VERSION ""

NS_ :

BS_:

BU_: SCCM RF_HUB PTS ORC OCM IC HCP HALF ETM ESM ESC EPS ECM EBCM DIAGNOST DASM CBC AirSusp TCM DTCM ELSDM

BO_ 3221225472 VECTOR__INDEPENDENT_SIG_MSG: 0 Vector__XXX
 SG_ CRC_10Eh : 56|8@1+ (1,0) [0|255] ""  DASM,ECM
 SG_ MC_10Eh : 52|4@1+ (1,0) [0|15] ""  DASM,ECM
 SG_ WhlTrq_Rq_As : 22|15@0+ (1,-7767) [-7767|24999] "Nm"  ORC,ECM
 SG_ WhlTrq_Rq_ESC : 6|15@0+ (1,-7767) [-7767|24999] "Nm"  ECM,DASM
 SG_ WhlTrqAct_Rq_AS : 23|1@1+ (1,0) [0|0] ""  ECM
 SG_ WhlTrqMax_Rq_ESC : 7|1@1+ (1,0) [0|0] ""  ECM,DASM
 SG_ WhlTrqMin_Rq_ESC : 51|1@1+ (1,0) [0|0] ""  ECM
 SG_ CRC_123h : 56|8@1+ (1,0) [0|255] ""  ESC,DASM
 SG_ M_MAX_AXLE : 4|13@0+ (4,-7767) [-7767|24993] ""  ESC,DASM
 SG_ M_MIN_AXLE : 36|13@0+ (4,-7767) [-7767|24993] ""  ESC,DASM
 SG_ M_STA_AXLE : 20|13@0+ (4,-7767) [-7767|24993] ""  ORC,ESC,DASM
 SG_ MC_123h : 52|4@1+ (1,0) [0|15] ""  ESC,DASM
 SG_ AXSStat : 4|2@1+ (1,0) [0|0] ""  HCP,ESC
 SG_ AYSStat : 6|2@1+ (1,0) [0|0] ""  ESC
 SG_ CRC_ORC_YRS_DATA : 56|8@1+ (1,0) [0|0] ""  ESC
 SG_ InternalError : 22|1@1+ (1,0) [0|0] ""  ESC
 SG_ LatAcceleration : 3|12@0+ (0.02,-40.96) [-40.96|40.92] "m/s²"  ESC
 SG_ LongAcceleration : 19|12@0+ (0.02,-40.96) [-40.96|40.92] "m/s²"  HCP,ESC
 SG_ MC_ORC_YRS_DATA : 52|4@1+ (1,0) [0|15] ""  ESC
 SG_ VoltageError : 23|1@1+ (1,0) [0|0] ""  ESC
 SG_ YawRate : 35|12@0+ (0.08,-163.84) [-163.84|163.68] "°/s"  ESC
 SG_ YRSStat : 20|2@1+ (1,0) [0|0] ""  ESC
 SG_ IMPACT_B : 1|1@1+ (1,0) [0|0] ""  ETM
 SG_ IMPACT_C : 2|1@1+ (1,0) [0|0] ""  ETM
 SG_ Impact_F : 5|1@1+ (1,0) [0|0] ""  ETM
 SG_ IMPACT_I : 9|1@1+ (1,0) [0|0] ""  ETM
 SG_ IMPACT_L : 11|1@1+ (1,0) [0|0] ""  ETM
 SG_ Impact_Tgl : 7|1@1+ (1,0) [0|0] ""  HCP,ETM,OCM,ECM,CBC
 SG_ IMPACT_X : 15|1@1+ (1,0) [0|0] ""  OCM,HCP,ETM,ECM,CBC
 SG_ ORC_Health : 23|1@1+ (1,0) [0|0] ""  HCP
 SG_ AirTemp_Outsd : 0|8@1+ (0.5,-40) [-40|85] "°C"  RF_HUB,EPS,ECM,DASM
 SG_ AMB_TEMP_AVG : 15|16@0+ (0.01,-40) [-40|85] "°C"  RF_HUB,PTS,OCM,ESC,EPS,ECM,DASM
 SG_ AMB_TEMP_VOLT : 24|8@1+ (0.019607843,0) [0|4.98] "Volts"  HCP,ECM
 SG_ BATT_VOLT : 48|8@1+ (0.1,0) [5|18] "Volts"  SCCM,RF_HUB,PTS,ORC,OCM,IC,HCP,HALF,ESM,ESC,EPS,ECM,EBCM,DASM
 SG_ FUEL_VOLT : 32|8@1+ (0.019607843,0) [0|4.98] "Volts"  IC,ECM
 SG_ FUEL_VOLT2 : 40|8@1+ (0.019607843,0) [0|4.98] "Volts"  IC
 SG_ rnd_04 : 32|8@1+ (1,0) [0|255] ""  CBC
 SG_ rnd_03 : 24|8@1+ (1,0) [0|255] ""  CBC
 SG_ rnd_02 : 16|8@1+ (1,0) [0|255] ""  CBC
 SG_ rnd_01 : 8|8@1+ (1,0) [0|255] ""  CBC
 SG_ f1_02 : 48|8@1+ (1,0) [0|255] ""  CBC
 SG_ f1_01 : 40|8@1+ (1,0) [0|255] ""  CBC
 SG_ ControlEncodingRq_HCP : 0|8@1+ (1,0) [0|0] ""  CBC
 SG_ MKKey2org22 : 16|8@1+ (1,0) [0|255] ""  ECM
 SG_ MKKey1org21 : 8|8@1+ (1,0) [0|255] ""  ECM
 SG_ MKKey_6 : 48|8@1+ (1,0) [0|255] ""  ECM
 SG_ MKKey_5 : 40|8@1+ (1,0) [0|255] ""  ECM
 SG_ MKKey_4 : 32|8@1+ (1,0) [0|255] ""  ECM
 SG_ MKKey_3 : 24|8@1+ (1,0) [0|255] ""  ECM
 SG_ ControlEncodingRsp : 0|8@1+ (1,0) [0|0] ""  ECM
 SG_ rnd_4 : 32|8@1+ (1,0) [0|255] ""  CBC
 SG_ rnd_3 : 24|8@1+ (1,0) [0|255] ""  CBC
 SG_ rnd_2 : 16|8@1+ (1,0) [0|255] ""  CBC
 SG_ rnd_1 : 8|8@1+ (1,0) [0|255] ""  CBC
 SG_ f1_2 : 48|8@1+ (1,0) [0|255] ""  CBC
 SG_ f1_1 : 40|8@1+ (1,0) [0|255] ""  CBC
 SG_ ControlEncodingRq : 0|8@1+ (1,0) [0|0] ""  CBC
 SG_ MKKey02org22 : 16|8@1+ (1,0) [0|255] ""  HCP
 SG_ MKKey01org21 : 8|8@1+ (1,0) [0|255] ""  HCP
 SG_ MKKey_06 : 48|8@1+ (1,0) [0|255] ""  HCP
 SG_ MKKey_05 : 40|8@1+ (1,0) [0|255] ""  HCP
 SG_ MKKey_04 : 32|8@1+ (1,0) [0|255] ""  HCP
 SG_ MKKey_03 : 24|8@1+ (1,0) [0|255] ""  HCP
 SG_ ControlEncoding_Rsp_HCP : 0|8@1+ (1,0) [0|0] ""  HCP
 SG_ ControlEncodingBCM : 0|8@1+ (1,0) [0|0] ""  RF_HUB
 SG_ MiniCrypt_Rnd : 31|32@0+ (1,0) [0|0] ""  RF_HUB
 SG_ MiniCryptFCode : 15|16@0+ (1,0) [0|0] ""  RF_HUB
 SG_ TxpAuthRequest : 63|1@1+ (1,0) [0|0] ""  RF_HUB
 SG_ TxpReadRequest : 62|1@1+ (1,0) [0|0] ""  RF_HUB
 SG_ MinicryptReceptionSts : 7|1@1+ (1,0) [0|0] ""  RF_HUB
 SG_ CodeCheckSts : 24|2@1+ (1,0) [0|0] ""  CBC
 SG_ ControlEncoding : 0|8@1+ (1,0) [0|0] ""  CBC
 SG_ MiniCryptGCode : 15|16@0+ (1,0) [0|0] ""  CBC
 SG_ ProgrammedSts : 26|1@1+ (1,0) [0|0] ""  CBC
 SG_ TxpFound : 31|1@1+ (1,0) [0|0] ""  CBC
 SG_ TxpID : 27|4@1+ (1,0) [0|0] ""  CBC
 SG_ DATA1 : 8|8@1+ (1,0) [0|0] ""  CBC
 SG_ DATA2 : 16|8@1+ (1,0) [0|0] ""  CBC
 SG_ DATA3 : 24|8@1+ (1,0) [0|0] ""  CBC
 SG_ DATA4 : 32|8@1+ (1,0) [0|0] ""  CBC
 SG_ DATA5 : 40|8@1+ (1,0) [0|0] ""  CBC
 SG_ DATA6 : 48|8@1+ (1,0) [0|0] ""  CBC
 SG_ DATA7 : 56|8@1+ (1,0) [0|0] ""  CBC
 SG_ FrameNumber : 0|4@1+ (1,0) [0|0] ""  CBC
 SG_ TotalFrameNumber : 4|4@1+ (1,0) [0|0] ""  CBC
 SG_ CRC_OCM_A1 : 56|8@1+ (1,0) [0|0] ""  ORC
 SG_ MC_OCM_A1 : 52|4@1+ (1,0) [0|15] ""  ORC
 SG_ PsgSeatOCFaultSts : 4|1@1+ (1,0) [0|0] ""  ORC
 SG_ PsgSeatOCSts : 0|4@1+ (1,0) [0|0] ""  ORC
 SG_ PsgSeatSBRSts : 8|4@1+ (1,0) [0|0] ""  ORC
 SG_ CRC_PRESF_CTRL_ESP : 56|8@1+ (1,0) [0|0] "" Vector__XXX
 SG_ MC_PRESF_CTRL_ESP : 52|4@1+ (1,0) [0|15] "" Vector__XXX
 SG_ BlockOffset : 0|8@1+ (1,0) [0|0] ""  ESC
 SG_ Character0 : 56|8@1+ (1,0) [0|0] ""  ESC
 SG_ Character1 : 48|8@1+ (1,0) [0|0] ""  ESC
 SG_ Character2 : 40|8@1+ (1,0) [0|0] ""  ESC
 SG_ Character3 : 32|8@1+ (1,0) [0|0] ""  ESC
 SG_ Character4 : 24|8@1+ (1,0) [0|0] ""  ESC
 SG_ Character5 : 16|8@1+ (1,0) [0|0] ""  ESC
 SG_ CLUType : 12|4@1+ (1,0) [0|0] ""  ESC
 SG_ PTRInfo : 8|4@1+ (1,0) [0|0] ""  ESC
 SG_ HCPCoachDisp : 40|8@1+ (1,-100) [-100|100] "%"  IC
 SG_ HCPCoachDispV : 30|1@1+ (1,0) [0|0] ""  IC
 SG_ HCPOutputPwr : 32|8@1+ (1,-100) [-100|100] "%"  IC
 SG_ HCPOutputPwrV : 29|1@1+ (1,0) [0|0] ""  IC
 SG_ HCPPopUpMessage1 : 8|1@1+ (1,0) [0|0] ""  IC
 SG_ HCPPopUpMessage2 : 9|1@1+ (1,0) [0|0] ""  IC
 SG_ HCPPopUpMessage3 : 10|1@1+ (1,0) [0|0] ""  IC
 SG_ HCPPopUpMessage4 : 11|1@1+ (1,0) [0|0] ""  IC
 SG_ HCPPopUpMessage5 : 12|1@1+ (1,0) [0|0] ""  IC
 SG_ HCPPopUpMessage6 : 13|1@1+ (1,0) [0|0] ""  IC
 SG_ HCPPopUpMessage7 : 14|1@1+ (1,0) [0|0] ""  IC
 SG_ HybSysEmsMlfAtv : 7|1@1+ (1,0) [0|0] "" Vector__XXX
 SG_ MIL_OnRq_HCP : 6|1@1+ (1,0) [0|0] ""  ECM
 SG_ CabinPreCondReqStat : 52|4@1+ (1,0) [0|0] ""  ETM
 SG_ ChargingLevel : 4|4@1+ (1,0) [0|0] ""  IC,ETM
 SG_ ChargingSysSts : 45|3@1+ (1,0) [0|0] ""  IC,ETM
 SG_ ChrgSysFault : 3|1@1+ (1,0) [0|0] ""  IC,ETM
 SG_ CompStat : 48|4@1+ (1,0) [0|0] ""  CBC
 SG_ DriveReady : 22|1@1+ (1,0) [0|0] ""  IC,DASM,CBC
 SG_ EstTimeofChrg_Lv1 : 20|13@0+ (1,0) [0|8190] "min"  IC,ETM
 SG_ EstTimeofChrg_Lv2 : 2|11@0+ (1,0) [0|2046] "min"  IC,ETM
 SG_ HtrCoreInletTemp : 32|8@1+ (1,-40) [-40|214] "°C"  ECM,CBC
 SG_ PrplsnSysAtv : 23|1@1+ (1,0) [0|0] ""  RF_HUB,PTS,IC,ETM,ESC,EPS,ECM,CBC
 SG_ CRC_EPB_A1 : 16|8@1+ (1,0) [0|0] ""  PTS,HCP,EPS,ECM,DASM
 SG_ EPBHoldSts : 9|3@1+ (1,0) [0|0] ""  PTS,ORC,HCP,ECM,DASM,CBC
 SG_ MC_EPB_A1 : 12|4@1+ (1,0) [0|15] ""  PTS,HCP,EPS,ECM,DASM
 SG_ UConnReq : 0|5@1+ (1,0) [0|0] ""  RF_HUB
 SG_ UConnReqAuthCode : 15|16@0+ (1,0) [0|0] ""  RF_HUB
 SG_ UConnReqFOBNum : 24|4@1+ (1,0) [0|0] ""  RF_HUB
 SG_ BatPwrUsage : 32|8@1+ (1,-125) [-125|130] "kW"  IC
 SG_ BatPwrUsage_V : 23|1@1+ (1,0) [0|0] ""  IC
 SG_ Est_Range : 40|8@1+ (1,0) [0|254] "km"  IC,ETM
 SG_ HEV_EVT_MD : 19|1@1+ (1,0) [0|0] ""  IC,ETM,CBC
 SG_ HEV_LMP_RQ : 0|2@1+ (1,0) [0|0] ""  ORC,IC,ETM
 SG_ R134a_PressSts : 48|9@0+ (0.1,0) [0|40] "bar"  CBC
 SG_ ElecClntHtrInletTemp : 32|8@1+ (1,-40) [-40|214] "°C"  ECM
 SG_ ElecCoolantHtrPwr : 24|8@1+ (0.04,0) [0|10.16] "kW"  ECM,CBC
 SG_ FRfShVlvSts : 23|1@1+ (1,0) [0|0] ""  CBC
 SG_ HTAuxPmpMontrngRPM : 19|2@1+ (1,0) [0|0] ""  ECM
 SG_ HTAuxPmpRPMAct : 0|8@1+ (24,0) [0|6096] "rpm"  ECM,CBC
 SG_ HTCabVlvPosn : 8|7@1+ (1,0) [0|100] "%"  ECM,CBC
 SG_ HTShtOffVlvReq : 22|1@1+ (1,0) [0|0] ""  ECM,CBC
 SG_ HVBatCritCondT : 21|1@1+ (1,0) [0|0] ""  CBC
 SG_ EC_BU_CBC15A : 2|6@1+ (1,0) [0|0] ""  CBC
 SG_ EC_BU_CBC15B : 15|40@0+ (1,0) [0|0] ""  CBC
 SG_ EC_BU_ECUCfg15_Stat : 0|2@1+ (1,0) [0|0] ""  CBC
 SG_ EC_BU_Suspension : 55|16@0+ (1,0) [0|0] ""  CBC
 SG_ EC_BU_AudTel3A : 2|6@1+ (1,0) [0|0] ""  CBC
 SG_ EC_BU_AudTel3B : 15|56@0+ (1,0) [0|0] ""  CBC
 SG_ EC_BU_ECUCfg16_Stat : 0|2@1+ (1,0) [0|0] ""  CBC
 SG_ EC_BU_ECUCfg17_Stat : 0|2@1+ (1,0) [0|0] ""  CBC
 SG_ EC_BU_PTS : 56|8@1+ (1,0) [0|0] ""  CBC
 SG_ AutoParkSts : 25|2@1+ (1,0) [0|0] ""  CBC
 SG_ ClampForce : 7|16@0+ (1,0) [0|65535] "N"  ORC
 SG_ CRC_EPB_1 : 56|8@1+ (1,0) [0|0] ""  IC,EPS,DASM
 SG_ EPBSts : 24|1@1+ (1,0) [0|0] ""  DASM
 SG_ EPBWarningLampReq : 46|2@1+ (1,0) [0|0] ""  ORC,IC
 SG_ FunctionLamp : 44|2@1+ (1,0) [0|0] ""  IC
 SG_ MC_EPB_1 : 52|4@1+ (1,0) [0|15] ""  IC,EPS,DASM
 SG_ ServiceModeSts : 30|1@1+ (1,0) [0|0] ""  CBC
 SG_ TextDisplay : 32|5@1+ (1,0) [0|0] ""  IC,CBC
 SG_ CFG_FEATURE : 0|8@1+ (1,0) [0|0] ""  RF_HUB,PTS,IC,HALF,ESC,ECM,DASM
 SG_ CFG_SET : 16|8@1+ (1,0) [0|255] ""  RF_HUB,PTS,IC,HALF,ESC,ECM,DASM
 SG_ CFG_STAT_RQ : 8|2@1+ (1,0) [0|0] ""  RF_HUB,PTS,IC,HALF,ESC,ECM,DASM
 SG_ AHB_ENBL : 36|1@1+ (1,0) [0|0] "" Vector__XXX
 SG_ ChargeReq : 55|1@1+ (1,0) [0|0] ""  IC,HCP
 SG_ HVAC_CLNT_FLW_MIN : 40|8@1+ (0.521555,0) [0.521555|131.953415] "LpM" Vector__XXX
 SG_ ICS_btn_16 : 51|1@1+ (1,0) [0|0] ""  PTS
 SG_ ICS_btn_17 : 52|1@1+ (1,0) [0|0] ""  PTS
 SG_ ICS_btn_18 : 53|1@1+ (1,0) [0|0] ""  HALF
 SG_ phone_pop_up_active : 30|1@1+ (1,0) [0|0] ""  IC
 SG_ PLG_Stat : 0|4@1+ (1,0) [0|0] ""  IC
 SG_ TRAC_PSD : 19|1@1+ (1,0) [0|0] ""  IC,ESC
 SG_ ECM_APPL2 : 7|64@0+ (1,0) [0|0] ""  ECM
 SG_ ECM_APPL1 : 7|64@0+ (1,0) [0|0] ""  DIAGNOST
 SG_ BatPwrUsageDisp : 8|8@1+ (1,-125) [-125|130] "kW"  ETM
 SG_ BatPwrUsageDisp_V : 44|1@1+ (1,0) [0|0] ""  ETM
 SG_ EngPwrUsageDisp : 49|10@0+ (1,0) [0|1023] "kW"  IC,ETM
 SG_ EngPwrUsageDisp_V : 45|1@1+ (1,0) [0|0] ""  IC,ETM
 SG_ HVACPwrUsageDisp : 24|7@1+ (1,0) [0|127] "kW"  ETM
 SG_ HVACPwrUsageDisp_V : 46|1@1+ (1,0) [0|0] ""  ETM
 SG_ HVBatSOC_HCP : 32|8@1+ (0.3922,0) [0|100] "%"  IC,ETM
 SG_ HVBatSOCV_HCP : 47|1@1+ (1,0) [0|0] ""  IC,ETM
 SG_ MtrPwrUsageDisp : 0|8@1+ (1,-125) [-125|130] "kW"  IC
 SG_ MtrPwrUsageDisp_V : 43|1@1+ (1,0) [0|0] ""  IC
 SG_ ECM_APPL3 : 7|64@0+ (1,0) [0|0] ""  DIAGNOST
 SG_ ECM_APPL4 : 7|64@0+ (1,0) [0|0] ""  DIAGNOST
 SG_ VC_BU_ABSM : 25|1@1+ (1,0) [0|0] ""  CBC
 SG_ VC_BU_ACC_Type : 19|2@1+ (1,0) [0|0] ""  CBC
 SG_ VC_BU_AS_ERS : 14|2@1+ (1,0) [0|0] ""  CBC
 SG_ VC_BU_AxleLockerPrsnt : 26|2@1+ (1,0) [0|0] ""  CBC
 SG_ VC_BU_DampingPrsnt : 22|1@1+ (1,0) [0|0] ""  CBC
 SG_ VC_BU_DST_Present : 5|1@1+ (1,0) [0|0] ""  CBC
 SG_ VC_BU_eShifter_Prsnt : 7|1@1+ (1,0) [0|0] ""  CBC
 SG_ VC_BU_FullSpeedRange_FCW : 18|1@1+ (1,0) [0|0] ""  CBC
 SG_ VC_BU_HybridType : 36|3@1+ (1,0) [0|0] ""  CBC
 SG_ VC_BU_LDW : 2|1@1+ (1,0) [0|0] ""  CBC
 SG_ VC_BU_PBTyp : 29|3@1+ (1,0) [0|0] ""  CBC
 SG_ VC_BU_PdlsMdPrsnt : 4|1@1+ (1,0) [0|0] ""  CBC
 SG_ VC_BU_RedKey : 24|1@1+ (1,0) [0|0] ""  CBC
 SG_ VC_BU_STP_PRSNT : 6|1@1+ (1,0) [0|0] ""  CBC
 SG_ VC_BU_SUNR_Prsnt : 47|1@1+ (1,0) [0|0] ""  CBC
 SG_ VC_BU_SuspPrsnt : 21|1@1+ (1,0) [0|0] ""  CBC
 SG_ VC_BU_SVC_Prsnt : 17|1@1+ (1,0) [0|0] ""  CBC
 SG_ VC_BU_TeenKey : 16|1@1+ (1,0) [0|0] ""  CBC
 SG_ VC_BU_TPMS_Configuration : 32|3@1+ (1,0) [0|0] ""  CBC
 SG_ VC_BU_Trans_Equipped : 28|1@1+ (1,0) [0|0] ""  CBC
 SG_ VC_BU_Trans_N_Hold_Prsnt : 23|1@1+ (1,0) [0|0] ""  CBC
 SG_ VC_BU_TransType : 8|6@1+ (1,0) [0|0] ""  CBC
 SG_ VC_BU_TrnsDrvMdPrsnt : 3|1@1+ (1,0) [0|0] ""  CBC
 SG_ VC_BU_TSBM_Prsnt : 39|1@1+ (1,0) [0|0] ""  CBC
 SG_ VC_BU_VehCfg7_Stat : 0|2@1+ (1,0) [0|0] ""  CBC
 SG_ GPS_Date_Day : 24|8@1+ (1,0) [1|31] "Days"  ECM
 SG_ GPS_Date_Month : 16|8@1+ (1,0) [1|12] "Months"  ECM
 SG_ GPS_Date_Year : 7|16@0+ (1,0) [0|65534] "Years"  ECM
 SG_ GPS_UTC_Hour : 32|8@1+ (1,0) [0|23] "h" Vector__XXX
 SG_ GPS_UTC_Minute : 40|8@1+ (1,0) [0|59] "min" Vector__XXX
 SG_ GPS_UTC_Second : 55|16@0+ (0.01,0) [0|59.99] "s" Vector__XXX
 SG_ ECM_APPL5 : 7|64@0+ (1,0) [0|0] ""  DIAGNOST
 SG_ NET_CFG_STAT_ePT : 0|2@1+ (1,0) [0|0] ""  RF_HUB,ORC,HCP,ESC,EBCM
 SG_ NetCfg_AHCP_ePT : 9|1@1+ (1,0) [0|0] ""  RF_HUB
 SG_ NetCfg_APM_ePT : 13|1@1+ (1,0) [0|0] ""  RF_HUB
 SG_ NetCfg_BPCM_ePT : 12|1@1+ (1,0) [0|0] ""  RF_HUB
 SG_ NetCfg_BSMO_ePT : 14|1@1+ (1,0) [0|0] ""  RF_HUB
 SG_ NetCfg_EAC_ePT : 11|1@1+ (1,0) [0|0] ""  RF_HUB
 SG_ NetCfg_EBCM_ePT : 2|1@1+ (1,0) [0|0] ""  RF_HUB
 SG_ NetCfg_ECM_ePT : 6|1@1+ (1,0) [0|0] ""  RF_HUB
 SG_ NetCfg_ESC_ePT : 5|1@1+ (1,0) [0|0] ""  RF_HUB
 SG_ NetCfg_ESM_ePT : 4|1@1+ (1,0) [0|0] ""  RF_HUB
 SG_ NetCfg_HCP_ePT : 7|1@1+ (1,0) [0|0] ""  RF_HUB
 SG_ NetCfg_OBCM_ePT : 8|1@1+ (1,0) [0|0] ""  RF_HUB
 SG_ NetCfg_ORC_ePT : 3|1@1+ (1,0) [0|0] ""  RF_HUB
 SG_ NetCfg_SCA_ePT : 10|1@1+ (1,0) [0|0] ""  RF_HUB
 SG_ BU_NetCfg_SCA_ePT : 10|1@1+ (1,0) [0|0] ""  CBC
 SG_ BU_NetCfg_ORC_ePT : 3|1@1+ (1,0) [0|0] ""  CBC
 SG_ BU_NetCfg_OBCM_ePT : 8|1@1+ (1,0) [0|0] ""  CBC
 SG_ BU_NetCfg_HCP_ePT : 7|1@1+ (1,0) [0|0] ""  CBC
 SG_ BU_NetCfg_ESM_ePT : 4|1@1+ (1,0) [0|0] ""  CBC
 SG_ BU_NetCfg_ESC_ePT : 5|1@1+ (1,0) [0|0] ""  CBC
 SG_ BU_NetCfg_ECM_ePT : 6|1@1+ (1,0) [0|0] ""  CBC
 SG_ BU_NetCfg_EBCM_ePT : 2|1@1+ (1,0) [0|0] ""  CBC
 SG_ BU_NetCfg_EAC_ePT : 11|1@1+ (1,0) [0|0] ""  CBC
 SG_ BU_NetCfg_BSMO_ePT : 14|1@1+ (1,0) [0|0] ""  CBC
 SG_ BU_NetCfg_BPCM_ePT : 12|1@1+ (1,0) [0|0] ""  CBC
 SG_ BU_NetCfg_APM_ePT : 13|1@1+ (1,0) [0|0] ""  CBC
 SG_ BU_NetCfg_AHCP_ePT : 9|1@1+ (1,0) [0|0] ""  CBC
 SG_ BU_NET_CFG_STAT_ePT : 0|2@1+ (1,0) [0|0] ""  CBC
 SG_ ECM_APPL6 : 7|64@0+ (1,0) [0|0] ""  DIAGNOST
 SG_ DateTmFormat2 : 0|3@1+ (1,0) [0|0] ""  IC
 SG_ WeekdayTmHour_End : 16|5@1+ (1,0) [0|24] "Hours"  IC
 SG_ WeekdayTmHour_Start : 8|5@1+ (1,0) [0|24] "Hours"  IC
 SG_ WeekdayTmMinute_End : 21|3@1+ (1,0) [0|0] "min"  IC
 SG_ WeekdayTmMinute_Start : 13|3@1+ (1,0) [0|0] "min"  IC
 SG_ WeekendTmHour_End : 32|5@1+ (1,0) [0|24] "Hours"  IC
 SG_ WeekendTmHour_Start : 24|5@1+ (1,0) [0|24] "Hours"  IC
 SG_ WeekendTmMinute_End : 37|3@1+ (1,0) [0|0] "min"  IC
 SG_ WeekendTmMinute_Start : 29|3@1+ (1,0) [0|0] "min"  IC
 SG_ ECM_APPL7 : 7|64@0+ (1,0) [0|0] ""  DIAGNOST
 SG_ VC_BU_ACC_DLY_CSO : 24|1@1+ (1,0) [0|0] ""  CBC
 SG_ VC_BU_AFLS_CSO : 25|1@1+ (1,0) [0|0] ""  CBC
 SG_ VC_BU_AMB_DMR_CSO : 26|1@1+ (1,0) [0|0] ""  CBC
 SG_ VC_BU_ASCM_TJ_CSO : 27|1@1+ (1,0) [0|0] ""  CBC
 SG_ VC_BU_ASCM_WRN_CSO : 28|1@1+ (1,0) [0|0] ""  CBC
 SG_ VC_BU_AUTO_AERO_CSO : 29|1@1+ (1,0) [0|0] ""  CBC
 SG_ VC_BU_AUTO_HB_CSO : 30|1@1+ (1,0) [0|0] ""  CBC
 SG_ VC_BU_AUTO_PRK_CSO : 31|1@1+ (1,0) [0|0] ""  CBC
 SG_ VC_BU_AUX_SWS_CSO : 18|2@1+ (1,0) [0|0] ""  CBC
 SG_ VC_BU_BLIND_SPOT_CSO : 32|1@1+ (1,0) [0|0] ""  CBC
 SG_ VC_BU_CAPACITY_CSO : 33|1@1+ (1,0) [0|0] ""  CBC
 SG_ VC_BU_CHMSL_LINE_CSO : 15|1@1+ (1,0) [0|0] ""  CBC
 SG_ VC_BU_CLK_DSP_CSO : 34|1@1+ (1,0) [0|0] ""  CBC
 SG_ VC_BU_CMP_CAL_CSO : 35|1@1+ (1,0) [0|0] ""  CBC
 SG_ VC_BU_CMP_VAR_CSO : 36|1@1+ (1,0) [0|0] ""  CBC
 SG_ VC_BU_CMRA_GRDLNS_CSO : 20|2@1+ (1,0) [0|0] ""  CBC
 SG_ VC_BU_CONS_CSO : 37|1@1+ (1,0) [0|0] ""  CBC
 SG_ VC_BU_DCS_CSO : 16|2@1+ (1,0) [0|0] ""  CBC
 SG_ VC_BU_DISTANCE_CSO : 38|1@1+ (1,0) [0|0] ""  CBC
 SG_ VC_BU_DR_LK_CSO : 39|1@1+ (1,0) [0|0] ""  CBC
 SG_ VC_BU_DR_UNLK_CSO : 40|1@1+ (1,0) [0|0] ""  CBC
 SG_ VC_BU_DRL_CSO : 41|1@1+ (1,0) [0|0] ""  CBC
 SG_ VC_BU_EASY_EXIT_CSO : 42|1@1+ (1,0) [0|0] ""  CBC
 SG_ VC_BU_ENTRY_EXIT_CSO : 43|1@1+ (1,0) [0|0] ""  CBC
 SG_ VC_BU_EPB_SERV_CSO : 44|1@1+ (1,0) [0|0] ""  CBC
 SG_ VC_BU_EPS_CSO : 7|1@1+ (1,0) [0|0] ""  CBC
 SG_ VC_BU_FCW_BRK_CSO : 10|1@1+ (1,0) [0|0] ""  CBC
 SG_ VC_BU_FCW_CSO : 8|2@1+ (1,0) [0|0] ""  CBC
 SG_ VC_BU_FLSH_LMP_LK_CSO : 45|1@1+ (1,0) [0|0] ""  CBC
 SG_ VC_BU_HL_DRP_CSO : 46|1@1+ (1,0) [0|0] ""  CBC
 SG_ VC_BU_HL_OFF_DLY_CSO : 47|1@1+ (1,0) [0|0] ""  CBC
 SG_ VC_BU_HL_WPR_CSO : 48|1@1+ (1,0) [0|0] ""  CBC
 SG_ VC_BU_HRN_RMT_LK_CSO : 11|2@1+ (1,0) [0|0] ""  CBC
 SG_ VC_BU_HRN_RMT_LWR_CSO : 14|1@1+ (1,0) [0|0] ""  CBC
 SG_ VC_BU_HRN_RMT_ST_CSO : 13|1@1+ (1,0) [0|0] ""  CBC
 SG_ VC_BU_HSA_CSO : 49|1@1+ (1,0) [0|0] ""  CBC
 SG_ VC_BU_ILL_APPRCH_CSO : 50|1@1+ (1,0) [0|0] ""  CBC
 SG_ VC_BU_LDW_TRQ_CSO : 51|1@1+ (1,0) [0|0] ""  CBC
 SG_ VC_BU_LDW_WRN_CSO : 52|1@1+ (1,0) [0|0] ""  CBC
 SG_ VC_BU_LGHT_RMT_LWR_CSO : 53|1@1+ (1,0) [0|0] ""  CBC
 SG_ VC_BU_NAV_TRN_CSO : 54|1@1+ (1,0) [0|0] ""  CBC
 SG_ VC_BU_PE_CSO : 55|1@1+ (1,0) [0|0] ""  CBC
 SG_ VC_BU_PER_SHFT_ENBL_CSO : 56|1@1+ (1,0) [0|0] ""  CBC
 SG_ VC_BU_PER_SHFT_RPM_CSO : 57|1@1+ (1,0) [0|0] ""  CBC
 SG_ VC_BU_PLG_CHM_CSO : 58|1@1+ (1,0) [0|0] ""  CBC
 SG_ VC_BU_POLICE_PE_CSO : 23|1@1+ (1,0) [0|0] ""  CBC
 SG_ VC_BU_POWER_CSO : 59|1@1+ (1,0) [0|0] ""  CBC
 SG_ VC_BU_PRESSURE_CSO : 60|1@1+ (1,0) [0|0] ""  CBC
 SG_ VC_BU_PRK_AST_BRK_CSO : 4|1@1+ (1,0) [0|0] ""  CBC
 SG_ VC_BU_PRK_AST_CSO : 2|2@1+ (1,0) [0|0] ""  CBC
 SG_ VC_BU_PRK_FT_VOL_CSO : 5|1@1+ (1,0) [0|0] ""  CBC
 SG_ VC_BU_PRK_RR_VOL_CSO : 6|1@1+ (1,0) [0|0] ""  CBC
 SG_ VC_BU_PTO_CSO : 61|1@1+ (1,0) [0|0] ""  CBC
 SG_ VC_BU_RAIN_WPR_CSO : 62|1@1+ (1,0) [0|0] ""  CBC
 SG_ VC_BU_REAR_CMRA_CSO : 63|1@1+ (1,0) [0|0] ""  CBC
 SG_ VC_BU_VehCfgCSO1_Stat : 0|2@1+ (1,0) [0|0] ""  CBC
 SG_ VC_BU_AIRBAG_ON_CSO : 46|1@1+ (1,0) [0|0] ""  CBC
 SG_ VC_BU_EPB_ON_CSO : 45|1@1+ (1,0) [0|0] ""  CBC
 SG_ VC_BU_FCW_SW_CSO : 47|1@1+ (1,0) [0|0] ""  CBC
 SG_ VC_BU_FLSH_LMP_SLDR_CSO : 40|1@1+ (1,0) [0|0] ""  CBC
 SG_ VC_BU_FUEL_SAV_CSO : 14|1@1+ (1,0) [0|0] ""  CBC
 SG_ VC_BU_HANDS_FREE_LFT_CSO : 18|1@1+ (1,0) [0|0] ""  CBC
 SG_ VC_BU_HANDS_FREE_SLDR_CSO : 19|1@1+ (1,0) [0|0] ""  CBC
 SG_ VC_BU_HOLD_N_GO_CSO : 16|1@1+ (1,0) [0|0] ""  CBC
 SG_ VC_BU_LDW_ON_CSO : 43|1@1+ (1,0) [0|0] ""  CBC
 SG_ VC_BU_PADDLE_SHIFT_CSO : 39|1@1+ (1,0) [0|0] ""  CBC
 SG_ VC_BU_PRK_ASST_TYPE_CSO : 44|1@1+ (1,0) [0|0] ""  CBC
 SG_ VC_BU_PWR_FLD_MRR_CSO : 17|1@1+ (1,0) [0|0] ""  CBC
 SG_ VC_BU_RDY_DRV_CSO : 55|1@1+ (1,0) [0|0] ""  CBC
 SG_ VC_BU_REAR_CMRA_DLY_CSO : 2|1@1+ (1,0) [0|0] ""  CBC
 SG_ VC_BU_RKE_MEM_CSO : 3|1@1+ (1,0) [0|0] ""  CBC
 SG_ VC_BU_RKE_UNLK_CSO : 4|1@1+ (1,0) [0|0] ""  CBC
 SG_ VC_BU_SLD_DR_ALRT_CSO : 22|1@1+ (1,0) [0|0] ""  CBC
 SG_ VC_BU_SLD_DR_CHM_CSO : 37|1@1+ (1,0) [0|0] ""  CBC
 SG_ VC_BU_SPEED_CSO : 5|1@1+ (1,0) [0|0] ""  CBC
 SG_ VC_BU_SPEED_WARNING_CSO : 41|2@1+ (1,0) [0|0] ""  CBC
 SG_ VC_BU_SVC_DELAY_CSO : 21|1@1+ (1,0) [0|0] ""  CBC
 SG_ VC_BU_SVC_GRIDLINES_CSO : 20|1@1+ (1,0) [0|0] ""  CBC
 SG_ VC_BU_TEEN_AUTO_HB_CSO : 33|1@1+ (1,0) [0|0] ""  CBC
 SG_ VC_BU_TEEN_BLIND_SPOT_CSO : 31|1@1+ (1,0) [0|0] ""  CBC
 SG_ VC_BU_TEEN_FCW_BRK_CSO : 24|1@1+ (1,0) [0|0] ""  CBC
 SG_ VC_BU_TEEN_FCW_SENS_CSO : 23|1@1+ (1,0) [0|0] ""  CBC
 SG_ VC_BU_TEEN_FT_PRK_VOL_CSO : 26|1@1+ (1,0) [0|0] ""  CBC
 SG_ VC_BU_TEEN_FUEL_POPUP_CSO : 30|1@1+ (1,0) [0|0] ""  CBC
 SG_ VC_BU_TEEN_FUEL_WRN_CSO : 29|1@1+ (1,0) [0|0] ""  CBC
 SG_ VC_BU_TEEN_LGHT_WPR_CSO : 34|1@1+ (1,0) [0|0] ""  CBC
 SG_ VC_BU_TEEN_MAX_SPEED_CSO : 28|1@1+ (1,0) [0|0] ""  CBC
 SG_ VC_BU_TEEN_PLG_CHIME_CSO : 36|1@1+ (1,0) [0|0] ""  CBC
 SG_ VC_BU_TEEN_PRK_ASST_CSO : 25|1@1+ (1,0) [0|0] ""  CBC
 SG_ VC_BU_TEEN_RAIN_WPR_CSO : 32|1@1+ (1,0) [0|0] ""  CBC
 SG_ VC_BU_TEEN_RR_PRK_VOL_CSO : 27|1@1+ (1,0) [0|0] ""  CBC
 SG_ VC_BU_TEEN_SLD_DR_ALRT_CSO : 35|1@1+ (1,0) [0|0] ""  CBC
 SG_ VC_BU_TEEN_SLD_DR_CHM_CSO : 38|1@1+ (1,0) [0|0] ""  CBC
 SG_ VC_BU_TEMP_CSO : 15|1@1+ (1,0) [0|0] ""  CBC
 SG_ VC_BU_TLT_MRR_CSO : 6|1@1+ (1,0) [0|0] ""  CBC
 SG_ VC_BU_TORQUE_CSO : 7|1@1+ (1,0) [0|0] ""  CBC
 SG_ VC_BU_TRLR_CSO : 8|1@1+ (1,0) [0|0] ""  CBC
 SG_ VC_BU_TRLR_NAME_CSO : 9|1@1+ (1,0) [0|0] ""  CBC
 SG_ VC_BU_TRLR_TYPE_CSO : 10|1@1+ (1,0) [0|0] ""  CBC
 SG_ VC_BU_TRNS_MD_CSO : 11|1@1+ (1,0) [0|0] ""  CBC
 SG_ VC_BU_US_METRIC_CSO : 12|1@1+ (1,0) [0|0] ""  CBC
 SG_ VC_BU_VehCfgCSO2_Stat : 0|2@1+ (1,0) [0|0] ""  CBC
 SG_ VC_BU_WHL_ALGN_CSO : 13|1@1+ (1,0) [0|0] ""  CBC
 SG_ NAV_GrpNum : 4|4@1+ (1,1) [1|16] "Group"  IC
 SG_ NAV_GrpTyp : 8|6@1+ (1,0) [1|40] "Text"  IC
 SG_ NAV_HiGrpMark : 14|1@1+ (1,0) [0|0] ""  IC
 SG_ NAV_TEXT : 23|48@0+ (1,0) [0|0] ""  IC
 SG_ Electric_Dist_Miles : 1|10@0+ (1,0) [0|999] "Mile"  ETM
 SG_ Hybrid_Dist_Miles : 17|10@0+ (1,0) [0|999] "Mile"  ETM
 SG_ Electric_Dist_Kilometers : 1|10@0+ (1,0) [0|999] "km"  ETM
 SG_ Hybrid_Dist_Kilometers : 17|10@0+ (1,0) [0|999] "km"  ETM
 SG_ EC_BU_ECUCfg14_Stat : 0|2@1+ (1,0) [0|0] ""  CBC
 SG_ EC_BU_CBC14B : 15|56@0+ (1,0) [0|0] ""  CBC
 SG_ EC_BU_CBC14A : 2|6@1+ (1,0) [0|0] ""  CBC
 SG_ EC_BU_ECUCfg13_Stat : 0|2@1+ (1,0) [0|0] ""  CBC
 SG_ EC_BU_CBC13B : 15|56@0+ (1,0) [0|0] ""  CBC
 SG_ EC_BU_CBC13A : 2|6@1+ (1,0) [0|0] ""  CBC
 SG_ EC_BU_ECUCfg12_Stat : 0|2@1+ (1,0) [0|0] ""  CBC
 SG_ EC_BU_Cluster5C : 39|32@0+ (1,0) [0|0] ""  CBC
 SG_ EC_BU_Cluster5B : 15|24@0+ (1,0) [0|0] ""  CBC
 SG_ EC_BU_Cluster5A : 2|6@1+ (1,0) [0|0] ""  CBC
 SG_ EC_BU_ECUCfg11_Stat : 0|2@1+ (1,0) [0|0] ""  CBC
 SG_ EC_BU_CBC11 : 39|32@0+ (1,0) [0|0] ""  CBC
 SG_ EC_BU_CBC10B : 15|24@0+ (1,0) [0|0] ""  CBC
 SG_ EC_BU_CBC10A : 2|6@1+ (1,0) [0|0] ""  CBC
 SG_ EC_BU_ECUCfg10_Stat : 0|2@1+ (1,0) [0|0] ""  CBC
 SG_ EC_BU_Cluster4 : 39|32@0+ (1,0) [0|0] ""  CBC
 SG_ EC_BU_Cluster3B : 15|24@0+ (1,0) [0|0] ""  CBC
 SG_ EC_BU_Cluster3A : 2|6@1+ (1,0) [0|0] ""  CBC
 SG_ EC_BU_ITM : 55|16@0+ (1,0) [0|0] ""  CBC
 SG_ EC_BU_ECUCfg9_Stat : 0|2@1+ (1,0) [0|0] ""  CBC
 SG_ EC_BU_CBC9B : 39|16@0+ (1,0) [0|0] ""  CBC
 SG_ EC_BU_CBC9A2 : 15|24@0+ (1,0) [0|0] ""  CBC
 SG_ EC_BU_CBC9A1 : 2|6@1+ (1,0) [0|0] ""  CBC
 SG_ BU_NetCfg_VTM : 13|1@1+ (1,0) [0|0] ""  CBC
 SG_ BU_NetCfg_VSIM : 22|1@1+ (1,0) [0|0] ""  CBC
 SG_ BU_NetCfg_VRM : 36|1@1+ (1,0) [0|0] ""  CBC
 SG_ BU_NetCfg_VES3_I : 29|1@1+ (1,0) [0|0] ""  CBC
 SG_ BU_NetCfg_VES2_I : 28|1@1+ (1,0) [0|0] ""  CBC
 SG_ BU_NetCfg_TMM : 33|1@1+ (1,0) [0|0] ""  CBC
 SG_ BU_NetCfg_TGW : 20|1@1+ (1,0) [0|0] ""  CBC
 SG_ BU_NetCfg_TBM : 38|1@1+ (1,0) [0|0] ""  CBC
 SG_ BU_NetCfg_RBSS : 2|1@1+ (1,0) [0|0] ""  CBC
 SG_ BU_NetCfg_RBC : 18|1@1+ (1,0) [0|0] ""  CBC
 SG_ BU_NetCfg_PTCM : 17|1@1+ (1,0) [0|0] ""  CBC
 SG_ BU_NetCfg_PSD_RT : 15|1@1+ (1,0) [0|0] ""  CBC
 SG_ BU_NetCfg_PSD_LT : 14|1@1+ (1,0) [0|0] ""  CBC
 SG_ BU_NetCfg_PLG : 12|1@1+ (1,0) [0|0] ""  CBC
 SG_ BU_NetCfg_MSM_PASS : 35|1@1+ (1,0) [0|0] ""  CBC
 SG_ BU_NetCfg_MSM : 11|1@1+ (1,0) [0|0] ""  CBC
 SG_ BU_NetCfg_ITM : 23|1@1+ (1,0) [0|0] ""  CBC
 SG_ BU_NetCfg_ICS_R : 34|1@1+ (1,0) [0|0] ""  CBC
 SG_ BU_NetCfg_ICS_I : 27|1@1+ (1,0) [0|0] ""  CBC
 SG_ BU_NetCfg_HVAC_R : 31|1@1+ (1,0) [0|0] ""  CBC
 SG_ BU_NetCfg_HVAC : 10|1@1+ (1,0) [0|0] ""  CBC
 SG_ BU_NetCfg_HFM_CTM : 26|1@1+ (1,0) [0|0] ""  CBC
 SG_ BU_NetCfg_FSM : 16|1@1+ (1,0) [0|0] ""  CBC
 SG_ BU_NetCfg_DVD_CDM : 25|1@1+ (1,0) [0|0] ""  CBC
 SG_ BU_NetCfg_DTV : 19|1@1+ (1,0) [0|0] ""  CBC
 SG_ BU_NetCfg_DCSD : 37|1@1+ (1,0) [0|0] ""  CBC
 SG_ BU_NetCfg_DCM_RR : 9|1@1+ (1,0) [0|0] ""  CBC
 SG_ BU_NetCfg_DCM_RL : 8|1@1+ (1,0) [0|0] ""  CBC
 SG_ BU_NetCfg_DCM_PASS : 7|1@1+ (1,0) [0|0] ""  CBC
 SG_ BU_NetCfg_DCM_DR : 6|1@1+ (1,0) [0|0] ""  CBC
 SG_ BU_NetCfg_CVPM : 32|1@1+ (1,0) [0|0] ""  CBC
 SG_ BU_NetCfg_CSWM : 5|1@1+ (1,0) [0|0] ""  CBC
 SG_ BU_NetCfg_CRSM : 30|1@1+ (1,0) [0|0] ""  CBC
 SG_ BU_NetCfg_CLOCK : 21|1@1+ (1,0) [0|0] ""  CBC
 SG_ BU_NetCfg_CBC_IN : 4|1@1+ (1,0) [0|0] ""  CBC
 SG_ BU_NetCfg_BSM : 3|1@1+ (1,0) [0|0] ""  CBC
 SG_ BU_NetCfg_ANC_I : 39|1@1+ (1,0) [0|0] ""  CBC
 SG_ BU_NetCfg_AMP_I : 24|1@1+ (1,0) [0|0] ""  CBC
 SG_ BU_NET_CFG_STAT_INT : 0|2@1+ (1,0) [0|0] ""  CBC
 SG_ BU_NetCfg_VSIM_C : 5|1@1+ (1,0) [0|0] ""  CBC
 SG_ BU_NetCfg_TPM : 26|1@1+ (1,0) [0|0] ""  CBC
 SG_ BU_NetCfg_TCM : 25|1@1+ (1,0) [0|0] ""  CBC
 SG_ BU_NetCfg_SCCM : 23|1@1+ (1,0) [0|0] ""  CBC
 SG_ BU_NetCfg_RF_HUB : 14|1@1+ (1,0) [0|0] ""  CBC
 SG_ BU_NetCfg_PTS : 20|1@1+ (1,0) [0|0] ""  CBC
 SG_ BU_NetCfg_PASS_PT : 27|1@1+ (1,0) [0|0] ""  CBC
 SG_ BU_NetCfg_ORC : 19|1@1+ (1,0) [0|0] ""  CBC
 SG_ BU_NetCfg_OCM : 30|1@1+ (1,0) [0|0] ""  CBC
 SG_ BU_NetCfg_ITBM : 29|1@1+ (1,0) [0|0] ""  CBC
 SG_ BU_NetCfg_IC : 15|1@1+ (1,0) [0|0] ""  CBC
 SG_ BU_NetCfg_HCP : 38|1@1+ (1,0) [0|0] ""  CBC
 SG_ BU_NetCfg_HaLF : 31|1@1+ (1,0) [0|0] ""  CBC
 SG_ BU_NetCfg_FDCM : 17|1@1+ (1,0) [0|0] ""  CBC
 SG_ BU_NetCfg_ESM : 11|1@1+ (1,0) [0|0] ""  CBC
 SG_ BU_NetCfg_ESL : 37|1@1+ (1,0) [0|0] ""  CBC
 SG_ BU_NetCfg_ESC : 12|1@1+ (1,0) [0|0] ""  CBC
 SG_ BU_NetCfg_EPS : 10|1@1+ (1,0) [0|0] ""  CBC
 SG_ BU_NetCfg_EPPM : 18|1@1+ (1,0) [0|0] ""  CBC
 SG_ BU_NetCfg_EPB : 13|1@1+ (1,0) [0|0] ""  CBC
 SG_ BU_NetCfg_ELSD : 24|1@1+ (1,0) [0|0] ""  CBC
 SG_ BU_NetCfg_ECM : 9|1@1+ (1,0) [0|0] ""  CBC
 SG_ BU_NetCfg_DTCM : 8|1@1+ (1,0) [0|0] ""  CBC
 SG_ BU_NetCfg_DASM : 16|1@1+ (1,0) [0|0] ""  CBC
 SG_ BU_NetCfg_CBC_PT : 7|1@1+ (1,0) [0|0] ""  CBC
 SG_ BU_NetCfg_BSMO : 36|1@1+ (1,0) [0|0] ""  CBC
 SG_ BU_NetCfg_ASCM : 6|1@1+ (1,0) [0|0] ""  CBC
 SG_ BU_NetCfg_ANC : 39|1@1+ (1,0) [0|0] ""  CBC
 SG_ BU_NetCfg_AHLM : 4|1@1+ (1,0) [0|0] ""  CBC
 SG_ BU_NetCfg_AFLS : 28|1@1+ (1,0) [0|0] ""  CBC
 SG_ BU_NetCfg_ADCM : 3|1@1+ (1,0) [0|0] ""  CBC
 SG_ BU_NetCfg_ACC : 2|1@1+ (1,0) [0|0] ""  CBC
 SG_ BU_NET_CFG_STAT_PT : 0|2@1+ (1,0) [0|0] ""  CBC
 SG_ VC_BU_XWD : 24|2@1+ (1,0) [0|0] ""  CBC
 SG_ VC_BU_VehCfg1_Stat : 0|2@1+ (1,0) [0|0] ""  CBC
 SG_ VC_BU_VEH_LINE : 8|8@1+ (1,0) [0|0] ""  CBC
 SG_ VC_BU_SSC_Prsnt : 63|1@1+ (1,0) [0|0] ""  CBC
 SG_ VC_BU_SpecialPKG : 48|8@1+ (1,0) [1|254] ""  CBC
 SG_ VC_BU_ShftrTyp : 40|4@1+ (1,0) [0|0] ""  CBC
 SG_ VC_BU_SCR_Prsnt : 57|1@1+ (1,0) [0|0] ""  CBC
 SG_ VC_BU_RVCM_Prsnt : 60|1@1+ (1,0) [0|0] ""  CBC
 SG_ VC_BU_RemStPrsnt : 23|1@1+ (1,0) [0|0] ""  CBC
 SG_ VC_BU_PTS_DispTyp : 44|3@1+ (1,0) [0|0] ""  CBC
 SG_ VC_BU_PTS_Config : 58|2@1+ (1,0) [0|0] ""  CBC
 SG_ VC_BU_PP_Prsnt : 47|1@1+ (1,0) [0|0] ""  CBC
 SG_ VC_BU_MODEL_YEAR : 2|6@1+ (1,2000) [2000|2062] "model-year"  CBC
 SG_ VC_BU_MAX_VEH_SPD : 32|8@1+ (2,0) [0|506] "kph"  CBC
 SG_ VC_BU_LHD_RHD : 21|2@1+ (1,0) [0|0] ""  CBC
 SG_ VC_BU_HdRstPrsnt : 56|1@1+ (1,0) [0|0] ""  CBC
 SG_ VC_BU_HDC_Prsnt : 62|1@1+ (1,0) [0|0] ""  CBC
 SG_ VC_BU_EmodePrsnt : 26|1@1+ (1,0) [0|0] ""  CBC
 SG_ VC_BU_COUNTRY : 16|5@1+ (1,0) [0|0] ""  CBC
 SG_ VC_BU_CHMCM_Prsnt : 61|1@1+ (1,0) [0|0] ""  CBC
 SG_ VC_BU_BODY_STYLE : 28|4@1+ (1,0) [0|0] ""  CBC
 SG_ VC_BU_AUTO_HB : 27|1@1+ (1,0) [0|0] ""  CBC
 SG_ VC_BU_VehCfg2_Stat : 0|2@1+ (1,0) [0|0] ""  CBC
 SG_ VC_BU_ThatchamPrsnt : 4|1@1+ (1,0) [0|0] ""  CBC
 SG_ VC_BU_SpecialPKG_IC : 16|8@1+ (1,0) [0|0] ""  CBC
 SG_ VC_BU_SKIM_PRSNT : 10|1@1+ (1,0) [0|0] ""  CBC
 SG_ VC_BU_ShftInd_Prsnt : 30|2@1+ (1,0) [0|0] ""  CBC
 SG_ VC_BU_SecPrkPrsnt : 29|1@1+ (1,0) [0|0] ""  CBC
 SG_ VC_BU_RunFlatTirePrsnt : 5|1@1+ (1,0) [0|0] ""  CBC
 SG_ VC_BU_RainSnsPrsnt : 9|1@1+ (1,0) [0|0] ""  CBC
 SG_ VC_BU_PwrIvtrTyp : 2|2@1+ (1,0) [0|0] ""  CBC
 SG_ VC_BU_PADS_Prsnt : 8|1@1+ (1,0) [0|0] ""  CBC
 SG_ VC_BU_OffRoad : 15|1@1+ (1,0) [0|0] ""  CBC
 SG_ VC_BU_MemoryDRVMD_Prsnt : 26|1@1+ (1,0) [0|0] ""  CBC
 SG_ VC_BU_MaxLdPressRrTr : 32|8@1+ (1,0) [0|126] "psi"  CBC
 SG_ VC_BU_MaxLdPressFtTr : 40|8@1+ (1,0) [0|126] "psi"  CBC
 SG_ VC_BU_MaseratiMd : 6|2@1+ (1,0) [0|0] ""  CBC
 SG_ VC_BU_LgtLdPressRrTr : 48|8@1+ (1,0) [0|126] "psi"  CBC
 SG_ VC_BU_LgtLdPressFtTr : 56|8@1+ (1,0) [0|126] "psi"  CBC
 SG_ VC_BU_FULL_SPARE : 14|1@1+ (1,0) [0|0] ""  CBC
 SG_ VC_BU_FG_PRSNT : 13|1@1+ (1,0) [0|0] ""  CBC
 SG_ VC_BU_ESCDrvMd_Prsnt : 27|1@1+ (1,0) [0|0] ""  CBC
 SG_ VC_BU_EngPowerDrvMd_Prsnt : 28|1@1+ (1,0) [0|0] ""  CBC
 SG_ VC_BU_ECO_Indicator : 24|1@1+ (1,0) [0|0] ""  CBC
 SG_ VC_BU_DRVMD_Prsnt : 25|1@1+ (1,0) [0|0] ""  CBC
 SG_ VC_BU_CRUISE_PRSNT : 12|1@1+ (1,0) [0|0] ""  CBC
 SG_ VC_BU_AC_Prsnt : 11|1@1+ (1,0) [0|0] ""  CBC
 SG_ VC_BU_WIN_EXPR_FEAT : 24|2@1+ (1,0) [0|0] ""  CBC
 SG_ VC_BU_WHL_BASE : 12|2@1+ (1,0) [0|0] ""  CBC
 SG_ VC_BU_VehCfg3_Stat : 0|2@1+ (1,0) [0|0] ""  CBC
 SG_ VC_BU_VEH_BRAND : 44|4@1+ (1,0) [0|0] ""  CBC
 SG_ VC_BU_TEMP_DISP : 39|1@1+ (1,0) [0|0] ""  CBC
 SG_ VC_BU_TcaseTyp : 8|4@1+ (1,0) [0|0] ""  CBC
 SG_ VC_BU_SunShade_Present : 7|1@1+ (1,0) [0|0] ""  CBC
 SG_ VC_BU_SRT_PRSNT : 30|1@1+ (1,0) [0|0] ""  CBC
 SG_ VC_BU_SPORT_PRSNT : 60|1@1+ (1,0) [0|0] ""  CBC
 SG_ VC_BU_SecLkPrsnt : 52|1@1+ (1,0) [0|0] ""  CBC
 SG_ VC_BU_RKE_PRSNT : 6|1@1+ (1,0) [0|0] ""  CBC
 SG_ VC_BU_PWR_RT_SLDR : 4|1@1+ (1,0) [0|0] ""  CBC
 SG_ VC_BU_PWR_LT_SLDR : 5|1@1+ (1,0) [0|0] ""  CBC
 SG_ VC_BU_PWR_LFT_GT : 3|1@1+ (1,0) [0|0] ""  CBC
 SG_ VC_BU_Prem_TPM : 58|1@1+ (1,0) [0|0] ""  CBC
 SG_ VC_BU_POLICE : 2|1@1+ (1,0) [0|0] ""  CBC
 SG_ VC_BU_PE_Prsnt : 62|1@1+ (1,0) [0|0] ""  CBC
 SG_ VC_BU_PDDL_PRSNT : 59|1@1+ (1,0) [0|0] ""  CBC
 SG_ VC_BU_Liftgate_Trunk : 53|2@1+ (1,0) [0|0] ""  CBC
 SG_ VC_BU_KG_Prsnt : 63|1@1+ (1,0) [0|0] ""  CBC
 SG_ VC_BU_IntEC_MIRR : 49|1@1+ (1,0) [0|0] ""  CBC
 SG_ VC_BU_HVAC_Config : 40|4@1+ (1,0) [0|0] ""  CBC
 SG_ VC_BU_HID_HL : 51|1@1+ (1,0) [0|0] ""  CBC
 SG_ VC_BU_FUEL_CAP : 16|8@1+ (1,36) [36|290] "liters"  CBC
 SG_ VC_BU_FOBIKsafeENBL : 14|1@1+ (1,0) [0|0] ""  CBC
 SG_ VC_BU_FCW : 56|1@1+ (1,0) [0|0] ""  CBC
 SG_ VC_BU_ESCL_Prsnt : 50|1@1+ (1,0) [0|0] ""  CBC
 SG_ VC_BU_ELV_PRSNT : 15|1@1+ (1,0) [0|0] ""  CBC
 SG_ VC_BU_DualFuelSens : 29|1@1+ (1,0) [0|0] ""  CBC
 SG_ VC_BU_DSBL_CLK_DISP : 31|1@1+ (1,0) [0|0] ""  CBC
 SG_ VC_BU_DrAlrPrsnt : 28|1@1+ (1,0) [0|0] ""  CBC
 SG_ VC_BU_CMS : 55|1@1+ (1,0) [0|0] ""  CBC
 SG_ VC_BU_CMP_DISP : 48|1@1+ (1,0) [0|0] ""  CBC
 SG_ VC_BU_ChassisType : 32|7@1+ (1,0) [0|126] ""  CBC
 SG_ VC_BU_Base_TPM : 57|1@1+ (1,0) [0|0] ""  CBC
 SG_ VC_BU_AutoParkPrsnt : 61|1@1+ (1,0) [0|0] ""  CBC
 SG_ VC_BU_AUTO_HL : 27|1@1+ (1,0) [0|0] ""  CBC
 SG_ VC_BU_ADJ_PDL_PRSNT : 26|1@1+ (1,0) [0|0] ""  CBC
 SG_ VC_BU_VehCfg4_Stat : 6|2@1+ (1,0) [0|0] ""  CBC
 SG_ VC_BU_TIRE_CIRCUMF : 55|16@0+ (1,0) [0|65534] "mm"  CBC
 SG_ VC_BU_TCASE_LO_RATIO : 39|16@0+ (0.001,0) [0|65.534] ""  CBC
 SG_ VC_BU_TCASE_HI_RATIO : 5|14@0+ (0.001,0) [0|16.382] ""  CBC
 SG_ VC_BU_AXLE_RATIO : 23|16@0+ (0.001,0) [0|65.534] ""  CBC
 SG_ EC_BU_ECUCfg1_Stat : 0|2@1+ (1,0) [0|0] ""  CBC
 SG_ EC_BU_CBC2 : 39|32@0+ (1,0) [0|0] ""  CBC
 SG_ EC_BU_CBC1B : 15|24@0+ (1,0) [0|0] ""  CBC
 SG_ EC_BU_CBC1A : 2|6@1+ (1,0) [0|0] ""  CBC
 SG_ EC_BU_ECUCfg2_Stat : 0|2@1+ (1,0) [0|0] ""  CBC
 SG_ EC_BU_CBC4 : 39|32@0+ (1,0) [0|0] ""  CBC
 SG_ EC_BU_CBC3B : 15|24@0+ (1,0) [0|0] ""  CBC
 SG_ EC_BU_CBC3A : 2|6@1+ (1,0) [0|0] ""  CBC
 SG_ EC_BU_ECUCfg3_Stat : 0|2@1+ (1,0) [0|0] ""  CBC
 SG_ EC_BU_AudTel2 : 39|32@0+ (1,0) [0|0] ""  CBC
 SG_ EC_BU_AudTel1B : 15|24@0+ (1,0) [0|0] ""  CBC
 SG_ EC_BU_AudTel1A : 2|6@1+ (1,0) [0|0] ""  CBC
 SG_ EC_BU_ECUCfg4_Stat : 0|2@1+ (1,0) [0|0] ""  CBC
 SG_ EC_BU_Cluster2 : 39|32@0+ (1,0) [0|0] ""  CBC
 SG_ EC_BU_Cluster1B : 15|24@0+ (1,0) [0|0] ""  CBC
 SG_ EC_BU_Cluster1A : 2|6@1+ (1,0) [0|0] ""  CBC
 SG_ EC_BU_WirelessB : 15|16@0+ (1,0) [0|0] ""  CBC
 SG_ EC_BU_WirelessA : 2|6@1+ (1,0) [0|0] ""  CBC
 SG_ EC_BU_Memory : 55|16@0+ (1,0) [0|0] ""  CBC
 SG_ EC_BU_ECUCfg5_Stat : 0|2@1+ (1,0) [0|0] ""  CBC
 SG_ EC_BU_Doors : 31|24@0+ (1,0) [0|0] ""  CBC
 SG_ EC_BU_Steering : 23|16@0+ (1,0) [0|0] ""  CBC
 SG_ EC_BU_Safety : 55|16@0+ (1,0) [0|0] ""  CBC
 SG_ EC_BU_Powertrain : 39|16@0+ (1,0) [0|0] ""  CBC
 SG_ EC_BU_ECUCfg6_Stat : 0|2@1+ (1,0) [0|0] ""  CBC
 SG_ EC_BU_BrakesB : 8|8@1+ (1,0) [0|0] ""  CBC
 SG_ EC_BU_BrakesA : 2|6@1+ (1,0) [0|0] ""  CBC
 SG_ EC_BU_ECUCfg7_Stat : 0|2@1+ (1,0) [0|0] ""  CBC
 SG_ EC_BU_CBC6 : 39|32@0+ (1,0) [0|0] ""  CBC
 SG_ EC_BU_CBC5B : 15|24@0+ (1,0) [0|0] ""  CBC
 SG_ EC_BU_CBC5A : 2|6@1+ (1,0) [0|0] ""  CBC
 SG_ EC_BU_ECUCfg8_Stat : 0|2@1+ (1,0) [0|0] ""  CBC
 SG_ EC_BU_CBC8 : 39|32@0+ (1,0) [0|0] ""  CBC
 SG_ EC_BU_CBC7B : 15|24@0+ (1,0) [0|0] ""  CBC
 SG_ EC_BU_CBC7A : 2|6@1+ (1,0) [0|0] ""  CBC
 SG_ WakeupRsn_HCP m2 : 32|8@1+ (1,0) [0|0] ""  EBCM,HCP,ESM,ESC,SCCM,EPS,IC,CBC,RF_HUB
 SG_ WakeupCnt_HCP m2 : 40|8@1+ (1,0) [0|254] ""  EBCM,HCP,ESM,ESC,SCCM,EPS,IC,CBC,RF_HUB
 SG_ Nw_Id_HCP : 56|8@1+ (1,0) [0|0] ""  EBCM,HCP,ESM,ESC,SCCM,EPS,IC,CBC,RF_HUB
 SG_ NM_Ud_Srv_HCP M : 24|8@1+ (1,0) [0|0] ""  EBCM,HCP,ESM,ESC,SCCM,EPS,IC,CBC,RF_HUB
 SG_ NM_Ud_Launch_HCP : 16|6@1+ (1,0) [0|0] ""  EBCM,HCP,ESM,ESC,SCCM,EPS,IC,CBC,RF_HUB
 SG_ NM_Successor_HCP : 8|8@1+ (1,0) [0|63] ""  EBCM,HCP,ESM,ESC,SCCM,EPS,IC,CBC,RF_HUB
 SG_ NM_Sleep_Ind_HCP : 23|1@1+ (1,0) [0|0] ""  EBCM,HCP,ESM,ESC,SCCM,EPS,IC,CBC,RF_HUB
 SG_ NM_Sleep_Ack_HCP : 22|1@1+ (1,0) [0|0] ""  EBCM,HCP,ESM,ESC,SCCM,EPS,IC,CBC,RF_HUB
 SG_ NM_Mode_HCP : 0|8@1+ (1,0) [0|0] ""  EBCM,HCP,ESM,ESC,SCCM,EPS,IC,CBC,RF_HUB
 SG_ Awake_NwSt_HCP m15 : 32|1@1+ (1,0) [0|0] ""  EBCM,HCP,ESM,ESC,SCCM,EPS,IC,CBC,RF_HUB
 SG_ Awake_Diag_Actv_HCP m15 : 33|1@1+ (1,0) [0|0] ""  EBCM,HCP,ESM,ESC,SCCM,EPS,IC,CBC,RF_HUB
 SG_ DG_RQ_GLOBAL_UDS : 7|64@0+ (1,0) [0|0] ""  EBCM,HCP,ETM,HALF,OCM,ORC,ESM,ECM,DASM,ESC,SCCM,EPS,PTS,IC,CBC,RF_HUB
 SG_ VC_BU_VehCfg6_Stat : 0|2@1+ (1,0) [0|0] ""  CBC
 SG_ VC_BU_TireCircumfFT : 55|16@0+ (1,0) [0|65534] "mm"  CBC
 SG_ VC_BU_Strng_Rt_Mns5 : 40|8@1+ (0.1,0) [0|25.4] ""  CBC
 SG_ VC_BU_Strng_Rt_Mns4 : 32|8@1+ (0.1,0) [0|25.4] ""  CBC
 SG_ VC_BU_Strng_Rt_Mns3 : 24|8@1+ (0.1,0) [0|25.4] ""  CBC
 SG_ VC_BU_Strng_Rt_Mns2 : 16|8@1+ (0.1,0) [0|25.4] ""  CBC
 SG_ VC_BU_Strng_Rt_Mns1 : 8|8@1+ (0.1,0) [0|25.4] ""  CBC
 SG_ VC_BU_BrkTyp : 4|3@1+ (1,0) [0|0] ""  CBC
 SG_ VC_BU_AQS_Prsnt : 7|1@1+ (1,0) [0|0] ""  CBC
 SG_ VC_BU_AnlgDrSnsr : 2|2@1+ (1,0) [0|0] ""  CBC
 SG_ VC_BU_WTS_Prsnt : 5|1@1+ (1,0) [0|0] ""  CBC
 SG_ VC_BU_VehCfg5_Stat : 0|2@1+ (1,0) [0|0] ""  CBC
 SG_ VC_BU_Strng_Rt_pls5 : 48|8@1+ (0.1,0) [0|25.4] ""  CBC
 SG_ VC_BU_Strng_Rt_pls4 : 40|8@1+ (0.1,0) [0|25.4] ""  CBC
 SG_ VC_BU_Strng_Rt_pls3 : 32|8@1+ (0.1,0) [0|25.4] ""  CBC
 SG_ VC_BU_Strng_Rt_pls2 : 24|8@1+ (0.1,0) [0|25.4] ""  CBC
 SG_ VC_BU_Strng_Rt_pls1 : 16|8@1+ (0.1,0) [0|25.4] ""  CBC
 SG_ VC_BU_Strng_Rt_0 : 8|8@1+ (0.1,0) [0|25.4] ""  CBC
 SG_ VC_BU_SpdLmt_PRSNT : 57|1@1+ (1,0) [0|0] ""  CBC
 SG_ VC_BU_SBR_Prsnt : 58|1@1+ (1,0) [0|0] ""  CBC
 SG_ VC_BU_RR_DuallyPrsnt : 3|1@1+ (1,0) [0|0] ""  CBC
 SG_ VC_BU_RearDoorLocks2DCM : 56|1@1+ (1,0) [0|0] ""  CBC
 SG_ VC_BU_PPPA_Prsnt : 62|1@1+ (1,0) [0|0] ""  CBC
 SG_ VC_BU_ParkStopPrsnt : 63|1@1+ (1,0) [0|0] ""  CBC
 SG_ VC_BU_OffRoadPg : 60|1@1+ (1,0) [0|0] ""  CBC
 SG_ VC_BU_NonReg_TPIS : 4|1@1+ (1,0) [0|0] ""  CBC
 SG_ VC_BU_LUCI_PRSNT : 2|1@1+ (1,0) [0|0] ""  CBC
 SG_ VC_BU_ChildDisp_Prsnt : 59|1@1+ (1,0) [0|0] ""  CBC
 SG_ VC_BU_AmbTempLct : 6|2@1+ (1,0) [0|0] ""  CBC
 SG_ VC_BU_AmbLtgPrsnt : 61|1@1+ (1,0) [0|0] ""  CBC
 SG_ D_RS_RF_HUB : 7|64@0+ (1,0) [0|0] ""  DIAGNOST,ETM
 SG_ D_RS_IC : 7|64@0+ (1,0) [0|0] ""  DIAGNOST,ETM
 SG_ D_RS_ORC : 7|64@0+ (1,0) [0|0] ""  DIAGNOST,ETM
 SG_ D_RS_ESM : 7|64@0+ (1,0) [0|0] ""  DIAGNOST,ETM
 SG_ D_RS_DASM : 7|64@0+ (1,0) [0|0] ""  DIAGNOST,ETM
 SG_ D_RS_EPS : 7|64@0+ (1,0) [0|0] ""  DIAGNOST,ETM
 SG_ D_RS_OCM : 7|64@0+ (1,0) [0|0] ""  DIAGNOST,ETM
 SG_ D_RS_PTS : 7|64@0+ (1,0) [0|0] ""  DIAGNOST,ETM
 SG_ D_RS_SCCM : 7|64@0+ (1,0) [0|0] ""  DIAGNOST,ETM
 SG_ D_RS_HaLF : 7|64@0+ (1,0) [0|0] ""  DIAGNOST,ETM
 SG_ D_RS_APM : 7|64@0+ (1,0) [0|0] ""  ETM,DIAGNOST
 SG_ D_RS_EAC : 7|64@0+ (1,0) [0|0] ""  ETM,DIAGNOST
 SG_ D_RS_AHCP : 7|64@0+ (1,0) [0|0] ""  ETM,DIAGNOST
 SG_ D_RS_OBCM : 7|64@0+ (1,0) [0|0] ""  ETM,DIAGNOST
 SG_ D_RS_CBC : 7|64@0+ (1,0) [0|0] ""  DIAGNOST,ETM
 SG_ ECU_APPL_RF_HUB : 7|64@0+ (1,0) [0|0] ""  DIAGNOST
 SG_ ECU_APPL_CBC : 7|64@0+ (1,0) [0|0] ""  DIAGNOST
 SG_ ECU_APPL_IC : 7|64@0+ (1,0) [0|0] ""  DIAGNOST
 SG_ ECU_APPL_ORC : 7|64@0+ (1,0) [0|0] ""  DIAGNOST
 SG_ ECU_APPL_ESM : 7|64@0+ (1,0) [0|0] ""  DIAGNOST
 SG_ ECU_APPL_DASM : 7|64@0+ (1,0) [0|0] ""  DIAGNOST
 SG_ ECU_APPL_EPS : 7|64@0+ (1,0) [0|0] ""  DIAGNOST
 SG_ ECU_APPL_OCM : 7|64@0+ (1,0) [0|0] ""  DIAGNOST
 SG_ ECU_APPL_PTS : 7|64@0+ (1,0) [0|0] ""  DIAGNOST
 SG_ ECU_APPL_SCCM : 7|64@0+ (1,0) [0|0] ""  DIAGNOST
 SG_ ECU_APPL_HaLF : 7|64@0+ (1,0) [0|0] ""  DIAGNOST
 SG_ ECU_APPL_ECM : 7|64@0+ (1,0) [0|0] ""  DIAGNOST
 SG_ ECU_APPL_HCP : 7|64@0+ (1,0) [0|0] ""  DIAGNOST
 SG_ ECU_APPL_EBCM : 7|64@0+ (1,0) [0|0] ""  DIAGNOST
 SG_ ECU_APPL_BSMO : 7|64@0+ (1,0) [0|0] ""  DIAGNOST
 SG_ SD_RS_RF_HUB : 7|64@0+ (1,0) [0|0] ""  ETM
 SG_ SD_RS_CBC : 7|64@0+ (1,0) [0|0] ""  ETM
 SG_ SD_RS_IC : 7|64@0+ (1,0) [0|0] ""  ETM
 SG_ SD_RS_ORC : 7|64@0+ (1,0) [0|0] ""  ETM
 SG_ SD_RS_ESM : 7|64@0+ (1,0) [0|0] ""  ETM
 SG_ SD_RS_DASM : 7|64@0+ (1,0) [0|0] ""  ETM
 SG_ SD_RS_EPS : 7|64@0+ (1,0) [0|0] ""  ETM
 SG_ SD_RS_OCM : 7|64@0+ (1,0) [0|0] ""  ETM
 SG_ D_RQ_CBC : 7|64@0+ (1,0) [0|0] ""  CBC
 SG_ SD_RS_PTS : 7|64@0+ (1,0) [0|0] ""  ETM
 SG_ SD_RS_SCCM : 7|64@0+ (1,0) [0|0] ""  ETM
 SG_ SD_RS_HaLF : 7|64@0+ (1,0) [0|0] ""  ETM
 SG_ SD_RS_ECM : 7|64@0+ (1,0) [0|0] ""  ETM,DIAGNOST
 SG_ SD_RS_HCP : 7|64@0+ (1,0) [0|0] ""  ETM
 SG_ SD_RS_BSMO : 7|64@0+ (1,0) [0|0] ""  ETM
 SG_ APPL_ECU_RF_HUB : 7|64@0+ (1,0) [0|0] ""  RF_HUB
 SG_ APPL_ECU_CBC : 7|64@0+ (1,0) [0|0] ""  CBC
 SG_ APPL_ECU_IC : 7|64@0+ (1,0) [0|0] ""  IC
 SG_ APPL_ECU_ORC : 7|64@0+ (1,0) [0|0] ""  ORC
 SG_ APPL_ECU_ESM : 7|64@0+ (1,0) [0|0] ""  ESM
 SG_ APPL_ECU_DASM : 7|64@0+ (1,0) [0|0] ""  DASM
 SG_ APPL_ECU_EPS : 7|64@0+ (1,0) [0|0] ""  EPS
 SG_ APPL_ECU_OCM : 7|64@0+ (1,0) [0|0] ""  OCM
 SG_ APPL_ECU_PTS : 7|64@0+ (1,0) [0|0] ""  PTS
 SG_ APPL_ECU_SCCM : 7|64@0+ (1,0) [0|0] ""  SCCM
 SG_ APPL_ECU_HaLF : 7|64@0+ (1,0) [0|0] ""  HALF
 SG_ APPL_ECU_ECM : 7|64@0+ (1,0) [0|0] ""  ECM
 SG_ APPL_ECU_HCP : 7|64@0+ (1,0) [0|0] ""  HCP
 SG_ APPL_ECU_EBCM : 7|64@0+ (1,0) [0|0] ""  EBCM
 SG_ APPL_ECU_BSMO : 7|64@0+ (1,0) [0|0] ""  ESC
 SG_ D_RQ_RF_HUB : 7|64@0+ (1,0) [0|0] ""  RF_HUB
 SG_ D_RQ_IC : 7|64@0+ (1,0) [0|0] ""  IC
 SG_ D_RQ_ORC : 7|64@0+ (1,0) [0|0] ""  ORC
 SG_ D_RQ_ESM : 7|64@0+ (1,0) [0|0] ""  ESM
 SG_ D_RQ_DASM : 7|64@0+ (1,0) [0|0] ""  DASM
 SG_ D_RQ_EPS : 7|64@0+ (1,0) [0|0] ""  EPS
 SG_ D_RQ_OCM : 7|64@0+ (1,0) [0|0] ""  OCM
 SG_ D_RQ_PTS : 7|64@0+ (1,0) [0|0] ""  PTS
 SG_ D_RQ_SCCM : 7|64@0+ (1,0) [0|0] ""  SCCM
 SG_ D_RQ_HaLF : 7|64@0+ (1,0) [0|0] ""  HALF
 SG_ D_RQ_APM : 7|64@0+ (1,0) [0|0] ""  HCP
 SG_ D_RQ_EAC : 7|64@0+ (1,0) [0|0] ""  HCP
 SG_ D_RQ_AHCP : 7|64@0+ (1,0) [0|0] ""  HCP
 SG_ D_RQ_OBCM : 7|64@0+ (1,0) [0|0] ""  HCP
 SG_ DG_RQ_GLOBAL : 7|64@0+ (1,0) [0|0] ""  HCP,ETM,ESC,ECM,EBCM
 SG_ D_RQ_ECM : 7|64@0+ (1,0) [0|0] ""  ECM
 SG_ D_RQ_HCP : 7|64@0+ (1,0) [0|0] ""  HCP
 SG_ D_RQ_EBCM : 7|64@0+ (1,0) [0|0] ""  EBCM
 SG_ D_RQ_BSMO : 7|64@0+ (1,0) [0|0] ""  ESC
 SG_ D_RQ_BPCM : 7|64@0+ (1,0) [0|0] ""  HCP
 SG_ D_RS_ECM : 7|64@0+ (1,0) [0|0] ""  DIAGNOST,ETM
 SG_ D_RS_HCP : 7|64@0+ (1,0) [0|0] ""  ETM,DIAGNOST
 SG_ D_RS_BSMO : 7|64@0+ (1,0) [0|0] ""  ETM,DIAGNOST
 SG_ D_RS_BPCM : 7|64@0+ (1,0) [0|0] ""  ETM,DIAGNOST
 SG_ NewSignal_0029 : 0|8@1+ (1,0) [0|0] "" Vector__XXX
 SG_ NewSignal_0030 : 0|8@1+ (1,0) [0|0] "" Vector__XXX
 SG_ NewSignal_0002 : 32|8@1+ (1,0) [0|0] "" Vector__XXX
 SG_ NewSignal_0004 : 48|8@1+ (1,0) [0|0] "" Vector__XXX
 SG_ NewSignal_0003 : 40|8@1+ (1,0) [0|0] "" Vector__XXX
 SG_ NewSignal_0005 : 0|8@1+ (1,0) [0|0] "" Vector__XXX
 SG_ NewEagle_BrakPosnSnsrVlt : 0|12@1+ (0.001221001221,0) [0|5] "V" Vector__XXX
 SG_ NAV_TEXT : 23|48@0+ (1,0) [0|0] ""  IC

BO_ 2027 D_RS_EBCM: 8 EBCM
 SG_ D_RS_EBCM : 7|64@0+ (1,0) [0|0] ""  DIAGNOST

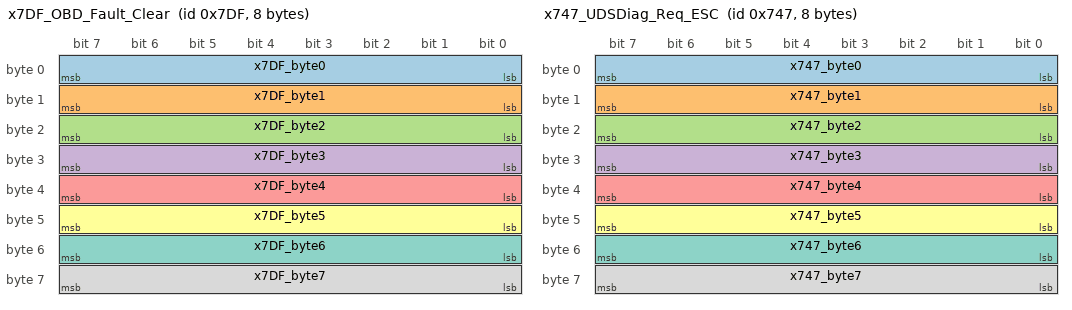
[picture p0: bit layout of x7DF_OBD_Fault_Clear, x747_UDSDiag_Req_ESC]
BO_ 2015 x7DF_OBD_Fault_Clear: 8 DIAGNOST
 SG_ x7DF_byte0 : 0|8@1+ (1,0) [0|255] "" Vector__XXX
 SG_ x7DF_byte1 : 8|8@1+ (1,0) [0|255] "" Vector__XXX
 SG_ x7DF_byte2 : 16|8@1+ (1,0) [0|255] "" Vector__XXX
 SG_ x7DF_byte3 : 24|8@1+ (1,0) [0|255] "" Vector__XXX
 SG_ x7DF_byte4 : 32|8@1+ (1,0) [0|255] "" Vector__XXX
 SG_ x7DF_byte5 : 40|8@1+ (1,0) [0|255] "" Vector__XXX
 SG_ x7DF_byte6 : 48|8@1+ (1,0) [0|255] "" Vector__XXX
 SG_ x7DF_byte7 : 56|8@1+ (1,0) [0|255] "" Vector__XXX

BO_ 1863 x747_UDSDiag_Req_ESC: 8 ETM
 SG_ x747_byte0 : 0|8@1+ (1,0) [0|255] "" Vector__XXX
 SG_ x747_byte1 : 8|8@1+ (1,0) [0|255] "" Vector__XXX
 SG_ x747_byte2 : 16|8@1+ (1,0) [0|255] "" Vector__XXX
 SG_ x747_byte3 : 24|8@1+ (1,0) [0|255] "" Vector__XXX
 SG_ x747_byte4 : 32|8@1+ (1,0) [0|255] "" Vector__XXX
 SG_ x747_byte5 : 40|8@1+ (1,0) [0|255] "" Vector__XXX
 SG_ x747_byte6 : 48|8@1+ (1,0) [0|255] "" Vector__XXX
 SG_ x747_byte7 : 56|8@1+ (1,0) [0|255] "" Vector__XXX

BO_ 1572 SD_RS_HaLF: 8 HALF
 SG_ SD_RS_HaLF : 7|64@0+ (1,0) [0|0] ""  ETM

BO_ 1570 SD_RS_PTS: 8 PTS
 SG_ SD_RS_PTS : 7|64@0+ (1,0) [0|0] ""  ETM

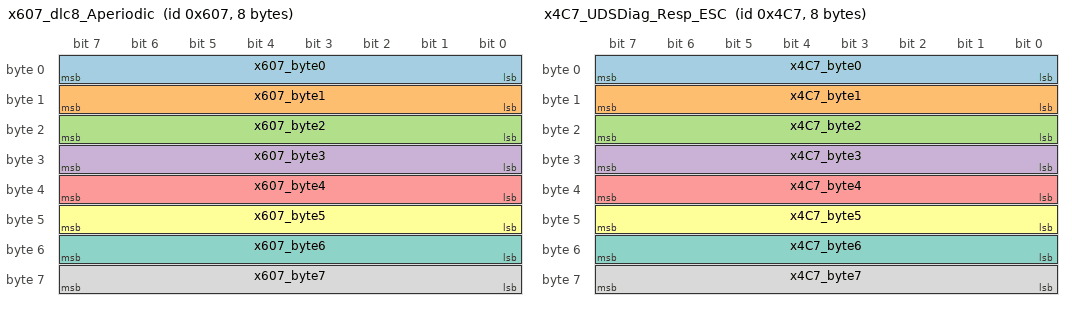
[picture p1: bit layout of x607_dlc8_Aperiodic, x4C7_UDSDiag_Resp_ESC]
BO_ 1543 x607_dlc8_Aperiodic: 8 Vector__XXX
 SG_ x607_byte0 : 0|8@1+ (1,0) [0|255] "" Vector__XXX
 SG_ x607_byte1 : 8|8@1+ (1,0) [0|255] "" Vector__XXX
 SG_ x607_byte2 : 16|8@1+ (1,0) [0|255] "" Vector__XXX
 SG_ x607_byte3 : 24|8@1+ (1,0) [0|255] "" Vector__XXX
 SG_ x607_byte4 : 32|8@1+ (1,0) [0|255] "" Vector__XXX
 SG_ x607_byte5 : 40|8@1+ (1,0) [0|255] "" Vector__XXX
 SG_ x607_byte6 : 48|8@1+ (1,0) [0|255] "" Vector__XXX
 SG_ x607_byte7 : 56|8@1+ (1,0) [0|255] "" Vector__XXX

BO_ 1223 x4C7_UDSDiag_Resp_ESC: 8 ESC
 SG_ x4C7_byte0 : 0|8@1+ (1,0) [0|255] "" Vector__XXX
 SG_ x4C7_byte1 : 8|8@1+ (1,0) [0|255] "" Vector__XXX
 SG_ x4C7_byte2 : 16|8@1+ (1,0) [0|255] "" Vector__XXX
 SG_ x4C7_byte3 : 24|8@1+ (1,0) [0|255] "" Vector__XXX
 SG_ x4C7_byte4 : 32|8@1+ (1,0) [0|255] "" Vector__XXX
 SG_ x4C7_byte5 : 40|8@1+ (1,0) [0|255] "" Vector__XXX
 SG_ x4C7_byte6 : 48|8@1+ (1,0) [0|255] "" Vector__XXX
 SG_ x4C7_byte7 : 56|8@1+ (1,0) [0|255] "" Vector__XXX

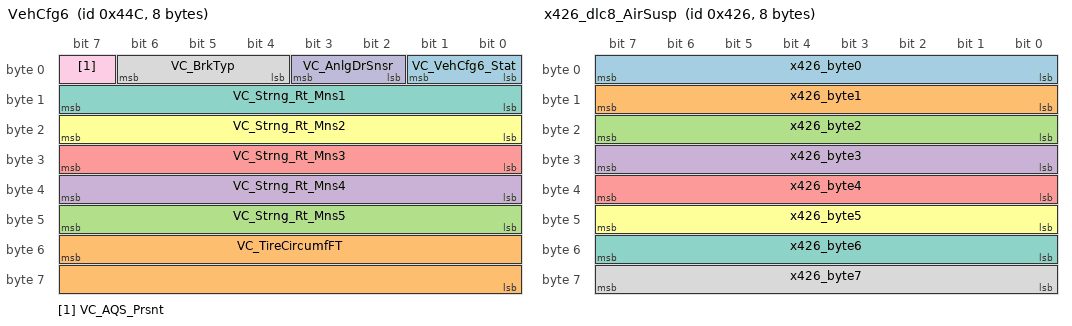
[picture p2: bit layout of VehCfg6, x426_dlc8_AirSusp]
BO_ 1100 VehCfg6: 8 CBC
 SG_ VC_VehCfg6_Stat : 0|2@1+ (1,0) [0|0] ""  RF_HUB,ORC,IC,HCP,ESC,ECM
 SG_ VC_TireCircumfFT : 55|16@0+ (1,0) [0|65534] "mm"  RF_HUB,ESC
 SG_ VC_Strng_Rt_Mns5 : 40|8@1+ (0.1,0) [0|25.4] ""  ESC,RF_HUB
 SG_ VC_Strng_Rt_Mns4 : 32|8@1+ (0.1,0) [0|25.4] ""  ESC,RF_HUB
 SG_ VC_Strng_Rt_Mns3 : 24|8@1+ (0.1,0) [0|25.4] ""  ESC,RF_HUB
 SG_ VC_Strng_Rt_Mns2 : 16|8@1+ (0.1,0) [0|25.4] ""  ESC,RF_HUB
 SG_ VC_Strng_Rt_Mns1 : 8|8@1+ (0.1,0) [0|25.4] ""  ESC,RF_HUB
 SG_ VC_BrkTyp : 4|3@1+ (1,0) [0|0] ""  RF_HUB
 SG_ VC_AQS_Prsnt : 7|1@1+ (1,0) [0|0] ""  RF_HUB
 SG_ VC_AnlgDrSnsr : 2|2@1+ (1,0) [0|0] ""  RF_HUB

BO_ 1098 VehCfg5: 8 CBC
 SG_ VC_WTS_Prsnt : 5|1@1+ (1,0) [0|0] ""  RF_HUB
 SG_ VC_VehCfg5_Stat : 0|2@1+ (1,0) [0|0] ""  SCCM,RF_HUB,PTS,ORC,IC,ESC,ECM,DASM
 SG_ VC_Strng_Rt_pls5 : 48|8@1+ (0.1,0) [0|25.4] ""  ESC,RF_HUB
 SG_ VC_Strng_Rt_pls4 : 40|8@1+ (0.1,0) [0|25.4] ""  ESC,RF_HUB
 SG_ VC_Strng_Rt_pls3 : 32|8@1+ (0.1,0) [0|25.4] ""  ESC,RF_HUB
 SG_ VC_Strng_Rt_pls2 : 24|8@1+ (0.1,0) [0|25.4] ""  ESC,RF_HUB
 SG_ VC_Strng_Rt_pls1 : 16|8@1+ (0.1,0) [0|25.4] ""  ESC,RF_HUB
 SG_ VC_Strng_Rt_0 : 8|8@1+ (0.1,0) [0|25.4] ""  ESC,RF_HUB
 SG_ VC_SpdLmt_PRSNT : 57|1@1+ (1,0) [0|0] ""  SCCM,RF_HUB,DASM
 SG_ VC_SBR_Prsnt : 58|1@1+ (1,0) [0|0] ""  RF_HUB
 SG_ VC_RR_DuallyPrsnt : 3|1@1+ (1,0) [0|0] ""  RF_HUB
 SG_ VC_RearDoorLocks2DCM : 56|1@1+ (1,0) [0|0] ""  RF_HUB
 SG_ VC_PPPA_Prsnt : 62|1@1+ (1,0) [0|0] ""  RF_HUB,PTS,IC,ESC,EPS
 SG_ VC_ParkStopPrsnt : 63|1@1+ (1,0) [0|0] ""  RF_HUB,IC,ESC
 SG_ VC_OffRoadPg : 60|1@1+ (1,0) [0|0] ""  RF_HUB
 SG_ VC_NonReg_TPIS : 4|1@1+ (1,0) [0|0] ""  RF_HUB
 SG_ VC_LUCI_PRSNT : 2|1@1+ (1,0) [0|0] ""  RF_HUB
 SG_ VC_ChildDisp_Prsnt : 59|1@1+ (1,0) [0|0] ""  RF_HUB
 SG_ VC_AmbTempLct : 6|2@1+ (1,0) [0|0] ""  RF_HUB
 SG_ VC_AmbLtgPrsnt : 61|1@1+ (1,0) [0|0] ""  RF_HUB

BO_ 1062 x426_dlc8_AirSusp: 8 AirSusp
 SG_ x426_byte0 : 0|8@1+ (1,0) [0|255] "" Vector__XXX
 SG_ x426_byte1 : 8|8@1+ (1,0) [0|255] "" Vector__XXX
 SG_ x426_byte2 : 16|8@1+ (1,0) [0|255] "" Vector__XXX
 SG_ x426_byte3 : 24|8@1+ (1,0) [0|255] "" Vector__XXX
 SG_ x426_byte4 : 32|8@1+ (1,0) [0|255] "" Vector__XXX
 SG_ x426_byte5 : 40|8@1+ (1,0) [0|255] "" Vector__XXX
 SG_ x426_byte6 : 48|8@1+ (1,0) [0|255] "" Vector__XXX
 SG_ x426_byte7 : 56|8@1+ (1,0) [0|255] "" Vector__XXX

BO_ 1059 NM_SCCM: 8 SCCM
 SG_ WakeupRsn_SCCM m2 : 32|8@1+ (1,0) [0|0] ""  EBCM,HCP,ESM,ESC,SCCM,EPS,IC,CBC,RF_HUB
 SG_ WakeupCnt_SCCM m2 : 40|8@1+ (1,0) [0|254] ""  EBCM,HCP,ESM,ESC,SCCM,EPS,IC,CBC,RF_HUB
 SG_ Nw_Id_SCCM : 56|8@1+ (1,0) [0|0] ""  EBCM,HCP,ESM,ESC,SCCM,EPS,IC,CBC,RF_HUB
 SG_ NM_Ud_Srv_SCCM M : 24|8@1+ (1,0) [0|0] ""  EBCM,HCP,ESM,ESC,SCCM,EPS,IC,CBC,RF_HUB
 SG_ NM_Ud_Launch_SCCM : 16|6@1+ (1,0) [0|0] ""  EBCM,HCP,ESM,ESC,SCCM,EPS,IC,CBC,RF_HUB
 SG_ NM_Successor_SCCM : 8|8@1+ (1,0) [0|63] ""  EBCM,HCP,ESM,ESC,SCCM,EPS,IC,CBC,RF_HUB
 SG_ NM_Sleep_Ind_SCCM : 23|1@1+ (1,0) [0|0] ""  EBCM,HCP,ESM,ESC,SCCM,EPS,IC,CBC,RF_HUB
 SG_ NM_Sleep_Ack_SCCM : 22|1@1+ (1,0) [0|0] ""  EBCM,HCP,ESM,ESC,SCCM,EPS,IC,CBC,RF_HUB
 SG_ NM_Mode_SCCM : 0|8@1+ (1,0) [0|0] ""  EBCM,HCP,ESM,ESC,SCCM,EPS,IC,CBC,RF_HUB
 SG_ Awake_tilt_tel_Psd_SCCM m15 : 37|1@1+ (1,0) [0|0] ""  EBCM,HCP,ESM,ESC,SCCM,EPS,IC,CBC,RF_HUB
 SG_ Awake_StwSw_Actv_SCCM m15 : 34|1@1+ (1,0) [0|0] ""  EBCM,HCP,ESM,ESC,SCCM,EPS,IC,CBC,RF_HUB
 SG_ Awake_NwSt_SCCM m15 : 32|1@1+ (1,0) [0|0] ""  EBCM,HCP,ESM,ESC,SCCM,EPS,IC,CBC,RF_HUB
 SG_ Awake_Ignition_On_SCCM m15 : 35|1@1+ (1,0) [0|0] ""  EBCM,HCP,ESM,ESC,SCCM,EPS,IC,CBC,RF_HUB
 SG_ Awake_HrnSwt_Actv_SCCM m15 : 39|1@1+ (1,0) [0|0] ""  EBCM,HCP,ESM,ESC,SCCM,EPS,IC,CBC,RF_HUB
 SG_ Awake_FTP_Psd_SCCM m15 : 38|1@1+ (1,0) [0|0] ""  EBCM,HCP,ESM,ESC,SCCM,EPS,IC,CBC,RF_HUB
 SG_ Awake_EEPROM_SCCM m15 : 36|1@1+ (1,0) [0|0] ""  EBCM,HCP,ESM,ESC,SCCM,EPS,IC,CBC,RF_HUB
 SG_ Awake_Diag_Actv_SCCM m15 : 33|1@1+ (1,0) [0|0] ""  EBCM,HCP,ESM,ESC,SCCM,EPS,IC,CBC,RF_HUB

BO_ 1050 NM_EPS: 8 EPS
 SG_ WakeupRsn_EPS m2 : 32|8@1+ (1,0) [0|0] ""  EBCM,HCP,ESM,ESC,SCCM,EPS,IC,CBC,RF_HUB
 SG_ WakeupCnt_EPS m2 : 40|8@1+ (1,0) [0|254] ""  EBCM,HCP,ESM,ESC,SCCM,EPS,IC,CBC,RF_HUB
 SG_ Nw_Id_EPS : 56|8@1+ (1,0) [0|0] ""  EBCM,HCP,ESM,ESC,SCCM,EPS,IC,CBC,RF_HUB
 SG_ NM_Ud_Srv_EPS M : 24|8@1+ (1,0) [0|0] ""  EBCM,HCP,ESM,ESC,SCCM,EPS,IC,CBC,RF_HUB
 SG_ NM_Ud_Launch_EPS : 16|6@1+ (1,0) [0|0] ""  EBCM,HCP,ESM,ESC,SCCM,EPS,IC,CBC,RF_HUB
 SG_ NM_Successor_EPS : 8|8@1+ (1,0) [0|63] ""  EBCM,HCP,ESM,ESC,SCCM,EPS,IC,CBC,RF_HUB
 SG_ NM_Sleep_Ind_EPS : 23|1@1+ (1,0) [0|0] ""  EBCM,HCP,ESM,ESC,SCCM,EPS,IC,CBC,RF_HUB
 SG_ NM_Sleep_Ack_EPS : 22|1@1+ (1,0) [0|0] ""  EBCM,HCP,ESM,ESC,SCCM,EPS,IC,CBC,RF_HUB
 SG_ NM_Mode_EPS : 0|8@1+ (1,0) [0|0] ""  EBCM,HCP,ESM,ESC,SCCM,EPS,IC,CBC,RF_HUB
 SG_ Awake_VSS_high_EPS m15 : 35|1@1+ (1,0) [0|0] ""  EBCM,HCP,ESM,ESC,SCCM,EPS,IC,CBC,RF_HUB
 SG_ Awake_Rampout_EPS m15 : 34|1@1+ (1,0) [0|0] ""  EBCM,HCP,ESM,ESC,SCCM,EPS,IC,CBC,RF_HUB
 SG_ Awake_NwSt_EPS m15 : 32|1@1+ (1,0) [0|0] ""  EBCM,HCP,ESM,ESC,SCCM,EPS,IC,CBC,RF_HUB
 SG_ Awake_IgnHigh_EPS m15 : 37|1@1+ (1,0) [0|0] ""  EBCM,HCP,ESM,ESC,SCCM,EPS,IC,CBC,RF_HUB
 SG_ Awake_EngRPM_high_EPS m15 : 36|1@1+ (1,0) [0|0] ""  EBCM,HCP,ESM,ESC,SCCM,EPS,IC,CBC,RF_HUB
 SG_ Awake_Diag_Actv_EPS m15 : 33|1@1+ (1,0) [0|0] ""  EBCM,HCP,ESM,ESC,SCCM,EPS,IC,CBC,RF_HUB

BO_ 1033 NM_SBWM: 8 ESM
 SG_ WakeupRsn_SBWM m2 : 32|8@1+ (1,0) [0|0] ""  EBCM,HCP,ESM,ESC,SCCM,EPS,IC,CBC,RF_HUB
 SG_ WakeupCnt_SBWM m2 : 40|8@1+ (1,0) [0|254] ""  EBCM,HCP,ESM,ESC,SCCM,EPS,IC,CBC,RF_HUB
 SG_ Nw_Id_SBWM : 56|8@1+ (1,0) [0|0] ""  EBCM,HCP,ESM,ESC,SCCM,EPS,IC,CBC,RF_HUB
 SG_ NM_Ud_Srv_SBWM M : 24|8@1+ (1,0) [0|0] ""  EBCM,HCP,ESM,ESC,SCCM,EPS,IC,CBC,RF_HUB
 SG_ NM_Ud_Launch_SBWM : 16|6@1+ (1,0) [0|0] ""  EBCM,HCP,ESM,ESC,SCCM,EPS,IC,CBC,RF_HUB
 SG_ NM_Successor_SBWM : 8|8@1+ (1,0) [0|63] ""  EBCM,HCP,ESM,ESC,SCCM,EPS,IC,CBC,RF_HUB
 SG_ NM_Sleep_Ind_SBWM : 23|1@1+ (1,0) [0|0] ""  EBCM,HCP,ESM,ESC,SCCM,EPS,IC,CBC,RF_HUB
 SG_ NM_Sleep_Ack_SBWM : 22|1@1+ (1,0) [0|0] ""  EBCM,HCP,ESM,ESC,SCCM,EPS,IC,CBC,RF_HUB
 SG_ NM_Mode_SBWM : 0|8@1+ (1,0) [0|0] ""  EBCM,HCP,ESM,ESC,SCCM,EPS,IC,CBC,RF_HUB
 SG_ Awake_URS_SBWM m15 : 36|1@1+ (1,0) [0|0] ""  EBCM,HCP,ESM,ESC,SCCM,EPS,IC,CBC,RF_HUB
 SG_ Awake_NwSt_SBWM m15 : 32|1@1+ (1,0) [0|0] ""  EBCM,HCP,ESM,ESC,SCCM,EPS,IC,CBC,RF_HUB
 SG_ Awake_Ignition_On_SBWM m15 : 34|1@1+ (1,0) [0|0] ""  EBCM,HCP,ESM,ESC,SCCM,EPS,IC,CBC,RF_HUB
 SG_ Awake_EEPROM_SBWM m15 : 35|1@1+ (1,0) [0|0] ""  EBCM,HCP,ESM,ESC,SCCM,EPS,IC,CBC,RF_HUB
 SG_ Awake_Diag_Actv_SBWM m15 : 33|1@1+ (1,0) [0|0] ""  EBCM,HCP,ESM,ESC,SCCM,EPS,IC,CBC,RF_HUB

BO_ 1031 NM_ESC: 8 ESC
 SG_ WakeupRsn_ESC m2 : 32|8@1+ (1,0) [0|0] ""  EBCM,HCP,ESM,ESC,SCCM,EPS,IC,CBC,RF_HUB
 SG_ WakeupCnt_ESC m2 : 40|8@1+ (1,0) [0|254] ""  EBCM,HCP,ESM,ESC,SCCM,EPS,IC,CBC,RF_HUB
 SG_ Nw_Id_ESC : 56|8@1+ (1,0) [0|0] ""  EBCM,HCP,ESM,ESC,SCCM,EPS,IC,CBC,RF_HUB
 SG_ NM_Ud_Srv_ESC M : 24|8@1+ (1,0) [0|0] ""  EBCM,HCP,ESM,ESC,SCCM,EPS,IC,CBC,RF_HUB
 SG_ NM_Ud_Launch_ESC : 16|6@1+ (1,0) [0|0] ""  EBCM,HCP,ESM,ESC,SCCM,EPS,IC,CBC,RF_HUB
 SG_ NM_Successor_ESC : 8|8@1+ (1,0) [0|63] ""  EBCM,HCP,ESM,ESC,SCCM,EPS,IC,CBC,RF_HUB
 SG_ NM_Sleep_Ind_ESC : 23|1@1+ (1,0) [0|0] ""  EBCM,HCP,ESM,ESC,SCCM,EPS,IC,CBC,RF_HUB
 SG_ NM_Sleep_Ack_ESC : 22|1@1+ (1,0) [0|0] ""  EBCM,HCP,ESM,ESC,SCCM,EPS,IC,CBC,RF_HUB
 SG_ NM_Mode_ESC : 0|8@1+ (1,0) [0|0] ""  EBCM,HCP,ESM,ESC,SCCM,EPS,IC,CBC,RF_HUB
 SG_ Awake_Vehicle_Speed_ESC m15 : 35|1@1+ (1,0) [0|0] ""  EBCM,HCP,ESM,ESC,SCCM,EPS,IC,CBC,RF_HUB
 SG_ Awake_NwSt_ESC m15 : 32|1@1+ (1,0) [0|0] ""  EBCM,HCP,ESM,ESC,SCCM,EPS,IC,CBC,RF_HUB
 SG_ Awake_Hardwire_Ignition_ESC m15 : 37|1@1+ (1,0) [0|0] ""  EBCM,HCP,ESM,ESC,SCCM,EPS,IC,CBC,RF_HUB
 SG_ Awake_EPB_Switch_Wakeup_ESC m15 : 36|1@1+ (1,0) [0|0] ""  EBCM,HCP,ESM,ESC,SCCM,EPS,IC,CBC,RF_HUB
 SG_ Awake_Diag_Actv_ESC m15 : 33|1@1+ (1,0) [0|0] ""  EBCM,HCP,ESM,ESC,SCCM,EPS,IC,CBC,RF_HUB
 SG_ Awake_Brake_Pedal_Pressed_ESC m15 : 34|1@1+ (1,0) [0|0] ""  EBCM,HCP,ESM,ESC,SCCM,EPS,IC,CBC,RF_HUB

CM_ "XDIS NWC Export: PN_CAN_C_1417 [18],UUID 78ED69F7B5C011E3A77F80C16EEF1BB8, IN PROCESS 2014-05-07 EDT-08:05:25";
CM_ BU_ AirSusp "Air Suspension Control Module";
CM_ BU_ TCM "Transmission Control Module";
CM_ BU_ DTCM "Drivetrain Control Module";
CM_ BU_ ELSDM "Electronic Limited Slip Differential Module";
CM_ SG_ 3221225472 CRC_10Eh "CRC-checksum byte 1 to 7 according to SAE J1850";
CM_ SG_ 3221225472 MC_10Eh "Message counter";
CM_ SG_ 3221225472 WhlTrq_Rq_As "Wheel torque request";
CM_ SG_ 3221225472 WhlTrq_Rq_ESC "Wheel torque request";
CM_ SG_ 3221225472 WhlTrqAct_Rq_AS "Wheel torque request active; True = [1]";
CM_ SG_ 3221225472 WhlTrqMax_Rq_ESC "Wheel torque request maximum";
CM_ SG_ 3221225472 WhlTrqMin_Rq_ESC "Wheel torque request minimum";
CM_ SG_ 3221225472 CRC_123h "CRC-checksum byte 1 to 7 according to SAE J1850";
CM_ SG_ 3221225472 M_MAX_AXLE "Maximum axle torque";
CM_ SG_ 3221225472 M_MIN_AXLE "Minimum axle torque";
CM_ SG_ 3221225472 M_STA_AXLE "Static axle torque";
CM_ SG_ 3221225472 MC_123h "Message counter";
CM_ SG_ 3221225472 AXSStat "Longitudinal signal status";
CM_ SG_ 3221225472 AYSStat "Latitudinal signal status";
CM_ SG_ 3221225472 CRC_ORC_YRS_DATA "CRC-checksum byte 1 to 7 according to SAE J1850";
CM_ SG_ 3221225472 InternalError "ORC ESC internal error; True = [1]";
CM_ SG_ 3221225472 LatAcceleration "Raw lateral acceleration";
CM_ SG_ 3221225472 LongAcceleration "Raw longitudinal acceleration";
CM_ SG_ 3221225472 MC_ORC_YRS_DATA "Message counter";
CM_ SG_ 3221225472 VoltageError "ORC ESC voltage error; True = [1]";
CM_ SG_ 3221225472 YawRate "Raw yaw acceleration";
CM_ SG_ 3221225472 YRSStat "Yaw rate signal status";
CM_ SG_ 3221225472 IMPACT_B "EARS Rear Event; actuate = [1]; do_not_actuate = [0]";
CM_ SG_ 3221225472 IMPACT_C "EARS higher severity front event; actuate = [1]; do_not_actuate = [0]";
CM_ SG_ 3221225472 Impact_F "EARS lower severity front event; actuate = [1]; do_not_actuate = [0]";
CM_ SG_ 3221225472 IMPACT_I "EARS Rollover Event; actuate = [1]; do_not_actuate = [0]";
CM_ SG_ 3221225472 IMPACT_L "EARS Side Event; actuate = [1]; do_not_actuate = [0]";
CM_ SG_ 3221225472 Impact_Tgl "Toggle bit for all impact events; See Signal Description Document";
CM_ SG_ 3221225472 IMPACT_X "Any impact event; actuate = [1]; do_not_actuate = [0]";
CM_ SG_ 3221225472 ORC_Health "ORC alive and active; True = [1]";
CM_ SG_ 3221225472 AirTemp_Outsd "Outside air temperature";
CM_ SG_ 3221225472 AMB_TEMP_AVG "Averaged ambient temperature";
CM_ SG_ 3221225472 AMB_TEMP_VOLT "Ambient Temp Sensor A/D Voltage";
CM_ SG_ 3221225472 BATT_VOLT "System voltage";
CM_ SG_ 3221225472 FUEL_VOLT "Fuel level A/D Voltage (Single tank OR Primary on Saddle/Dual Tank)";
CM_ SG_ 3221225472 FUEL_VOLT2 "Sub Side Fuel level sensor A/D Voltage (saddle/Dual tank)";
CM_ SG_ 3221225472 rnd_04 "Random number 4";
CM_ SG_ 3221225472 rnd_03 "Random number 3";
CM_ SG_ 3221225472 rnd_02 "Random number 2";
CM_ SG_ 3221225472 rnd_01 "Random number 1";
CM_ SG_ 3221225472 f1_02 "F code 1_2";
CM_ SG_ 3221225472 f1_01 "F code 1_1";
CM_ SG_ 3221225472 ControlEncodingRq_HCP "Control encoding - request";
CM_ SG_ 3221225472 MKKey2org22 "Mini kript key 2 or G2_2";
CM_ SG_ 3221225472 MKKey1org21 "Mini kript key 1 or G2_1";
CM_ SG_ 3221225472 MKKey_6 "Mini kript key 6";
CM_ SG_ 3221225472 MKKey_5 "Mini kript key 5";
CM_ SG_ 3221225472 MKKey_4 "Mini kript key 4";
CM_ SG_ 3221225472 MKKey_3 "Mini kript key 3";
CM_ SG_ 3221225472 ControlEncodingRsp "Control encoding - response";
CM_ SG_ 3221225472 rnd_4 "Random number 4";
CM_ SG_ 3221225472 rnd_3 "Random number 3";
CM_ SG_ 3221225472 rnd_2 "Random number 2";
CM_ SG_ 3221225472 rnd_1 "Random number 1";
CM_ SG_ 3221225472 f1_2 "F code 1_2";
CM_ SG_ 3221225472 f1_1 "F code 1_1";
CM_ SG_ 3221225472 ControlEncodingRq "Control encoding - request";
CM_ SG_ 3221225472 MKKey02org22 "Mini kript key 2 or G2_2";
CM_ SG_ 3221225472 MKKey01org21 "Mini kript key 1 or G2_1";
CM_ SG_ 3221225472 MKKey_06 "Mini kript key 6";
CM_ SG_ 3221225472 MKKey_05 "Mini kript key 5";
CM_ SG_ 3221225472 MKKey_04 "Mini kript key 4";
CM_ SG_ 3221225472 MKKey_03 "Mini kript key 3";
CM_ SG_ 3221225472 ControlEncoding_Rsp_HCP "Control encoding - response";
CM_ SG_ 3221225472 ControlEncodingBCM "Fob authentication or presence query";
CM_ SG_ 3221225472 MiniCrypt_Rnd "MiniCrypt input random number";
CM_ SG_ 3221225472 MiniCryptFCode "MiniCrypt 'F' code output";
CM_ SG_ 3221225472 TxpAuthRequest "Transponder authentication request; Request = [0]";
CM_ SG_ 3221225472 TxpReadRequest "Transponder reading request; Request = [0]";
CM_ SG_ 3221225472 MinicryptReceptionSts "Acknowledge message reception; Received = [1]";
CM_ SG_ 3221225472 CodeCheckSts "Code check status";
CM_ SG_ 3221225472 ControlEncoding "Response type UC/TEN/PVA";
CM_ SG_ 3221225472 MiniCryptGCode "MiniCrypt 'G' code output";
CM_ SG_ 3221225472 ProgrammedSts "TRM programmed status; Programmed = [1]";
CM_ SG_ 3221225472 TxpFound "Transponder found; Absent = [1]";
CM_ SG_ 3221225472 TxpID "Transponder authentication";
CM_ SG_ 3221225472 DATA1 "MiniCrypt key data byte 1";
CM_ SG_ 3221225472 DATA2 "MiniCrypt key data byte 2";
CM_ SG_ 3221225472 DATA3 "MiniCrypt key data byte 3";
CM_ SG_ 3221225472 DATA4 "MiniCrypt key data byte 4";
CM_ SG_ 3221225472 DATA5 "MiniCrypt key data byte 5";
CM_ SG_ 3221225472 DATA6 "MiniCrypt key data byte 6";
CM_ SG_ 3221225472 DATA7 "MiniCrypt key data byte 7";
CM_ SG_ 3221225472 FrameNumber "MiniCrypt key frame number";
CM_ SG_ 3221225472 TotalFrameNumber "MiniCrypt key total number of frames";
CM_ SG_ 3221225472 CRC_OCM_A1 "CRC-checksum byte 1 to 7 according to SAE J1850";
CM_ SG_ 3221225472 MC_OCM_A1 "Message counter";
CM_ SG_ 3221225472 PsgSeatOCFaultSts "Passenger occupant classification fault; True = [1]";
CM_ SG_ 3221225472 PsgSeatOCSts "Occupant classification passenger";
CM_ SG_ 3221225472 PsgSeatSBRSts "Passenger seatbelt reminder status";
CM_ SG_ 3221225472 CRC_PRESF_CTRL_ESP "CRC-checksum byte 1 to 7 according to SAE J1850";
CM_ SG_ 3221225472 MC_PRESF_CTRL_ESP "Message counter";
CM_ SG_ 3221225472 BlockOffset "Part number block offset";
CM_ SG_ 3221225472 Character0 "Part number character 0";
CM_ SG_ 3221225472 Character1 "Part number character 1";
CM_ SG_ 3221225472 Character2 "Part number character 2";
CM_ SG_ 3221225472 Character3 "Part number character 3";
CM_ SG_ 3221225472 Character4 "Part number character 4";
CM_ SG_ 3221225472 Character5 "Part number character 5";
CM_ SG_ 3221225472 CLUType "Part number CLU type";
CM_ SG_ 3221225472 PTRInfo "Part number PTR information";
CM_ SG_ 3221225472 HCPCoachDisp "Percentage output acceleration & deceleration to support Efficiency Coaching HMI";
CM_ SG_ 3221225472 HCPCoachDispV "Acceleration & deceleration to support Efficiency Coaching validtiy, 0 = Valid, 1 = Invalid";
CM_ SG_ 3221225472 HCPOutputPwr "Percentage output power from HCP for HMI";
CM_ SG_ 3221225472 HCPOutputPwrV "Percentage output power from HCP for HMI validity, 0 = Valid, 1 = Invalid";
CM_ SG_ 3221225472 HCPPopUpMessage1 "Vehicle speed may be limited; True = [1]";
CM_ SG_ 3221225472 HCPPopUpMessage2 "Plug in vehicle to keep battery warm; True = [1]";
CM_ SG_ 3221225472 HCPPopUpMessage3 "Remote start canceled - hv battery temperature; True = [1]";
CM_ SG_ 3221225472 HCPPopUpMessage4 "Turn on vehicle to use climate controls; True = [1]";
CM_ SG_ 3221225472 HCPPopUpMessage5 "Please check plug status before driving; True = [1]";
CM_ SG_ 3221225472 HCPPopUpMessage6 "There may be a problem with the charging unit; True = [1]";
CM_ SG_ 3221225472 HCPPopUpMessage7 "Please leave key in run - battery conditioning needed; True = [1]";
CM_ SG_ 3221225472 HybSysEmsMlfAtv "Emissions Related Malfunction Active";
CM_ SG_ 3221225472 MIL_OnRq_HCP "MIL on request from the HCP";
CM_ SG_ 3221225472 CabinPreCondReqStat "Cabin Preconditioning Request Status";
CM_ SG_ 3221225472 ChargingLevel "Charging level and type.";
CM_ SG_ 3221225472 ChargingSysSts "Charging System status";
CM_ SG_ 3221225472 ChrgSysFault "Charging System Fault status";
CM_ SG_ 3221225472 CompStat "comppressor state";
CM_ SG_ 3221225472 DriveReady "Ready to Drive, [1] = Vehicle is allowed to shift out of park or neutral";
CM_ SG_ 3221225472 EstTimeofChrg_Lv1 "Estimated Time to charge on Level 1";
CM_ SG_ 3221225472 EstTimeofChrg_Lv2 "Estimated Time to charge on Level 2";
CM_ SG_ 3221225472 HtrCoreInletTemp "Heater Core Inlet Temp";
CM_ SG_ 3221225472 PrplsnSysAtv "Propulsion system active, [1] = active";
CM_ SG_ 3221225472 CRC_EPB_A1 "CRC-checksum byte 1 to 2 according to SAE J1850";
CM_ SG_ 3221225472 EPBHoldSts "EPB hold status";
CM_ SG_ 3221225472 MC_EPB_A1 "Message counter";
CM_ SG_ 3221225472 UConnReq "Basic Uconnect request";
CM_ SG_ 3221225472 UConnReqAuthCode "Authorization for requests";
CM_ SG_ 3221225472 UConnReqFOBNum "FOB number making the request";
CM_ SG_ 3221225472 BatPwrUsage ".";
CM_ SG_ 3221225472 BatPwrUsage_V ".";
CM_ SG_ 3221225472 Est_Range "Estimated electric range sent to HMI";
CM_ SG_ 3221225472 HEV_EVT_MD "The system is in EVT mode; Hybrid mode = [0], EV Mode = [1]";
CM_ SG_ 3221225472 HEV_LMP_RQ "HEV service lamp request";
CM_ SG_ 3221225472 R134a_PressSts "Refrigerant pressure (R134a or R1234YF)";
CM_ SG_ 3221225472 ElecClntHtrInletTemp "Electric Coolant Heater Inlet Temperature";
CM_ SG_ 3221225472 ElecCoolantHtrPwr "Electric Coolant Heater Power";
CM_ SG_ 3221225472 FRfShVlvSts "Front Refrigerant Shutoff Valve Status";
CM_ SG_ 3221225472 HTAuxPmpMontrngRPM "High Temp Aux Pump RPM monitoring active";
CM_ SG_ 3221225472 HTAuxPmpRPMAct "High Temp Aux Pump Status";
CM_ SG_ 3221225472 HTCabVlvPosn "High Temp Cabin Valve position";
CM_ SG_ 3221225472 HTShtOffVlvReq "High temp shut off valve request; [0] = Open, [1] = Closed";
CM_ SG_ 3221225472 HVBatCritCondT "High Voltage Battery Temperature Critical Condition, [1] = True";
CM_ SG_ 3221225472 EC_BU_CBC15A "Backup for CBC ecu configuration 15A";
CM_ SG_ 3221225472 EC_BU_CBC15B "Backup for CBC ecu configuration 15B";
CM_ SG_ 3221225472 EC_BU_ECUCfg15_Stat "Backup for ECU Configuration messages status 15";
CM_ SG_ 3221225472 EC_BU_Suspension "Backup for Suspension ecu configuration";
CM_ SG_ 3221225472 EC_BU_AudTel3A "Backup for audio and telematics ecu configuration 3A";
CM_ SG_ 3221225472 EC_BU_AudTel3B "Backup for audio and telematics ecu configuration 3B";
CM_ SG_ 3221225472 EC_BU_ECUCfg16_Stat "Backup for ECU Configuration messages status 16";
CM_ SG_ 3221225472 EC_BU_ECUCfg17_Stat "Backup for ECU Configuration messages status 17";
CM_ SG_ 3221225472 EC_BU_PTS "Backup for park assist ecu configuration";
CM_ SG_ 3221225472 AutoParkSts "EPB auto park brake function available status";
CM_ SG_ 3221225472 ClampForce "EPB clamp force";
CM_ SG_ 3221225472 CRC_EPB_1 "CRC-checksum byte 1 to 7 according to SAE J1850";
CM_ SG_ 3221225472 EPBSts "EPB status; Enable = [1]";
CM_ SG_ 3221225472 EPBWarningLampReq "EPB warning (fault) lamp active request";
CM_ SG_ 3221225472 FunctionLamp "EPB function lamp active request";
CM_ SG_ 3221225472 MC_EPB_1 "Message counter";
CM_ SG_ 3221225472 ServiceModeSts "EPB service mode; Service mode = [1]";
CM_ SG_ 3221225472 TextDisplay "Text message display request";
CM_ SG_ 3221225472 CFG_FEATURE "Configurable feature";
CM_ SG_ 3221225472 CFG_SET "Specific setting or value (see reference)";
CM_ SG_ 3221225472 CFG_STAT_RQ "Configurable feature status request";
CM_ SG_ 3221225472 AHB_ENBL "Auto highbeam enable";
CM_ SG_ 3221225472 ChargeReq "Request for scheduled charge; Charge now = [1]";
CM_ SG_ 3221225472 HVAC_CLNT_FLW_MIN "HVAC coolant flow minimum request";
CM_ SG_ 3221225472 ICS_btn_16 "PPA pressed";
CM_ SG_ 3221225472 ICS_btn_17 "PTS Off pressed";
CM_ SG_ 3221225472 ICS_btn_18 "LDW Off pressed";
CM_ SG_ 3221225472 phone_pop_up_active "Phone pop up is active; True = [1]";
CM_ SG_ 3221225472 PLG_Stat "Power liftgate status";
CM_ SG_ 3221225472 TRAC_PSD "Traction on/off button pressed; [0] = Not Pressed, [1] = Pressed";
CM_ SG_ 3221225472 ECM_APPL2 "Application";
CM_ SG_ 3221225472 ECM_APPL1 "Application";
CM_ SG_ 3221225472 BatPwrUsageDisp "Battery power usage for HMI, in KW";
CM_ SG_ 3221225472 BatPwrUsageDisp_V "Validity bit for signal BatPwrUsageDisp, 0=Valid";
CM_ SG_ 3221225472 EngPwrUsageDisp "Engine power usage for HMI, in KW";
CM_ SG_ 3221225472 EngPwrUsageDisp_V "Validity bit for signal EngPwrUsageDisp, 0=Valid";
CM_ SG_ 3221225472 HVACPwrUsageDisp "HVAC power usage for HMI, in KW";
CM_ SG_ 3221225472 HVACPwrUsageDisp_V "Validity bit for signal HVACPwrUsageDisp, 0=Valid";
CM_ SG_ 3221225472 HVBatSOC_HCP "High voltage battery state of charge";
CM_ SG_ 3221225472 HVBatSOCV_HCP "High voltage battery state of charge validity: invalid = [1]";
CM_ SG_ 3221225472 MtrPwrUsageDisp "Motor power usage for HMI, in KW";
CM_ SG_ 3221225472 MtrPwrUsageDisp_V "Validity bit for signal MtrPwrUsageDisp, 0=Valid";
CM_ SG_ 3221225472 ECM_APPL3 "CCP synchronous - TDC event DAQ";
CM_ SG_ 3221225472 ECM_APPL4 "CCP 5ms DAQ  (from ENGINE to external tool)";
CM_ SG_ 3221225472 VC_BU_ABSM "Backup for Active Blind Spot present; present = [1]";
CM_ SG_ 3221225472 VC_BU_ACC_Type "Backup for type of adaptive cruise control (ACC) system present";
CM_ SG_ 3221225472 VC_BU_AS_ERS "Backup for shift feature autostick / electronic range select status";
CM_ SG_ 3221225472 VC_BU_AxleLockerPrsnt "Backup for axle locker configuration";
CM_ SG_ 3221225472 VC_BU_DampingPrsnt "Backup for ASCM contains active damping; present = [1]";
CM_ SG_ 3221225472 VC_BU_DST_Present "Backup for dynamic steering torque present; True = [1]";
CM_ SG_ 3221225472 VC_BU_eShifter_Prsnt "Backup for e-shifter present; present = [1]";
CM_ SG_ 3221225472 VC_BU_FullSpeedRange_FCW "Backup for full speed range forward collision warning plus system present; Present = 1";
CM_ SG_ 3221225472 VC_BU_HybridType "Backup for identify the kind of hybrid vehicle";
CM_ SG_ 3221225472 VC_BU_LDW "Lane departure warning present; present = [1]";
CM_ SG_ 3221225472 VC_BU_PBTyp "Backup for park brake type";
CM_ SG_ 3221225472 VC_BU_PdlsMdPrsnt "Backup for paddles lock-out feature; present = [1]";
CM_ SG_ 3221225472 VC_BU_RedKey "Backup for RedKey feature is present; Present = [1]";
CM_ SG_ 3221225472 VC_BU_STP_PRSNT "Backup for super trac pack present; True = [1]";
CM_ SG_ 3221225472 VC_BU_SUNR_Prsnt "Backup for sunroof is present; True = 1";
CM_ SG_ 3221225472 VC_BU_SuspPrsnt "backup for ASCM contains suspension; present = [1]";
CM_ SG_ 3221225472 VC_BU_SVC_Prsnt "Backup for surround view camera; present = [1]";
CM_ SG_ 3221225472 VC_BU_TeenKey "Backup for teenKey feature is present; Present = [1]";
CM_ SG_ 3221225472 VC_BU_TPMS_Configuration "Backup for TPMS configuration";
CM_ SG_ 3221225472 VC_BU_Trans_Equipped "Backup for Transmission equipped: 0 = Automatic & 1 = Manual";
CM_ SG_ 3221225472 VC_BU_Trans_N_Hold_Prsnt "Backup for Transmission neutral hold feature; present = [1]";
CM_ SG_ 3221225472 VC_BU_TransType "Backup for automatic transmission type";
CM_ SG_ 3221225472 VC_BU_TrnsDrvMdPrsnt "Backup for transmission drive mode feature; present = [1]";
CM_ SG_ 3221225472 VC_BU_TSBM_Prsnt "Backup for TSBM LIN slave is present; True = [1]";
CM_ SG_ 3221225472 VC_BU_VehCfg7_Stat "Backup for Configuration messages status 7";
CM_ SG_ 3221225472 GPS_Date_Day "GPS date day";
CM_ SG_ 3221225472 GPS_Date_Month "GPS date month";
CM_ SG_ 3221225472 GPS_Date_Year "GPS date year";
CM_ SG_ 3221225472 GPS_UTC_Hour "GPS UTC hour";
CM_ SG_ 3221225472 GPS_UTC_Minute "GPS UTC minute";
CM_ SG_ 3221225472 GPS_UTC_Second "GPS UTC second";
CM_ SG_ 3221225472 ECM_APPL5 "CCP 10ms DAQ  (from ENGINE to external tool)";
CM_ SG_ 3221225472 NET_CFG_STAT_ePT "Network configuration status.";
CM_ SG_ 3221225472 NetCfg_AHCP_ePT "Transmission Control Processor (1=present)";
CM_ SG_ 3221225472 NetCfg_APM_ePT "Auxiliary Power Module (1=present)";
CM_ SG_ 3221225472 NetCfg_BPCM_ePT "Battery Pack Control Module (1=present)";
CM_ SG_ 3221225472 NetCfg_BSMO_ePT "Brake System Module - OBD (1=present)";
CM_ SG_ 3221225472 NetCfg_EAC_ePT "Electric AC Compressor (1=present)";
CM_ SG_ 3221225472 NetCfg_EBCM_ePT "Electronic Boost Control Module (1=present)";
CM_ SG_ 3221225472 NetCfg_ECM_ePT "Engine Controller Module (1=present)";
CM_ SG_ 3221225472 NetCfg_ESC_ePT "Electronic Stability Control (1=present)";
CM_ SG_ 3221225472 NetCfg_ESM_ePT "Electronic Shifter Module (1=present)";
CM_ SG_ 3221225472 NetCfg_HCP_ePT "Hybrid Control Processor (1=present)";
CM_ SG_ 3221225472 NetCfg_OBCM_ePT "On Board Charging Module. 1=present";
CM_ SG_ 3221225472 NetCfg_ORC_ePT "Occupant Restraint Controller (1=present)";
CM_ SG_ 3221225472 NetCfg_SCA_ePT "Smart Cluch Actuator (1=present)";
CM_ SG_ 3221225472 BU_NetCfg_SCA_ePT "Backup for Smart Cluch Actuator (1=present)";
CM_ SG_ 3221225472 BU_NetCfg_ORC_ePT "Backup for Occupant Restraint Controller (1=present)";
CM_ SG_ 3221225472 BU_NetCfg_OBCM_ePT "Backup for On Board Charging Module (1=present)";
CM_ SG_ 3221225472 BU_NetCfg_HCP_ePT "Backup for Hybrid Control Processor (1=present)";
CM_ SG_ 3221225472 BU_NetCfg_ESM_ePT "Backup for Electronic Shifter Module (1=present)";
CM_ SG_ 3221225472 BU_NetCfg_ESC_ePT "Backup for Electronic Stability Control (1=present)";
CM_ SG_ 3221225472 BU_NetCfg_ECM_ePT "Backup for Engine Controller Module (1=present)";
CM_ SG_ 3221225472 BU_NetCfg_EBCM_ePT "Backup for Electronic Boost Control Module (1=present)";
CM_ SG_ 3221225472 BU_NetCfg_EAC_ePT "Backup for Electric AC Compressor (1=present)";
CM_ SG_ 3221225472 BU_NetCfg_BSMO_ePT "Backup for Brake System Module - OBD (1=present)";
CM_ SG_ 3221225472 BU_NetCfg_BPCM_ePT "Backup for Battery Pack Control Module (1=present)";
CM_ SG_ 3221225472 BU_NetCfg_APM_ePT "Backup for Auxiliary Power Module (1=present)";
CM_ SG_ 3221225472 BU_NetCfg_AHCP_ePT "Backup for Auxiliary Hybrid Control Processor (1=present)";
CM_ SG_ 3221225472 BU_NET_CFG_STAT_ePT "Backup for network configuration status";
CM_ SG_ 3221225472 ECM_APPL6 "CCP 80ms DAQ  (from ENGINE to external tool)";
CM_ SG_ 3221225472 DateTmFormat2 "Date and Time Format";
CM_ SG_ 3221225472 WeekdayTmHour_End "Time of day during the weekday: Hours";
CM_ SG_ 3221225472 WeekdayTmHour_Start "Time of day during the weekday: Hours";
CM_ SG_ 3221225472 WeekdayTmMinute_End "Time of day during the weekday: Minutes";
CM_ SG_ 3221225472 WeekdayTmMinute_Start "Time of day during the weekday: Minutes";
CM_ SG_ 3221225472 WeekendTmHour_End "Time of day during the weekend: Hours";
CM_ SG_ 3221225472 WeekendTmHour_Start "Time of day during the weekend: Hours";
CM_ SG_ 3221225472 WeekendTmMinute_End "Time of day during the weekend: Minutes";
CM_ SG_ 3221225472 WeekendTmMinute_Start "Time of day during the weekend: Minutes";
CM_ SG_ 3221225472 ECM_APPL7 "Application";
CM_ SG_ 3221225472 VC_BU_ACC_DLY_CSO "Backup for Power accessory delay customer settings menu";
CM_ SG_ 3221225472 VC_BU_AFLS_CSO "Backup for Adaptive front light system customer settings menu";
CM_ SG_ 3221225472 VC_BU_AMB_DMR_CSO "Backup for Ambient dimmer customer settings menu";
CM_ SG_ 3221225472 VC_BU_ASCM_TJ_CSO "Backup for Tire jack mode customer settings menu";
CM_ SG_ 3221225472 VC_BU_ASCM_WRN_CSO "Backup for Air suspension warning customer settings menu";
CM_ SG_ 3221225472 VC_BU_AUTO_AERO_CSO "Backup for Automatic aero mode customer settings menu";
CM_ SG_ 3221225472 VC_BU_AUTO_HB_CSO "Backup for Auto high beam customer settings menu";
CM_ SG_ 3221225472 VC_BU_AUTO_PRK_CSO "Backup for Auto park customer settings menu";
CM_ SG_ 3221225472 VC_BU_AUX_SWS_CSO "Backup for Auxiliary switches customer settings menu";
CM_ SG_ 3221225472 VC_BU_BLIND_SPOT_CSO "Backup for Blind spot alert customer settings menu";
CM_ SG_ 3221225472 VC_BU_CAPACITY_CSO "Backup for Capacity unit customer settings menu";
CM_ SG_ 3221225472 VC_BU_CHMSL_LINE_CSO "Backup for CHMSL line customer settings menu";
CM_ SG_ 3221225472 VC_BU_CLK_DSP_CSO "Backup for Clock display customer settings menu";
CM_ SG_ 3221225472 VC_BU_CMP_CAL_CSO "Backup for Compass calibration customer settings menu";
CM_ SG_ 3221225472 VC_BU_CMP_VAR_CSO "Backup for Compass variance customer settings menu";
CM_ SG_ 3221225472 VC_BU_CMRA_GRDLNS_CSO "Backup for Rear view camera gridlines customer settings menu";
CM_ SG_ 3221225472 VC_BU_CONS_CSO "Backup for Consumption unit customer settings menu";
CM_ SG_ 3221225472 VC_BU_DCS_CSO "Backup for Auto on driver comfort customer settings menu";
CM_ SG_ 3221225472 VC_BU_DISTANCE_CSO "Backup for Distance unit customer settings menu";
CM_ SG_ 3221225472 VC_BU_DR_LK_CSO "Backup for Auto door lock customer settings menu";
CM_ SG_ 3221225472 VC_BU_DR_UNLK_CSO "Backup for Auto door unlock customer settings menu";
CM_ SG_ 3221225472 VC_BU_DRL_CSO "Backup for Daytime running lights customer settings menu";
CM_ SG_ 3221225472 VC_BU_EASY_EXIT_CSO "Backup for Easy exit seat customer settings menu";
CM_ SG_ 3221225472 VC_BU_ENTRY_EXIT_CSO "Backup for Auto entry exit mode customer settings menu";
CM_ SG_ 3221225472 VC_BU_EPB_SERV_CSO "Backup for EPB service mode customer settings menu";
CM_ SG_ 3221225472 VC_BU_EPS_CSO "Backup for electric power steering customer settings menu";
CM_ SG_ 3221225472 VC_BU_FCW_BRK_CSO "Backup for Forward collision mitigation braking customer settings menu";
CM_ SG_ 3221225472 VC_BU_FCW_CSO "Backup for Forward collision warning customer settings menu";
CM_ SG_ 3221225472 VC_BU_FLSH_LMP_LK_CSO "Backup for Flash lamps with lock customer settings menu";
CM_ SG_ 3221225472 VC_BU_HL_DRP_CSO "Backup for Headlamp drop customer settings menu";
CM_ SG_ 3221225472 VC_BU_HL_OFF_DLY_CSO "Backup for Headlamp off delay customer settings menu";
CM_ SG_ 3221225472 VC_BU_HL_WPR_CSO "Backup for Headlamps on with wiper customer settings menu";
CM_ SG_ 3221225472 VC_BU_HRN_RMT_LK_CSO "Backup for Sound horn with remote lock customer settings menu";
CM_ SG_ 3221225472 VC_BU_HRN_RMT_LWR_CSO "Backup for Sound horn with remote lower customer settings menu";
CM_ SG_ 3221225472 VC_BU_HRN_RMT_ST_CSO "Backup for Sound horn with remote start customer settings menu";
CM_ SG_ 3221225472 VC_BU_HSA_CSO "Backup for Hill start assist customer settings menu";
CM_ SG_ 3221225472 VC_BU_ILL_APPRCH_CSO "Backup for Illuminated approach customer settings menu";
CM_ SG_ 3221225472 VC_BU_LDW_TRQ_CSO "Backup for Lane departure torque customer settings menu";
CM_ SG_ 3221225472 VC_BU_LDW_WRN_CSO "Backup for Lane departure warning customer settings menu";
CM_ SG_ 3221225472 VC_BU_LGHT_RMT_LWR_CSO "Backup for Flash lights with remote lower customer settings menu";
CM_ SG_ 3221225472 VC_BU_NAV_TRN_CSO "Backup for Nav turn by turn customer settings menu";
CM_ SG_ 3221225472 VC_BU_PE_CSO "Backup for Passive entry customer settings menu";
CM_ SG_ 3221225472 VC_BU_PER_SHFT_ENBL_CSO "Backup for Performance shift enable customer settings menu";
CM_ SG_ 3221225472 VC_BU_PER_SHFT_RPM_CSO "Backup for Performance shift rpm customer settings menu";
CM_ SG_ 3221225472 VC_BU_PLG_CHM_CSO "Backup for Power liftgate chime customer settings menu";
CM_ SG_ 3221225472 VC_BU_POLICE_PE_CSO "Backup for police passive entry settings menu; Present = [1]";
CM_ SG_ 3221225472 VC_BU_POWER_CSO "Backup for Power unit customer settings menu";
CM_ SG_ 3221225472 VC_BU_PRESSURE_CSO "Backup for Pressure unit customer settings menu";
CM_ SG_ 3221225472 VC_BU_PRK_AST_BRK_CSO "Backup for park assist brake customer settings menu";
CM_ SG_ 3221225472 VC_BU_PRK_AST_CSO "Backup for park assist customer settings menu";
CM_ SG_ 3221225472 VC_BU_PRK_FT_VOL_CSO "Backup for park assist front volume customer settings menu";
CM_ SG_ 3221225472 VC_BU_PRK_RR_VOL_CSO "Backup for park assist rear volume customer settings menu";
CM_ SG_ 3221225472 VC_BU_PTO_CSO "Backup for Power take off customer settings menu";
CM_ SG_ 3221225472 VC_BU_RAIN_WPR_CSO "Backup for Rain sensitive wipers customer settings menu";
CM_ SG_ 3221225472 VC_BU_REAR_CMRA_CSO "Backup for Rear camera customer settings menu";
CM_ SG_ 3221225472 VC_BU_VehCfgCSO1_Stat "Backup for Configuration message CSO1 status";
CM_ SG_ 3221225472 VC_BU_AIRBAG_ON_CSO "Backup for Passenger airbag on/off customer setting menu present. Present = 1.";
CM_ SG_ 3221225472 VC_BU_EPB_ON_CSO "Backup for EPB on/off customer setting menu present. Present = 1.";
CM_ SG_ 3221225472 VC_BU_FCW_SW_CSO "Backup for FCW Switch customer setting menu present.  Present = 1";
CM_ SG_ 3221225472 VC_BU_FLSH_LMP_SLDR_CSO "Backup for flash lamps with sliding door customer settings menu; Present = [1]";
CM_ SG_ 3221225472 VC_BU_FUEL_SAV_CSO "Backup for Fuel Saver settings menu; Present = [1]";
CM_ SG_ 3221225472 VC_BU_HANDS_FREE_LFT_CSO "Backup for Hands free liftgate customer setting menu: Present = 1";
CM_ SG_ 3221225472 VC_BU_HANDS_FREE_SLDR_CSO "Backup for Hands free sliding door customer setting menu: Present = 1";
CM_ SG_ 3221225472 VC_BU_HOLD_N_GO_CSO "Backup for Hold and go customer setting menu: Present = 1";
CM_ SG_ 3221225472 VC_BU_LDW_ON_CSO "Backup for LDW on/off customer setting menu present.  Present = 1.";
CM_ SG_ 3221225472 VC_BU_PADDLE_SHIFT_CSO "Backup for paddle shifter customer setting menu present.  Present = [1]";
CM_ SG_ 3221225472 VC_BU_PRK_ASST_TYPE_CSO "Backup for Park assist type customer setting menu present. Present = 1.";
CM_ SG_ 3221225472 VC_BU_PWR_FLD_MRR_CSO "Backup for Power folding mirror customer setting menu: Present = 1";
CM_ SG_ 3221225472 VC_BU_RDY_DRV_CSO "Backup for disable ready to drive popup customer settings menu.  Present = 1";
CM_ SG_ 3221225472 VC_BU_REAR_CMRA_DLY_CSO "Backup for Rear view camera delay customer settings menu";
CM_ SG_ 3221225472 VC_BU_RKE_MEM_CSO "Backup for RKE linked to memory customer settings menu";
CM_ SG_ 3221225472 VC_BU_RKE_UNLK_CSO "Backup for RKE unlock customer settings menu";
CM_ SG_ 3221225472 VC_BU_SLD_DR_ALRT_CSO "Backup for Sliding door alert customer setting menu: Present = 1";
CM_ SG_ 3221225472 VC_BU_SLD_DR_CHM_CSO "Backup for Sliding door chime customer setting menu present: Present = 1";
CM_ SG_ 3221225472 VC_BU_SPEED_CSO "Backup for Speed unit customer settings menu";
CM_ SG_ 3221225472 VC_BU_SPEED_WARNING_CSO "Backup for Speed warning  customer setting";
CM_ SG_ 3221225472 VC_BU_SVC_DELAY_CSO "Backup for Surround view camera delay customer setting menu: Present = 1";
CM_ SG_ 3221225472 VC_BU_SVC_GRIDLINES_CSO "Backup for Surround view camera gridlines customer setting menu: Present = 1";
CM_ SG_ 3221225472 VC_BU_TEEN_AUTO_HB_CSO "Backup for Teen key automatic highbeam customer setting menu: Present = 1";
CM_ SG_ 3221225472 VC_BU_TEEN_BLIND_SPOT_CSO "Backup for Teen key blind spot customer setting menu: Present = 1";
CM_ SG_ 3221225472 VC_BU_TEEN_FCW_BRK_CSO "Backup for Teen key FCW braking customer setting menu: Present = 1";
CM_ SG_ 3221225472 VC_BU_TEEN_FCW_SENS_CSO "Backup for Teen key FCW sensitivity customer setting menu: Present = 1";
CM_ SG_ 3221225472 VC_BU_TEEN_FT_PRK_VOL_CSO "Backup for Teen key front park assist chime volume customer setting menu: Present = 1";
CM_ SG_ 3221225472 VC_BU_TEEN_FUEL_POPUP_CSO "Backup for Teen key fuel pop-up customer setting menu: Present = 1";
CM_ SG_ 3221225472 VC_BU_TEEN_FUEL_WRN_CSO "Backup for Teen key early fuel warning customer setting menu: Present = 1";
CM_ SG_ 3221225472 VC_BU_TEEN_LGHT_WPR_CSO "Backup for Teen key lights on with wipers customer setting menu: Present = 1";
CM_ SG_ 3221225472 VC_BU_TEEN_MAX_SPEED_CSO "Backup for Teen key max speed customer setting menu: Present = 1";
CM_ SG_ 3221225472 VC_BU_TEEN_PLG_CHIME_CSO "Backup for Teen key power lift gate chime customer setting menu: Present = 1";
CM_ SG_ 3221225472 VC_BU_TEEN_PRK_ASST_CSO "Backup for Teen key park assist customer setting menu: Present = 1";
CM_ SG_ 3221225472 VC_BU_TEEN_RAIN_WPR_CSO "Backup for Teen key rain sensitive wiper customer setting menu: Present = 1";
CM_ SG_ 3221225472 VC_BU_TEEN_RR_PRK_VOL_CSO "Backup for Teen key rear park assist chime volume customer setting menu: Present = 1";
CM_ SG_ 3221225472 VC_BU_TEEN_SLD_DR_ALRT_CSO "Backup for Teen key sliding door alert customer setting menu: Present = 1";
CM_ SG_ 3221225472 VC_BU_TEEN_SLD_DR_CHM_CSO "Backup for Teen key sliding door chime customer setting menu present: Present = 1";
CM_ SG_ 3221225472 VC_BU_TEMP_CSO "Backup for Temperature Unit settings menu; Present = [1]";
CM_ SG_ 3221225472 VC_BU_TLT_MRR_CSO "Backup for Tilt mirror in reverse customer settings menu";
CM_ SG_ 3221225472 VC_BU_TORQUE_CSO "Backup for Torque unit customer settings menu";
CM_ SG_ 3221225472 VC_BU_TRLR_CSO "Backup for Trailer selected customer settings menu";
CM_ SG_ 3221225472 VC_BU_TRLR_NAME_CSO "Backup for Trailer name customer settings menu";
CM_ SG_ 3221225472 VC_BU_TRLR_TYPE_CSO "Backup for Trailer type customer settings menu";
CM_ SG_ 3221225472 VC_BU_TRNS_MD_CSO "Backup for Transport mode customer settings menu";
CM_ SG_ 3221225472 VC_BU_US_METRIC_CSO "Backup for US metric customer settings menu";
CM_ SG_ 3221225472 VC_BU_VehCfgCSO2_Stat "Backup for Configuration message CSO2 status";
CM_ SG_ 3221225472 VC_BU_WHL_ALGN_CSO "Backup for Wheel alignment customer settings menu";
CM_ SG_ 3221225472 NAV_GrpNum "NAV group number";
CM_ SG_ 3221225472 NAV_GrpTyp "NAV group type";
CM_ SG_ 3221225472 NAV_HiGrpMark "NAV high group mark";
CM_ SG_ 3221225472 NAV_TEXT "NAV data field";
CM_ SG_ 3221225472 Electric_Dist_Miles "Electric distance traveled during IgnCycle in US miles";
CM_ SG_ 3221225472 Hybrid_Dist_Miles "Hybrid distance traveled during IgnCycle in US miles";
CM_ SG_ 3221225472 Electric_Dist_Kilometers "Electric distance traveled during IgnCycle in kilometers";
CM_ SG_ 3221225472 Hybrid_Dist_Kilometers "Hybrid distance traveled during IgnCycle in kilometers";
CM_ SG_ 3221225472 EC_BU_ECUCfg14_Stat "Backup for ECU Configuration messages status 14";
CM_ SG_ 3221225472 EC_BU_CBC14B "Backup for CBC ecu configuration 14B";
CM_ SG_ 3221225472 EC_BU_CBC14A "Backup for CBC ecu configuration 14A";
CM_ SG_ 3221225472 EC_BU_ECUCfg13_Stat "Backup for ECU Configuration messages status 13";
CM_ SG_ 3221225472 EC_BU_CBC13B "Backup for CBC ecu configuration 13B";
CM_ SG_ 3221225472 EC_BU_CBC13A "Backup for CBC ecu configuration 13A";
CM_ SG_ 3221225472 EC_BU_ECUCfg12_Stat "Backup for ECU Configuration messages status 12";
CM_ SG_ 3221225472 EC_BU_Cluster5C "Backup for Instrument cluster ecu configuration 5C";
CM_ SG_ 3221225472 EC_BU_Cluster5B "Backup for Instrument cluster ecu configuration 5B";
CM_ SG_ 3221225472 EC_BU_Cluster5A "Backup for Instrument cluster ecu configuration 5A";
CM_ SG_ 3221225472 EC_BU_ECUCfg11_Stat "Backup for ECU Configuration messages status 11";
CM_ SG_ 3221225472 EC_BU_CBC11 "Backup for CBC ecu configuration 11";
CM_ SG_ 3221225472 EC_BU_CBC10B "Backup for CBC ecu configuration 10B";
CM_ SG_ 3221225472 EC_BU_CBC10A "Backup for CBC ecu configuration 10A";
CM_ SG_ 3221225472 EC_BU_ECUCfg10_Stat "Backup for ECU Configuration messages status 10";
CM_ SG_ 3221225472 EC_BU_Cluster4 "Backup for Instrument cluster ecu configuration 4";
CM_ SG_ 3221225472 EC_BU_Cluster3B "Backup for Instrument cluster ecu configuration 3B";
CM_ SG_ 3221225472 EC_BU_Cluster3A "Backup for Instrument cluster ecu configuration 3A";
CM_ SG_ 3221225472 EC_BU_ITM "Backup for ITM ecu configuration";
CM_ SG_ 3221225472 EC_BU_ECUCfg9_Stat "Backup for ECU Configuration messages status 9";
CM_ SG_ 3221225472 EC_BU_CBC9B "Backup for CBC configuration 9B";
CM_ SG_ 3221225472 EC_BU_CBC9A2 "Backup for CBC configuration 9A2";
CM_ SG_ 3221225472 EC_BU_CBC9A1 "Backup for CBC configuration 9A1";
CM_ SG_ 3221225472 BU_NetCfg_VTM "Backup for vehicle theft / tax module (1=present)";
CM_ SG_ 3221225472 BU_NetCfg_VSIM "Backup for Vehicle System Interface Module (1=present)";
CM_ SG_ 3221225472 BU_NetCfg_VRM "Backup for Video Routing Module (1=present)";
CM_ SG_ 3221225472 BU_NetCfg_VES3_I "Backup for CAN I Video Ent. System screen 1 Module (1=present)";
CM_ SG_ 3221225472 BU_NetCfg_VES2_I "Backup for CAN I Video Ent. System screen 2 Module (1=present)";
CM_ SG_ 3221225472 BU_NetCfg_TMM "Backup for CAN I Track Mapping Module (1=present)";
CM_ SG_ 3221225472 BU_NetCfg_TGW "Backup for Telematics gateway (1=present)";
CM_ SG_ 3221225472 BU_NetCfg_TBM "Backup for Telematics Box Module (1=present)";
CM_ SG_ 3221225472 BU_NetCfg_RBSS "Backup for Right Blind-Spot Module (1=present)";
CM_ SG_ 3221225472 BU_NetCfg_RBC "Backup for Rear Body Controller Module (1=present)";
CM_ SG_ 3221225472 BU_NetCfg_PTCM "Backup for Power Top Control Module (1=present)";
CM_ SG_ 3221225472 BU_NetCfg_PSD_RT "Backup for Power Sliding Door Right Module (1=present)";
CM_ SG_ 3221225472 BU_NetCfg_PSD_LT "Backup for Power Sliding Door Left Module (1=present)";
CM_ SG_ 3221225472 BU_NetCfg_PLG "Backup for Power Liftgate Module (1=present)";
CM_ SG_ 3221225472 BU_NetCfg_MSM_PASS "Backup for CAN I Memory Seat Module Passenger (1=present)";
CM_ SG_ 3221225472 BU_NetCfg_MSM "Backup for Memory Seat Module (1=present)";
CM_ SG_ 3221225472 BU_NetCfg_ITM "Backup for Intrusion module (1=present)";
CM_ SG_ 3221225472 BU_NetCfg_ICS_R "Backup for CAN I Integrated rear Center Stack Module (1=present)";
CM_ SG_ 3221225472 BU_NetCfg_ICS_I "Backup for CAN I Integrated Center Stack Module (1=present)";
CM_ SG_ 3221225472 BU_NetCfg_HVAC_R "Backup for CAN I Rear Heating Ventilation Air Conditioning (1=present)";
CM_ SG_ 3221225472 BU_NetCfg_HVAC "Backup for Heating Ventilation Air Conditioning (1=present)";
CM_ SG_ 3221225472 BU_NetCfg_HFM_CTM "Backup for Convergence Telematics Module (1=present)";
CM_ SG_ 3221225472 BU_NetCfg_FSM "Backup for Folding Seat Module (1=present)";
CM_ SG_ 3221225472 BU_NetCfg_DVD_CDM "Backup for CAN I in-dash disc player module (1=present)";
CM_ SG_ 3221225472 BU_NetCfg_DTV "Backup for Digital TV Module (1=present)";
CM_ SG_ 3221225472 BU_NetCfg_DCSD "Backup for Disassociated Center Stack Display Module (1=present)";
CM_ SG_ 3221225472 BU_NetCfg_DCM_RR "Backup for Door Control Module Rear Right (1=present)";
CM_ SG_ 3221225472 BU_NetCfg_DCM_RL "Backup for Door Control Module Rear Left (1=present)";
CM_ SG_ 3221225472 BU_NetCfg_DCM_PASS "Backup for Door Control Module Passenger (1=present)";
CM_ SG_ 3221225472 BU_NetCfg_DCM_DR "Backup for Door Control Module Driver (1=present)";
CM_ SG_ 3221225472 BU_NetCfg_CVPM "Backup for CAN I Central Vision Processing Module (1=present)";
CM_ SG_ 3221225472 BU_NetCfg_CSWM "Backup for Comfot Seats and Wheel Module (1=present)";
CM_ SG_ 3221225472 BU_NetCfg_CRSM "Backup for CAN I Comfort Rear Seat Module (1=present)";
CM_ SG_ 3221225472 BU_NetCfg_CLOCK "Backup for CAN I Clock Module (1=present)";
CM_ SG_ 3221225472 BU_NetCfg_CBC_IN "Backup for Common Body Controller Int Bus (1=present)";
CM_ SG_ 3221225472 BU_NetCfg_BSM "Backup for Blind-Spot Module (1=present)";
CM_ SG_ 3221225472 BU_NetCfg_ANC_I "Backup for Active Noise Cancellation interior (1=present)";
CM_ SG_ 3221225472 BU_NetCfg_AMP_I "Backup for CAN I Amplifier Module (1=present)";
CM_ SG_ 3221225472 BU_NET_CFG_STAT_INT "Backup for network configuration status";
CM_ SG_ 3221225472 BU_NetCfg_VSIM_C "Backup for Vehicle System Interface Module (1=present)";
CM_ SG_ 3221225472 BU_NetCfg_TPM "Backup for Tire Pressure Monitor (1=present)";
CM_ SG_ 3221225472 BU_NetCfg_TCM "Backup for Automatic Transmission Controller (1=present)";
CM_ SG_ 3221225472 BU_NetCfg_SCCM "Backup for Steering Column Control Module (1=present)";
CM_ SG_ 3221225472 BU_NetCfg_RF_HUB "Backup for RF HUB Node (1=present)";
CM_ SG_ 3221225472 BU_NetCfg_PTS "Backup for Parktronics System (1=present)";
CM_ SG_ 3221225472 BU_NetCfg_PASS_PT "Backup for Personal Assistant Safety System Module PT Bus (1=present)";
CM_ SG_ 3221225472 BU_NetCfg_ORC "Backup for Occupant Restraint Controller (1=present)";
CM_ SG_ 3221225472 BU_NetCfg_OCM "Backup for Occupant Classification Module (1=present)";
CM_ SG_ 3221225472 BU_NetCfg_ITBM "Backup for Integrated Trailer Brake Module (1=present)";
CM_ SG_ 3221225472 BU_NetCfg_IC "Backup for Instrument Cluster (1=present)";
CM_ SG_ 3221225472 BU_NetCfg_HCP "Backup for Hybrid Control Processor (1=present)";
CM_ SG_ 3221225472 BU_NetCfg_HaLF "Backup for Haptic Lane Feedback module (1=present)";
CM_ SG_ 3221225472 BU_NetCfg_FDCM "Backup for Final Drive Control Module (1=present)";
CM_ SG_ 3221225472 BU_NetCfg_ESM "Backup for Electronic Shift Module (1=present)";
CM_ SG_ 3221225472 BU_NetCfg_ESL "Backup for Electric Steering Lock (1=present)";
CM_ SG_ 3221225472 BU_NetCfg_ESC "Backup for Electronic Stability Module / Anti-Lock Brake (1=present)";
CM_ SG_ 3221225472 BU_NetCfg_EPS "Backup for Electric Power Steering (1=present)";
CM_ SG_ 3221225472 BU_NetCfg_EPPM "Backup for  Elect. Pedestrian protection module (1=present)";
CM_ SG_ 3221225472 BU_NetCfg_EPB "Backup for Electric Park Brake Module (1=present)";
CM_ SG_ 3221225472 BU_NetCfg_ELSD "Backup for Electric Limited Slip Differential (1=present)";
CM_ SG_ 3221225472 BU_NetCfg_ECM "Backup for Engine Control Module (1=present)";
CM_ SG_ 3221225472 BU_NetCfg_DTCM "Backup for Drivetrain Control Module (1=present)";
CM_ SG_ 3221225472 BU_NetCfg_DASM "Backup for Driver Assistance System Module (1=present)";
CM_ SG_ 3221225472 BU_NetCfg_CBC_PT "Backup for Common Body Controller PT Bus (1=present)";
CM_ SG_ 3221225472 BU_NetCfg_BSMO "Backup for Brake System Module - OBD (1=present)";
CM_ SG_ 3221225472 BU_NetCfg_ASCM "Backup for Air Suspension Control Module (1=present)";
CM_ SG_ 3221225472 BU_NetCfg_ANC "Backup for Active Noise Cancellation (1=present)";
CM_ SG_ 3221225472 BU_NetCfg_AHLM "Backup for Automatic Headlamp Leveling Module (1=present)";
CM_ SG_ 3221225472 BU_NetCfg_AFLS "Backup for Advanced Front Lighting System (1=present)";
CM_ SG_ 3221225472 BU_NetCfg_ADCM "Backup for Active Damping Control Module (1=present)";
CM_ SG_ 3221225472 BU_NetCfg_ACC "Backup for Active Cruise Control (1=present)";
CM_ SG_ 3221225472 BU_NET_CFG_STAT_PT "Backup for network configuration status";
CM_ SG_ 3221225472 VC_BU_XWD "Backup for Drive configuration";
CM_ SG_ 3221225472 VC_BU_VehCfg1_Stat "Backup for Configuration messages status 1";
CM_ SG_ 3221225472 VC_BU_VEH_LINE "Backup for Vehicle line";
CM_ SG_ 3221225472 VC_BU_SSC_Prsnt "Backup for Select speed control feature is present; present = [1]";
CM_ SG_ 3221225472 VC_BU_SpecialPKG "Special sales code package";
CM_ SG_ 3221225472 VC_BU_ShftrTyp "Shifter type";
CM_ SG_ 3221225472 VC_BU_SCR_Prsnt "Backup for Urea/SCR system present; present = [1]";
CM_ SG_ 3221225472 VC_BU_RVCM_Prsnt "Backup for rear view camera (1=present)";
CM_ SG_ 3221225472 VC_BU_RemStPrsnt "Backup for Remote start present; present = [1]";
CM_ SG_ 3221225472 VC_BU_PTS_DispTyp "PTS display type and location";
CM_ SG_ 3221225472 VC_BU_PTS_Config "Backup for Parktronics system configuration";
CM_ SG_ 3221225472 VC_BU_PP_Prsnt "Backup for Performance Pages Present (1=present)";
CM_ SG_ 3221225472 VC_BU_MODEL_YEAR "Backup for Model year";
CM_ SG_ 3221225472 VC_BU_MAX_VEH_SPD "Backup for Maximum vehicle speed";
CM_ SG_ 3221225472 VC_BU_LHD_RHD "Backup for Left/right hand drive";
CM_ SG_ 3221225472 VC_BU_HdRstPrsnt "Backup for headrest present; present = [1]";
CM_ SG_ 3221225472 VC_BU_HDC_Prsnt "Backup for Hill descent feature is present; present = [1]";
CM_ SG_ 3221225472 VC_BU_EmodePrsnt "Backup for E-Mode feature present; True = [1]";
CM_ SG_ 3221225472 VC_BU_COUNTRY "Backup for Country Code";
CM_ SG_ 3221225472 VC_BU_CHMCM_Prsnt "Backup for CHMSL camera (1=present)";
CM_ SG_ 3221225472 VC_BU_BODY_STYLE "Backup for Body style";
CM_ SG_ 3221225472 VC_BU_AUTO_HB "Backup for Auto Highbeam feature present; present = [1]";
CM_ SG_ 3221225472 VC_BU_VehCfg2_Stat "Backup for Configuration messages status 2";
CM_ SG_ 3221225472 VC_BU_ThatchamPrsnt "Backup for thatcham present; present = [1]";
CM_ SG_ 3221225472 VC_BU_SpecialPKG_IC "Special sales code package";
CM_ SG_ 3221225472 VC_BU_SKIM_PRSNT "Backup for SKIM system present; present = [1]";
CM_ SG_ 3221225472 VC_BU_ShftInd_Prsnt "Backup for configuration for performance & gear shift indication";
CM_ SG_ 3221225472 VC_BU_SecPrkPrsnt "Backup for secure park feature present; present = [1]";
CM_ SG_ 3221225472 VC_BU_RunFlatTirePrsnt "Backup for run flat tires present; present = [1]";
CM_ SG_ 3221225472 VC_BU_RainSnsPrsnt "Backup for Rain sensor present; present = [1]";
CM_ SG_ 3221225472 VC_BU_PwrIvtrTyp "Backup for power inverter type";
CM_ SG_ 3221225472 VC_BU_PADS_Prsnt "Backup for Pass. airbag disable switch present; present = [1]";
CM_ SG_ 3221225472 VC_BU_OffRoad "Backup for Off road capable; present = [1]";
CM_ SG_ 3221225472 VC_BU_MemoryDRVMD_Prsnt "Backup for memory drive mode sub-feature configuration (1 = Present)";
CM_ SG_ 3221225472 VC_BU_MaxLdPressRrTr "Backup for Max Load Inflation Pressure Rear Tire";
CM_ SG_ 3221225472 VC_BU_MaxLdPressFtTr "Backup for Max Load Inflation Pressure Front Tire";
CM_ SG_ 3221225472 VC_BU_MaseratiMd "Backup for Maserati vehicle mode";
CM_ SG_ 3221225472 VC_BU_LgtLdPressRrTr "Backup for Light Load Inflation Pressure Rear Tire";
CM_ SG_ 3221225472 VC_BU_LgtLdPressFtTr "Backup for Light Load Inflation Pressure Front Tire";
CM_ SG_ 3221225472 VC_BU_FULL_SPARE "Backup for Full size spare; present = [1]";
CM_ SG_ 3221225472 VC_BU_FG_PRSNT "Backup for Flipper glass present; present = [1]";
CM_ SG_ 3221225472 VC_BU_ESCDrvMd_Prsnt "Backup for ESC drive mode sub-feature configuration (1 = Present)";
CM_ SG_ 3221225472 VC_BU_EngPowerDrvMd_Prsnt "Backup for ECM drive mode sub-feature configuration (1 = Present)";
CM_ SG_ 3221225472 VC_BU_ECO_Indicator "Backup for ECO Indicator present on vehicle; True = [1]";
CM_ SG_ 3221225472 VC_BU_DRVMD_Prsnt "Backup for drive mode feature configuration (1 = Present)";
CM_ SG_ 3221225472 VC_BU_CRUISE_PRSNT "Backup for Cruise feature is present; present = [1]";
CM_ SG_ 3221225472 VC_BU_AC_Prsnt "Backup for Vehicle is equipped with air conditioning; present = [1]";
CM_ SG_ 3221225472 VC_BU_WIN_EXPR_FEAT "Backup for Window express feature configuration";
CM_ SG_ 3221225472 VC_BU_WHL_BASE "Backup for Wheel base";
CM_ SG_ 3221225472 VC_BU_VehCfg3_Stat "Backup for Configuration messages status 3";
CM_ SG_ 3221225472 VC_BU_VEH_BRAND "Backup for Vehicle brand type";
CM_ SG_ 3221225472 VC_BU_TEMP_DISP "Backup for display outside temperature present; present = [1]";
CM_ SG_ 3221225472 VC_BU_TcaseTyp "Backup for Tcase type";
CM_ SG_ 3221225472 VC_BU_SunShade_Present "Backup for Vehicle equipped w/SunShade (1=present)";
CM_ SG_ 3221225472 VC_BU_SRT_PRSNT "Backup for Vehicle is an SRT; present = [1]";
CM_ SG_ 3221225472 VC_BU_SPORT_PRSNT "Backup for Sport mode is present; present = [1]";
CM_ SG_ 3221225472 VC_BU_SecLkPrsnt "Backup for Secondary Lock Present; [1] = True";
CM_ SG_ 3221225472 VC_BU_RKE_PRSNT "Backup for RKE system present; present = [1]";
CM_ SG_ 3221225472 VC_BU_PWR_RT_SLDR "Backup for Power right sliding door present; present = [1]";
CM_ SG_ 3221225472 VC_BU_PWR_LT_SLDR "Backup for Power left sliding door present; present = [1]";
CM_ SG_ 3221225472 VC_BU_PWR_LFT_GT "Backup for Power lift gate present; present = [1]";
CM_ SG_ 3221225472 VC_BU_Prem_TPM "Backup for Premium TPM system present; present = [1]";
CM_ SG_ 3221225472 VC_BU_POLICE "Backup for Police lighting feature; present = [1]";
CM_ SG_ 3221225472 VC_BU_PE_Prsnt "Backup for passive entry is present; present = [1]";
CM_ SG_ 3221225472 VC_BU_PDDL_PRSNT "backup for Paddle shift feature is present; present = [1]";
CM_ SG_ 3221225472 VC_BU_Liftgate_Trunk "Backup for Liftgate or trunk";
CM_ SG_ 3221225472 VC_BU_KG_Prsnt "Backup for keyless go is present; present = [1]";
CM_ SG_ 3221225472 VC_BU_IntEC_MIRR "Backup for vehicle is equipped with an interior EC mirror; present = [1]";
CM_ SG_ 3221225472 VC_BU_HVAC_Config "Backup for HVAC Configuration";
CM_ SG_ 3221225472 VC_BU_HID_HL "Backup for High intensity discharge head lamps; present = [1]";
CM_ SG_ 3221225472 VC_BU_FUEL_CAP "Backup for Fuel capacity";
CM_ SG_ 3221225472 VC_BU_FOBIKsafeENBL "Backup for FOBIK safe feature; present = [1]";
CM_ SG_ 3221225472 VC_BU_FCW "Backup for Forward Collision Warning present; present = [1]";
CM_ SG_ 3221225472 VC_BU_ESCL_Prsnt "Backup for ESCL system present; enabled=[1], disabled=[0]";
CM_ SG_ 3221225472 VC_BU_ELV_PRSNT "Backup for ELV system present; enabled=[1], disabled=[0]";
CM_ SG_ 3221225472 VC_BU_DualFuelSens "Backup for Vehicle equipped with two fuel sending units; present = [1]";
CM_ SG_ 3221225472 VC_BU_DSBL_CLK_DISP "Backup of Disable display of radio clock; 1 = clock display disabled";
CM_ SG_ 3221225472 VC_BU_DrAlrPrsnt "Backup for Door alert feature present; present = [1]";
CM_ SG_ 3221225472 VC_BU_CMS "Backup for Collision Mitigation System present; present = [1]";
CM_ SG_ 3221225472 VC_BU_CMP_DISP "Backup for display compass heading present; present = [1]";
CM_ SG_ 3221225472 VC_BU_ChassisType "Backup for chassis type (including suspension, brakes, and tires)";
CM_ SG_ 3221225472 VC_BU_Base_TPM "Backup for Base TPM system present; present = [1]";
CM_ SG_ 3221225472 VC_BU_AutoParkPrsnt "Backup for automatic transmission parking feature is present; present = [1]";
CM_ SG_ 3221225472 VC_BU_AUTO_HL "Backup for Auto headlamp feature present; present = [1]";
CM_ SG_ 3221225472 VC_BU_ADJ_PDL_PRSNT "Backup for Adjustable pedal system present (non-memory); present = [1]";
CM_ SG_ 3221225472 VC_BU_VehCfg4_Stat "Backup for Configuration messages status 4";
CM_ SG_ 3221225472 VC_BU_TIRE_CIRCUMF "Backup for Dynamic tire circumference (all or rear)";
CM_ SG_ 3221225472 VC_BU_TCASE_LO_RATIO "Backup for Transfer case low range reduction ratio";
CM_ SG_ 3221225472 VC_BU_TCASE_HI_RATIO "Backup for Transfer case high ratio";
CM_ SG_ 3221225472 VC_BU_AXLE_RATIO "Backup for Axle ratio";
CM_ SG_ 3221225472 EC_BU_ECUCfg1_Stat "Backup for ECU Configuration messages status 1";
CM_ SG_ 3221225472 EC_BU_CBC2 "Backup for CBC ecu configuration 2";
CM_ SG_ 3221225472 EC_BU_CBC1B "Backup for CBC ecu configuration 1B";
CM_ SG_ 3221225472 EC_BU_CBC1A "Backup for CBC ecu configuration 1A";
CM_ SG_ 3221225472 EC_BU_ECUCfg2_Stat "Backup for ECU Configuration messages status 2";
CM_ SG_ 3221225472 EC_BU_CBC4 "Backup for CBC ecu configuration 4";
CM_ SG_ 3221225472 EC_BU_CBC3B "Backup for CBC ecu configuration 3B";
CM_ SG_ 3221225472 EC_BU_CBC3A "Backup for CBC ecu configuration 3A";
CM_ SG_ 3221225472 EC_BU_ECUCfg3_Stat "Backup for ECU Configuration messages status 3";
CM_ SG_ 3221225472 EC_BU_AudTel2 "Backup for Audio and telematics ecu configuration 2";
CM_ SG_ 3221225472 EC_BU_AudTel1B "Backup for Audio and telematics ecu configuration 1B";
CM_ SG_ 3221225472 EC_BU_AudTel1A "Backup for Audio and telematics ecu configuration 1A";
CM_ SG_ 3221225472 EC_BU_ECUCfg4_Stat "Backup for ECU Configuration messages status 4";
CM_ SG_ 3221225472 EC_BU_Cluster2 "Backup for Instrument cluster ecu configuration 2";
CM_ SG_ 3221225472 EC_BU_Cluster1B "Backup for Instrument cluster ecu configuration 1B";
CM_ SG_ 3221225472 EC_BU_Cluster1A "Backup for Instrument cluster ecu configuration 1A";
CM_ SG_ 3221225472 EC_BU_WirelessB "Backup for Wireless ecu configurationB";
CM_ SG_ 3221225472 EC_BU_WirelessA "Backup for Wireless ecu configurationA";
CM_ SG_ 3221225472 EC_BU_Memory "Backup for Memory ecu configuration";
CM_ SG_ 3221225472 EC_BU_ECUCfg5_Stat "Backup for ECU Configuration messages status 5";
CM_ SG_ 3221225472 EC_BU_Doors "Backup for Doors ecu configuration";
CM_ SG_ 3221225472 EC_BU_Steering "Backup for steering ecu configuration";
CM_ SG_ 3221225472 EC_BU_Safety "Backup for Safety ecu configuration";
CM_ SG_ 3221225472 EC_BU_Powertrain "Backup for Powertrain ecu configuration";
CM_ SG_ 3221225472 EC_BU_ECUCfg6_Stat "Backup for ECU Configuration messages status 6";
CM_ SG_ 3221225472 EC_BU_BrakesB "Backup for Brake system ecu configurationB";
CM_ SG_ 3221225472 EC_BU_BrakesA "Backup for Brake system ecu configurationA";
CM_ SG_ 3221225472 EC_BU_ECUCfg7_Stat "Backup for ECU Configuration messages status 7";
CM_ SG_ 3221225472 EC_BU_CBC6 "Backup for CBC ecu configuration 6";
CM_ SG_ 3221225472 EC_BU_CBC5B "Backup for CBC ecu configuration 5B";
CM_ SG_ 3221225472 EC_BU_CBC5A "Backup for CBC ecu configuration 5A";
CM_ SG_ 3221225472 EC_BU_ECUCfg8_Stat "Backup for ECU Configuration messages status 8";
CM_ SG_ 3221225472 EC_BU_CBC8 "Backup for CBC ecu configuration 8";
CM_ SG_ 3221225472 EC_BU_CBC7B "Backup for CBC ecu configuration 7B";
CM_ SG_ 3221225472 EC_BU_CBC7A "Backup for CBC ecu configuration 7A";
CM_ SG_ 3221225472 WakeupRsn_HCP "Wakeup reason HCP";
CM_ SG_ 3221225472 WakeupCnt_HCP "Counter for module wakeup states during network sleep";
CM_ SG_ 3221225472 Nw_Id_HCP "Network identification no.";
CM_ SG_ 3221225472 NM_Ud_Srv_HCP "Network management userdata service no.";
CM_ SG_ 3221225472 NM_Ud_Launch_HCP "Network management userdata launch type";
CM_ SG_ 3221225472 NM_Successor_HCP "Network management logical successor";
CM_ SG_ 3221225472 NM_Sleep_Ind_HCP "Network management sleep indication; True = [1]";
CM_ SG_ 3221225472 NM_Sleep_Ack_HCP "Network management sleep acknowledge; True = [1]";
CM_ SG_ 3221225472 NM_Mode_HCP "Network management mode";
CM_ SG_ 3221225472 Awake_NwSt_HCP "Stay awake for network startup; True = [1]";
CM_ SG_ 3221225472 Awake_Diag_Actv_HCP "Stay awake for diagnostics active; True = [1]";
CM_ SG_ 3221225472 DG_RQ_GLOBAL_UDS "Diagnostic-Request";
CM_ SG_ 3221225472 VC_BU_VehCfg6_Stat "Backup for Configuration messages status 6";
CM_ SG_ 3221225472 VC_BU_TireCircumfFT "Backup for Dynamic tire circumference - front only";
CM_ SG_ 3221225472 VC_BU_Strng_Rt_Mns5 "Backup for Steering Ratio at negative angle 5";
CM_ SG_ 3221225472 VC_BU_Strng_Rt_Mns4 "Backup for Steering Ratio at negative angle 4";
CM_ SG_ 3221225472 VC_BU_Strng_Rt_Mns3 "Backup for Steering Ratio at negative angle 3";
CM_ SG_ 3221225472 VC_BU_Strng_Rt_Mns2 "Backup for Steering Ratio at negative angle 2";
CM_ SG_ 3221225472 VC_BU_Strng_Rt_Mns1 "Backup for Steering Ratio at negative angle 1";
CM_ SG_ 3221225472 VC_BU_BrkTyp "Backup for brake type configuration (M156/7)";
CM_ SG_ 3221225472 VC_BU_AQS_Prsnt "Backup for air quality sensor present; present = [1]";
CM_ SG_ 3221225472 VC_BU_AnlgDrSnsr "Analog door sensor configuration backup";
CM_ SG_ 3221225472 VC_BU_WTS_Prsnt "Backup for wait to start feature is present; present = [1]";
CM_ SG_ 3221225472 VC_BU_VehCfg5_Stat "Backup for Configuration messages status 5";
CM_ SG_ 3221225472 VC_BU_Strng_Rt_pls5 "Backup for Steering Ratio at positve angle 5";
CM_ SG_ 3221225472 VC_BU_Strng_Rt_pls4 "Backup for Steering Ratio at positve angle 4";
CM_ SG_ 3221225472 VC_BU_Strng_Rt_pls3 "Backup for Steering Ratio at positve angle 3";
CM_ SG_ 3221225472 VC_BU_Strng_Rt_pls2 "Backup for Steering Ratio at positve angle 2";
CM_ SG_ 3221225472 VC_BU_Strng_Rt_pls1 "Backup for Steering Ratio at positve angle 1";
CM_ SG_ 3221225472 VC_BU_Strng_Rt_0 "Backup for Steering Ratio at zero";
CM_ SG_ 3221225472 VC_BU_SpdLmt_PRSNT "Backup for Speed limiter is present; present = [1]";
CM_ SG_ 3221225472 VC_BU_SBR_Prsnt "Backup for seat belt reminder module is present; True = 1";
CM_ SG_ 3221225472 VC_BU_RR_DuallyPrsnt "Backup for vehicle is equipped with rear duals; present = [1]";
CM_ SG_ 3221225472 VC_BU_RearDoorLocks2DCM "Backup for Rear door lock switch present; present = [1]";
CM_ SG_ 3221225472 VC_BU_PPPA_Prsnt "Backup for semi automatic parking system present; True = 1";
CM_ SG_ 3221225472 VC_BU_ParkStopPrsnt "Backup for park with stop is present; True = 1";
CM_ SG_ 3221225472 VC_BU_OffRoadPg "Backup for off road pages present; True = [1]";
CM_ SG_ 3221225472 VC_BU_NonReg_TPIS "Backup for non-regulated tire pressure indicator system; True = 1";
CM_ SG_ 3221225472 VC_BU_LUCI_PRSNT "Backup for Luci feature present; present = [1]";
CM_ SG_ 3221225472 VC_BU_ChildDisp_Prsnt "Backup for child display feature is present; True = 1";
CM_ SG_ 3221225472 VC_BU_AmbTempLct "Backup for ambient temperature sensor location";
CM_ SG_ 3221225472 VC_BU_AmbLtgPrsnt "Backup for ambient lighting feature is present; True = 1";
CM_ SG_ 3221225472 D_RS_RF_HUB "Diagnostic-Response";
CM_ SG_ 3221225472 D_RS_IC "Diagnostic-Response";
CM_ SG_ 3221225472 D_RS_ORC "Diagnostic-Response";
CM_ SG_ 3221225472 D_RS_ESM "Diagnostic-Response";
CM_ SG_ 3221225472 D_RS_DASM "Diagnostic-Response";
CM_ SG_ 3221225472 D_RS_EPS "Diagnostic-Response";
CM_ SG_ 3221225472 D_RS_OCM "Diagnostic-Response";
CM_ SG_ 3221225472 D_RS_PTS "Diagnostic-Response";
CM_ SG_ 3221225472 D_RS_SCCM "Diagnostic-Response";
CM_ SG_ 3221225472 D_RS_HaLF "Diagnostic-Response";
CM_ SG_ 3221225472 D_RS_APM "Diagnostic-Response";
CM_ SG_ 3221225472 D_RS_EAC "Diagnostic-Response";
CM_ SG_ 3221225472 D_RS_AHCP "Diagnostic-Response";
CM_ SG_ 3221225472 D_RS_OBCM "Diagnostic-Response";
CM_ SG_ 3221225472 D_RS_CBC "Diagnostic-Response";
CM_ SG_ 3221225472 ECU_APPL_RF_HUB "ECU to External Application";
CM_ SG_ 3221225472 ECU_APPL_CBC "ECU to External Application";
CM_ SG_ 3221225472 ECU_APPL_IC "ECU to External Application";
CM_ SG_ 3221225472 ECU_APPL_ORC "ECU to External Application";
CM_ SG_ 3221225472 ECU_APPL_ESM "ECU to External Application";
CM_ SG_ 3221225472 ECU_APPL_DASM "ECU to External Application";
CM_ SG_ 3221225472 ECU_APPL_EPS "ECU to External Application";
CM_ SG_ 3221225472 ECU_APPL_OCM "ECU to External Application";
CM_ SG_ 3221225472 ECU_APPL_PTS "ECU to External Application";
CM_ SG_ 3221225472 ECU_APPL_SCCM "ECU to External Application";
CM_ SG_ 3221225472 ECU_APPL_HaLF "ECU to External Application";
CM_ SG_ 3221225472 ECU_APPL_ECM "ECU to External Application";
CM_ SG_ 3221225472 ECU_APPL_HCP "ECU to External Application";
CM_ SG_ 3221225472 ECU_APPL_EBCM "ECU to External Application";
CM_ SG_ 3221225472 ECU_APPL_BSMO "ECU to External Application";
CM_ SG_ 3221225472 SD_RS_RF_HUB "Response on Event - light";
CM_ SG_ 3221225472 SD_RS_CBC "Response on Event - light";
CM_ SG_ 3221225472 SD_RS_IC "Response on Event - light";
CM_ SG_ 3221225472 SD_RS_ORC "Response on Event - light";
CM_ SG_ 3221225472 SD_RS_ESM "Response on Event - light";
CM_ SG_ 3221225472 SD_RS_DASM "Response on Event - light";
CM_ SG_ 3221225472 SD_RS_EPS "Response on Event - light";
CM_ SG_ 3221225472 SD_RS_OCM "Response on Event - light";
CM_ SG_ 3221225472 D_RQ_CBC "Diagnostic-Request";
CM_ SG_ 3221225472 SD_RS_PTS "Response on Event - light";
CM_ SG_ 3221225472 SD_RS_SCCM "Response on Event - light";
CM_ SG_ 3221225472 SD_RS_HaLF "Response on Event - light";
CM_ SG_ 3221225472 SD_RS_ECM "Response on Event - light";
CM_ SG_ 3221225472 SD_RS_HCP "Response on Event - light";
CM_ SG_ 3221225472 SD_RS_BSMO "Response on Event - light";
CM_ SG_ 3221225472 APPL_ECU_RF_HUB "External Application to ECU";
CM_ SG_ 3221225472 APPL_ECU_CBC "External Application to ECU";
CM_ SG_ 3221225472 APPL_ECU_IC "External Application to ECU";
CM_ SG_ 3221225472 APPL_ECU_ORC "External Application to ECU";
CM_ SG_ 3221225472 APPL_ECU_ESM "External Application to ECU";
CM_ SG_ 3221225472 APPL_ECU_DASM "External Application to ECU";
CM_ SG_ 3221225472 APPL_ECU_EPS "External Application to ECU";
CM_ SG_ 3221225472 APPL_ECU_OCM "External Application to ECU";
CM_ SG_ 3221225472 APPL_ECU_PTS "External Application to ECU";
CM_ SG_ 3221225472 APPL_ECU_SCCM "External Application to ECU";
CM_ SG_ 3221225472 APPL_ECU_HaLF "External Application to ECU";
CM_ SG_ 3221225472 APPL_ECU_ECM "External Application to ECU";
CM_ SG_ 3221225472 APPL_ECU_HCP "External Application to ECU";
CM_ SG_ 3221225472 APPL_ECU_EBCM "External Application to ECU";
CM_ SG_ 3221225472 APPL_ECU_BSMO "External Application to ECU";
CM_ SG_ 3221225472 D_RQ_RF_HUB "Diagnostic-Request";
CM_ SG_ 3221225472 D_RQ_IC "Diagnostic-Request";
CM_ SG_ 3221225472 D_RQ_ORC "Diagnostic-Request";
CM_ SG_ 3221225472 D_RQ_ESM "Diagnostic-Request";
CM_ SG_ 3221225472 D_RQ_DASM "Diagnostic-Request";
CM_ SG_ 3221225472 D_RQ_EPS "Diagnostic-Request";
CM_ SG_ 3221225472 D_RQ_OCM "Diagnostic-Request";
CM_ SG_ 3221225472 D_RQ_PTS "Diagnostic-Request";
CM_ SG_ 3221225472 D_RQ_SCCM "Diagnostic-Request";
CM_ SG_ 3221225472 D_RQ_HaLF "Diagnostic-Request";
CM_ SG_ 3221225472 D_RQ_APM "Diagnostic-Request";
CM_ SG_ 3221225472 D_RQ_EAC "Diagnostic-Request";
CM_ SG_ 3221225472 D_RQ_AHCP "Diagnostic-Request";
CM_ SG_ 3221225472 D_RQ_OBCM "Diagnostic-Request";
CM_ SG_ 3221225472 DG_RQ_GLOBAL "Diagnostic-Request";
CM_ SG_ 3221225472 D_RQ_ECM "Diagnostic-Request";
CM_ SG_ 3221225472 D_RQ_HCP "Diagnostic-Request";
CM_ SG_ 3221225472 D_RQ_EBCM "Diagnostic-Request";
CM_ SG_ 3221225472 D_RQ_BSMO "Diagnostic-Request";
CM_ SG_ 3221225472 D_RQ_BPCM "Diagnostic-Request";
CM_ SG_ 3221225472 D_RS_ECM "Diagnostic-Response";
CM_ SG_ 3221225472 D_RS_HCP "Diagnostic-Response";
CM_ SG_ 3221225472 D_RS_BSMO "Diagnostic-Response";
CM_ SG_ 3221225472 D_RS_BPCM "Diagnostic-Response";
CM_ SG_ 3221225472 NewEagle_BrakPosnSnsrVlt "4095 a2d";
CM_ SG_ 2027 D_RS_EBCM "Diagnostic-Response";
CM_ BO_ 2015 "Send this to clear brake booster fault (and all engine/trans faults too)";
CM_ SG_ 2015 x7DF_byte0 "set to 0x01 to clear faults";
CM_ SG_ 2015 x7DF_byte1 "set to 0x04 to clear faults";
CM_ SG_ 2015 x7DF_byte2 "set to 0xFF to clear faults";
CM_ SG_ 2015 x7DF_byte3 "set to 0xFF to clear faults";
CM_ SG_ 2015 x7DF_byte4 "set to 0xFF to clear faults";
CM_ SG_ 2015 x7DF_byte5 "set to 0xFF to clear faults";
CM_ SG_ 2015 x7DF_byte6 "set to 0xFF to clear faults";
CM_ SG_ 2015 x7DF_byte7 "set to 0xFF to clear faults";
CM_ BO_ 1863 "UDS Diagnostic ID for brake module";
CM_ SG_ 1863 x747_byte0 "send 0x04 to clear faults";
CM_ SG_ 1863 x747_byte1 "send 0x14 (20 dec) to clear faults";
CM_ SG_ 1863 x747_byte2 "send 0xFF to clear faults";
CM_ SG_ 1863 x747_byte3 "send 0xFF to clear faults";
CM_ SG_ 1863 x747_byte4 "send 0xFF to clear faults";
CM_ SG_ 1863 x747_byte5 "send 0x00 to clear faults";
CM_ SG_ 1863 x747_byte6 "send 0x00 to clear faults";
CM_ SG_ 1863 x747_byte7 "send 0x00 to clear faults";
CM_ SG_ 1572 SD_RS_HaLF "Response on Event - light";
CM_ SG_ 1570 SD_RS_PTS "Response on Event - light";
CM_ BO_ 1543 "Tx Rate: NaNms, Std Dev: NaNms";
CM_ BO_ 1223 "UDS Diagnostic ID for brake module";
CM_ SG_ 1223 x4C7_byte1 "0x54 (84 dec) means faults were cleared";
CM_ SG_ 1100 VC_VehCfg6_Stat "Configuration messages status 6";
CM_ SG_ 1100 VC_TireCircumfFT "Dynamic tire circumference - front only";
CM_ SG_ 1100 VC_Strng_Rt_Mns5 "Steering Ratio at negative angle 5";
CM_ SG_ 1100 VC_Strng_Rt_Mns4 "Steering Ratio at negative angle 4";
CM_ SG_ 1100 VC_Strng_Rt_Mns3 "Steering Ratio at negative angle 3";
CM_ SG_ 1100 VC_Strng_Rt_Mns2 "Steering Ratio at negative angle 2";
CM_ SG_ 1100 VC_Strng_Rt_Mns1 "Steering Ratio at negative angle 1";
CM_ SG_ 1100 VC_BrkTyp "Brake type configuration (M156/7)";
CM_ SG_ 1100 VC_AQS_Prsnt "Air quality sensor present; present = [1]";
CM_ SG_ 1100 VC_AnlgDrSnsr "Analog door sensor configuration";
CM_ SG_ 1098 VC_WTS_Prsnt "Wait to start feature is present; present = [1]";
CM_ SG_ 1098 VC_VehCfg5_Stat "Configuration messages status 5";
CM_ SG_ 1098 VC_Strng_Rt_pls5 "Steering Ratio at positve angle 5";
CM_ SG_ 1098 VC_Strng_Rt_pls4 "Steering Ratio at positve angle 4";
CM_ SG_ 1098 VC_Strng_Rt_pls3 "Steering Ratio at positve angle 3";
CM_ SG_ 1098 VC_Strng_Rt_pls2 "Steering Ratio at positve angle 2";
CM_ SG_ 1098 VC_Strng_Rt_pls1 "Steering Ratio at positve angle 1";
CM_ SG_ 1098 VC_Strng_Rt_0 "Steering Ratio at zero";
CM_ SG_ 1098 VC_SpdLmt_PRSNT "Speed limiter is present; present = [1]";
CM_ SG_ 1098 VC_SBR_Prsnt "Seat belt reminder module is present; True = 1";
CM_ SG_ 1098 VC_RR_DuallyPrsnt "Vehicle is equipped with rear duals; present = [1]";
CM_ SG_ 1098 VC_RearDoorLocks2DCM "Rear door lock switch present; present = [1]";
CM_ SG_ 1098 VC_PPPA_Prsnt "Semi automatic parking system present; present = [1]";
CM_ SG_ 1098 VC_ParkStopPrsnt "Park with stop is present; True = 1";
CM_ SG_ 1098 VC_OffRoadPg "Off road pages present; True = [1]";
CM_ SG_ 1098 VC_NonReg_TPIS "Non-regulated tire pressure indicator system; True = 1";
CM_ SG_ 1098 VC_LUCI_PRSNT "Luci feature present; present = [1]";
CM_ SG_ 1098 VC_ChildDisp_Prsnt "Child display feature is present; True = 1";
CM_ SG_ 1098 VC_AmbTempLct "Ambient temperature sensor location";
CM_ SG_ 1098 VC_AmbLtgPrsnt "Ambient lighting feature is present; True = [1]";
CM_ BO_ 1062 "Tx Rate: 743ms, Std Dev: 112.0ms";
CM_ SG_ 1059 WakeupRsn_SCCM "Wakeup reason SCCM";
CM_ SG_ 1059 WakeupCnt_SCCM "Counter for module wakeup states during network sleep";
CM_ SG_ 1059 Nw_Id_SCCM "Network identification no.";
CM_ SG_ 1059 NM_Ud_Srv_SCCM "Network management userdata service no.";
CM_ SG_ 1059 NM_Ud_Launch_SCCM "Network management userdata launch type";
CM_ SG_ 1059 NM_Successor_SCCM "Network management logical successor";
CM_ SG_ 1059 NM_Sleep_Ind_SCCM "Network management sleep indication; True = [1]";
CM_ SG_ 1059 NM_Sleep_Ack_SCCM "Network management sleep acknowledge; True = [1]";
CM_ SG_ 1059 NM_Mode_SCCM "Network management mode";
CM_ SG_ 1059 Awake_tilt_tel_Psd_SCCM "Stay awake for tilt/telescope switch actuated; True = [1]";
CM_ SG_ 1059 Awake_StwSw_Actv_SCCM "Stay awake for steering wheel switches active; True = [1]";
CM_ SG_ 1059 Awake_NwSt_SCCM "Stay awake for network startup; True = [1]";
CM_ SG_ 1059 Awake_Ignition_On_SCCM "Stay awake for ignition on; True = [1]";
CM_ SG_ 1059 Awake_HrnSwt_Actv_SCCM "Stay awake for  horn switch active; True = [1]";
CM_ SG_ 1059 Awake_FTP_Psd_SCCM "Stay awake for flash to pass lever actuated; True = [1]";
CM_ SG_ 1059 Awake_EEPROM_SCCM "Stay awake for EEPROM write access; True = [1]";
CM_ SG_ 1059 Awake_Diag_Actv_SCCM "Stay awake for diagnostics active; True = [1]";
CM_ SG_ 1050 WakeupRsn_EPS "Wakeup reason EPS";
CM_ SG_ 1050 WakeupCnt_EPS "Counter for module wakeup states during network sleep";
CM_ SG_ 1050 Nw_Id_EPS "Network identification no.";
CM_ SG_ 1050 NM_Ud_Srv_EPS "Network management userdata service no.";
CM_ SG_ 1050 NM_Ud_Launch_EPS "Network management userdata launch type";
CM_ SG_ 1050 NM_Successor_EPS "Network management logical successor";
CM_ SG_ 1050 NM_Sleep_Ind_EPS "Network management sleep indication; True = [1]";
CM_ SG_ 1050 NM_Sleep_Ack_EPS "Network management sleep acknowledge; True = [1]";
CM_ SG_ 1050 NM_Mode_EPS "Network management mode";
CM_ SG_ 1050 Awake_VSS_high_EPS "Stay awake - assist active due to vehicle speed high; True = 1";
CM_ SG_ 1050 Awake_Rampout_EPS "Stay awake - ramping assist off; True = 1";
CM_ SG_ 1050 Awake_NwSt_EPS "Stay awake for network startup; True = [1]";
CM_ SG_ 1050 Awake_IgnHigh_EPS "Stay awake - ignition high; True = 1";
CM_ SG_ 1050 Awake_EngRPM_high_EPS "Stay awake - assist active due to engine RPM high; True = 1";
CM_ SG_ 1050 Awake_Diag_Actv_EPS "Stay awake for diagnostics active; True = [1]";
CM_ SG_ 1033 WakeupRsn_SBWM "Wakeup reason SBWM";
CM_ SG_ 1033 WakeupCnt_SBWM "Counter for module wakeup states during network sleep";
CM_ SG_ 1033 Nw_Id_SBWM "Network identification no.";
CM_ SG_ 1033 NM_Ud_Srv_SBWM "Network management userdata service no.";
CM_ SG_ 1033 NM_Ud_Launch_SBWM "Network management userdata launch type";
CM_ SG_ 1033 NM_Successor_SBWM "Network management logical successor";
CM_ SG_ 1033 NM_Sleep_Ind_SBWM "Network management sleep indication; True = [1]";
CM_ SG_ 1033 NM_Sleep_Ack_SBWM "Network management sleep acknowledge; True = [1]";
CM_ SG_ 1033 NM_Mode_SBWM "Network management mode";
CM_ SG_ 1033 Awake_URS_SBWM "Stay awake for 'Unlock Run Start' hardwired input; True = [1]";
CM_ SG_ 1033 Awake_NwSt_SBWM "Stay awake for network startup; True = [1]";
CM_ SG_ 1033 Awake_Ignition_On_SBWM "Stay awake for ignition on; True = [1]";
CM_ SG_ 1033 Awake_EEPROM_SBWM "Stay awake for EEPROM write access; True = [1]";
CM_ SG_ 1033 Awake_Diag_Actv_SBWM "Stay awake for diagnostics active; True = [1]";
CM_ SG_ 1031 WakeupRsn_ESC "Wakeup reason ESC";
CM_ SG_ 1031 WakeupCnt_ESC "Counter for module wakeup states during network sleep";
CM_ SG_ 1031 Nw_Id_ESC "Network identification no.";
CM_ SG_ 1031 NM_Ud_Srv_ESC "Network management userdata service no.";
CM_ SG_ 1031 NM_Ud_Launch_ESC "Network management userdata launch type";
CM_ SG_ 1031 NM_Successor_ESC "Network management logical successor";
CM_ SG_ 1031 NM_Sleep_Ind_ESC "Network management sleep indication; True = [1]";
CM_ SG_ 1031 NM_Sleep_Ack_ESC "Network management sleep acknowledge; True = [1]";
CM_ SG_ 1031 NM_Mode_ESC "Network management mode";
CM_ SG_ 1031 Awake_Vehicle_Speed_ESC "Stay awake for vehicle speed; True = [1]";
CM_ SG_ 1031 Awake_NwSt_ESC "Stay awake for network startup; True = [1]";
CM_ SG_ 1031 Awake_Hardwire_Ignition_ESC "Stay awake for ignition on; True = [1]";
CM_ SG_ 1031 Awake_EPB_Switch_Wakeup_ESC "Stay awake for EPB switch actuation; True = [1]";
CM_ SG_ 1031 Awake_Diag_Actv_ESC "Stay awake for diagnostics active; True = [1]";
CM_ SG_ 1031 Awake_Brake_Pedal_Pressed_ESC "Stay awake for brake pedal pressed; True = [1]";
BA_DEF_ SG_  "GenSigTimeout_CBC" INT 0 65535;
BA_DEF_ SG_  "GenSigTimeout_EPS" INT 0 65535;
BA_DEF_ SG_  "GenSigTimeout_ESM" INT 0 65535;
BA_DEF_ SG_  "GenSigTimeout_ETM" INT 0 65535;
BA_DEF_ SG_  "GenSigTimeout_HaLF" INT 0 65535;
BA_DEF_ SG_  "GenSigTimeout_IC" INT 0 65535;
BA_DEF_ SG_  "GenSigTimeout_OCM" INT 0 65535;
BA_DEF_ SG_  "GenSigTimeout_ORC" INT 0 65535;
BA_DEF_ SG_  "GenSigTimeout_PTS" INT 0 65535;
BA_DEF_ SG_  "GenSigTimeout_RF_HUB" INT 0 65535;
BA_DEF_ SG_  "GenSigTimeout_SCCM" INT 0 65535;
BA_DEF_ BU_  "TpOwnSystemEcuNumber" HEX 0 255;
BA_DEF_ BU_  "TpNodeBaseAddress" HEX 0 65535;
BA_DEF_ BO_  "GenMsgStartValue" STRING ;
BA_DEF_ SG_  "GenSigSNA" STRING ;
BA_DEF_  "Version" HEX 0 255;
BA_DEF_  "NmMessageCount" INT 0 64;
BA_DEF_  "NWID" HEX 0 255;
BA_DEF_  "NBTMax" INT 0 255;
BA_DEF_  "NBTMin" INT 0 255;
BA_DEF_  "SamplePointMax" FLOAT 0 100;
BA_DEF_  "SamplePointMin" FLOAT 0 100;
BA_DEF_ SG_  "RID" STRING ;
BA_DEF_  "NWM-Basisadresse" HEX 0 536870911;
BA_DEF_  "NWM-Typ" ENUM  "zentral (MB-W210)","dezentral (MB-OSAN)","keines","VAG-OSEK","BMW-OSEK","PAG-OSEK","DBAG-OSEK";
BA_DEF_ BU_  "NWM-Knoten" ENUM  "nein","ja";
BA_DEF_ BU_  "NWM-Stationsadresse" HEX 0 63;
BA_DEF_ SG_  "FlexKomIsMotorola" ENUM  "nein","ja";
BA_DEF_ SG_  "FlexKomSigLaenge" INT 0 64;
BA_DEF_ SG_  "FlexKomSigStartPos" INT 0 63;
BA_DEF_ SG_  "FlexKomComment" STRING ;
BA_DEF_ SG_  "FlexKomSigName" STRING ;
BA_DEF_ SG_  "FlexKomSID" INT 0 2147483647;
BA_DEF_ SG_  "GenSigStartValue" HEX 0 -1;
BA_DEF_ SG_  "FlexKomSigStartValue" STRING ;
BA_DEF_ SG_  "GenSigCycleTime" INT 0 65535;
BA_DEF_ SG_  "GenSigSendType" ENUM  "cyclicX","spontanX","cyclicIfActiveX","spontanWithDelay","cyclicAndSpontanX","cyclicAndSpontanWithDelay","spontanWithRepitition","cyclicIfActiveAndSpontanWD","cyclicIfActiveFast","cyclicWithRepeatOnDemand","none";
BA_DEF_ BO_  "GenMsgNrOfRepetitions" INT 0 65535;
BA_DEF_ BO_  "GenMsgDelayTime" INT 0 65535;
BA_DEF_ BO_  "GenMsgStartDelayTime" INT 0 65535;
BA_DEF_ BO_  "GenMsgCycleTime" INT 0 65535;
BA_DEF_ BO_  "GenMsgSendType" ENUM  "cyclicX","spontanX","cyclicIfActiveX","spontanWithDelay","cyclicAndSpontanX","cyclicAndSpontanWithDelay","spontanWithRepitition","cyclicIfActiveAndSpontanWD","cyclicIfActiveFast","cyclicWithRepeatOnDemand","none";
BA_DEF_  "Baudrate" INT 0 1000000;
BA_DEF_  "VersionWeek" INT 0 53;
BA_DEF_  "VersionYear" INT 0 99;
BA_DEF_ BO_  "DiagResponse" ENUM  "nein","ja";
BA_DEF_ BO_  "DiagRequest" ENUM  "nein","ja";
BA_DEF_ BO_  "DiagState" ENUM  "nein","ja";
BA_DEF_ BO_  "App-Botschaft" ENUM  "nein","ja";
BA_DEF_ BO_  "NWM-Botschaft" ENUM  "nein","ja";
BA_DEF_  "Manufacturer" ENUM  "DBAG","VAG","BMWAG","PAG","GM";
BA_DEF_DEF_  "GenSigTimeout_CBC" 0;
BA_DEF_DEF_  "GenSigTimeout_EPS" 0;
BA_DEF_DEF_  "GenSigTimeout_ESM" 0;
BA_DEF_DEF_  "GenSigTimeout_ETM" 0;
BA_DEF_DEF_  "GenSigTimeout_HaLF" 0;
BA_DEF_DEF_  "GenSigTimeout_IC" 0;
BA_DEF_DEF_  "GenSigTimeout_OCM" 0;
BA_DEF_DEF_  "GenSigTimeout_ORC" 0;
BA_DEF_DEF_  "GenSigTimeout_PTS" 0;
BA_DEF_DEF_  "GenSigTimeout_RF_HUB" 0;
BA_DEF_DEF_  "GenSigTimeout_SCCM" 0;
BA_DEF_DEF_  "TpOwnSystemEcuNumber" 0;
BA_DEF_DEF_  "TpNodeBaseAddress" 0;
BA_DEF_DEF_  "GenMsgStartValue" "";
BA_DEF_DEF_  "GenSigSNA" "";
BA_DEF_DEF_  "Version" 160;
BA_DEF_DEF_  "NmMessageCount" 64;
BA_DEF_DEF_  "NWID" 0;
BA_DEF_DEF_  "NBTMax" 20;
BA_DEF_DEF_  "NBTMin" 10;
BA_DEF_DEF_  "SamplePointMax" 81.25;
BA_DEF_DEF_  "SamplePointMin" 75;
BA_DEF_DEF_  "RID" "";
BA_DEF_DEF_  "NWM-Basisadresse" 1024;
BA_DEF_DEF_  "NWM-Typ" "DBAG-OSEK";
BA_DEF_DEF_  "NWM-Knoten" "nein";
BA_DEF_DEF_  "NWM-Stationsadresse" 0;
BA_DEF_DEF_  "FlexKomIsMotorola" "nein";
BA_DEF_DEF_  "FlexKomSigLaenge" 0;
BA_DEF_DEF_  "FlexKomSigStartPos" 0;
BA_DEF_DEF_  "FlexKomComment" "";
BA_DEF_DEF_  "FlexKomSigName" "";
BA_DEF_DEF_  "FlexKomSID" 0;
BA_DEF_DEF_  "GenSigStartValue" 0;
BA_DEF_DEF_  "FlexKomSigStartValue" "";
BA_DEF_DEF_  "GenSigCycleTime" 0;
BA_DEF_DEF_  "GenSigSendType" "cyclicX";
BA_DEF_DEF_  "GenMsgNrOfRepetitions" 0;
BA_DEF_DEF_  "GenMsgDelayTime" 0;
BA_DEF_DEF_  "GenMsgStartDelayTime" 0;
BA_DEF_DEF_  "GenMsgCycleTime" 0;
BA_DEF_DEF_  "GenMsgSendType" "cyclicX";
BA_DEF_DEF_  "Baudrate" 500000;
BA_DEF_DEF_  "VersionWeek" 17;
BA_DEF_DEF_  "VersionYear" 14;
BA_DEF_DEF_  "DiagResponse" "nein";
BA_DEF_DEF_  "DiagRequest" "nein";
BA_DEF_DEF_  "DiagState" "nein";
BA_DEF_DEF_  "App-Botschaft" "nein";
BA_DEF_DEF_  "NWM-Botschaft" "nein";
BA_DEF_DEF_  "Manufacturer" "DBAG";
BA_ "Version" 42;
BA_ "VersionWeek" 10;
BA_ "VersionYear" 19;
BA_ "GenMsgStartValue" BO_ 2027 "0000000000000000h";
BA_ "GenMsgNrOfRepetitions" BO_ 2027 2;
BA_ "GenMsgDelayTime" BO_ 2027 20;
BA_ "DiagResponse" BO_ 2027 1;
BA_ "GenSigSNA" SG_ 2027 D_RS_EBCM "0h";
BA_ "FlexKomIsMotorola" SG_ 2027 D_RS_EBCM 1;
BA_ "FlexKomComment" SG_ 2027 D_RS_EBCM "Diagnostic-Response";
BA_ "FlexKomSigName" SG_ 2027 D_RS_EBCM "D_RS_EBCM";
BA_ "FlexKomSigLaenge" SG_ 2027 D_RS_EBCM 64;
BA_ "FlexKomSigStartPos" SG_ 2027 D_RS_EBCM 7;
BA_ "FlexKomSID" SG_ 2027 D_RS_EBCM 2129;
BA_ "FlexKomSigStartValue" SG_ 2027 D_RS_EBCM "0000000000000000h";
BA_ "GenMsgStartValue" BO_ 1572 "0000000000000000h";
BA_ "GenMsgNrOfRepetitions" BO_ 1572 2;
BA_ "GenMsgDelayTime" BO_ 1572 20;
BA_ "GenMsgSendType" BO_ 1572 1;
BA_ "GenSigSNA" SG_ 1572 SD_RS_HaLF "0h";
BA_ "FlexKomIsMotorola" SG_ 1572 SD_RS_HaLF 1;
BA_ "FlexKomComment" SG_ 1572 SD_RS_HaLF "Response on Event - light";
BA_ "FlexKomSigName" SG_ 1572 SD_RS_HaLF "SD_RS_HaLF";
BA_ "FlexKomSigLaenge" SG_ 1572 SD_RS_HaLF 64;
BA_ "FlexKomSigStartPos" SG_ 1572 SD_RS_HaLF 7;
BA_ "FlexKomSID" SG_ 1572 SD_RS_HaLF 1635;
BA_ "FlexKomSigStartValue" SG_ 1572 SD_RS_HaLF "0000000000000000h";
BA_ "GenSigSendType" SG_ 1572 SD_RS_HaLF 1;
BA_ "GenMsgStartValue" BO_ 1570 "0000000000000000h";
BA_ "GenMsgNrOfRepetitions" BO_ 1570 2;
BA_ "GenMsgDelayTime" BO_ 1570 20;
BA_ "GenMsgSendType" BO_ 1570 1;
BA_ "GenSigSNA" SG_ 1570 SD_RS_PTS "0h";
BA_ "FlexKomIsMotorola" SG_ 1570 SD_RS_PTS 1;
BA_ "FlexKomComment" SG_ 1570 SD_RS_PTS "Response on Event - light";
BA_ "FlexKomSigName" SG_ 1570 SD_RS_PTS "SD_RS_PTS";
BA_ "FlexKomSigLaenge" SG_ 1570 SD_RS_PTS 64;
BA_ "FlexKomSigStartPos" SG_ 1570 SD_RS_PTS 7;
BA_ "FlexKomSID" SG_ 1570 SD_RS_PTS 215;
BA_ "FlexKomSigStartValue" SG_ 1570 SD_RS_PTS "0000000000000000h";
BA_ "GenSigSendType" SG_ 1570 SD_RS_PTS 1;
BA_ "GenMsgStartDelayTime" BO_ 1100 70;
BA_ "GenMsgStartValue" BO_ 1100 "73FFFFFFFFFFFFFFh";
BA_ "GenMsgNrOfRepetitions" BO_ 1100 2;
BA_ "GenMsgDelayTime" BO_ 1100 20;
BA_ "GenMsgCycleTime" BO_ 1100 2000;
BA_ "GenMsgSendType" BO_ 1100 5;
BA_ "GenSigSNA" SG_ 1100 VC_VehCfg6_Stat "3h";
BA_ "FlexKomIsMotorola" SG_ 1100 VC_VehCfg6_Stat 1;
BA_ "FlexKomComment" SG_ 1100 VC_VehCfg6_Stat "Vehicle Configuration 6 Packet";
BA_ "FlexKomSigName" SG_ 1100 VC_VehCfg6_Stat "VehCfg6_Pkt";
BA_ "FlexKomSigLaenge" SG_ 1100 VC_VehCfg6_Stat 64;
BA_ "FlexKomSigStartPos" SG_ 1100 VC_VehCfg6_Stat 7;
BA_ "FlexKomSID" SG_ 1100 VC_VehCfg6_Stat 1199;
BA_ "GenSigTimeout_ORC" SG_ 1100 VC_VehCfg6_Stat 7000;
BA_ "GenSigStartValue" SG_ 1100 VC_VehCfg6_Stat 3;
BA_ "FlexKomSigStartValue" SG_ 1100 VC_VehCfg6_Stat "73FFFFFFFFFFFFFFh";
BA_ "GenSigCycleTime" SG_ 1100 VC_VehCfg6_Stat 2000;
BA_ "GenSigSendType" SG_ 1100 VC_VehCfg6_Stat 5;
BA_ "GenSigSNA" SG_ 1100 VC_TireCircumfFT "FFFFh";
BA_ "FlexKomIsMotorola" SG_ 1100 VC_TireCircumfFT 1;
BA_ "FlexKomComment" SG_ 1100 VC_TireCircumfFT "Vehicle Configuration 6 Packet";
BA_ "FlexKomSigName" SG_ 1100 VC_TireCircumfFT "VehCfg6_Pkt";
BA_ "FlexKomSigLaenge" SG_ 1100 VC_TireCircumfFT 64;
BA_ "FlexKomSigStartPos" SG_ 1100 VC_TireCircumfFT 7;
BA_ "FlexKomSID" SG_ 1100 VC_TireCircumfFT 1199;
BA_ "GenSigTimeout_ORC" SG_ 1100 VC_TireCircumfFT 7000;
BA_ "GenSigStartValue" SG_ 1100 VC_TireCircumfFT 65535;
BA_ "FlexKomSigStartValue" SG_ 1100 VC_TireCircumfFT "73FFFFFFFFFFFFFFh";
BA_ "GenSigCycleTime" SG_ 1100 VC_TireCircumfFT 2000;
BA_ "GenSigSendType" SG_ 1100 VC_TireCircumfFT 5;
BA_ "GenSigSNA" SG_ 1100 VC_Strng_Rt_Mns5 "FFh";
BA_ "FlexKomIsMotorola" SG_ 1100 VC_Strng_Rt_Mns5 1;
BA_ "FlexKomComment" SG_ 1100 VC_Strng_Rt_Mns5 "Vehicle Configuration 6 Packet";
BA_ "FlexKomSigName" SG_ 1100 VC_Strng_Rt_Mns5 "VehCfg6_Pkt";
BA_ "FlexKomSigLaenge" SG_ 1100 VC_Strng_Rt_Mns5 64;
BA_ "FlexKomSigStartPos" SG_ 1100 VC_Strng_Rt_Mns5 7;
BA_ "FlexKomSID" SG_ 1100 VC_Strng_Rt_Mns5 1199;
BA_ "GenSigStartValue" SG_ 1100 VC_Strng_Rt_Mns5 255;
BA_ "FlexKomSigStartValue" SG_ 1100 VC_Strng_Rt_Mns5 "73FFFFFFFFFFFFFFh";
BA_ "GenSigCycleTime" SG_ 1100 VC_Strng_Rt_Mns5 2000;
BA_ "GenSigSendType" SG_ 1100 VC_Strng_Rt_Mns5 5;
BA_ "GenSigSNA" SG_ 1100 VC_Strng_Rt_Mns4 "FFh";
BA_ "FlexKomIsMotorola" SG_ 1100 VC_Strng_Rt_Mns4 1;
BA_ "FlexKomComment" SG_ 1100 VC_Strng_Rt_Mns4 "Vehicle Configuration 6 Packet";
BA_ "FlexKomSigName" SG_ 1100 VC_Strng_Rt_Mns4 "VehCfg6_Pkt";
BA_ "FlexKomSigLaenge" SG_ 1100 VC_Strng_Rt_Mns4 64;
BA_ "FlexKomSigStartPos" SG_ 1100 VC_Strng_Rt_Mns4 7;
BA_ "FlexKomSID" SG_ 1100 VC_Strng_Rt_Mns4 1199;
BA_ "GenSigStartValue" SG_ 1100 VC_Strng_Rt_Mns4 255;
BA_ "FlexKomSigStartValue" SG_ 1100 VC_Strng_Rt_Mns4 "73FFFFFFFFFFFFFFh";
BA_ "GenSigCycleTime" SG_ 1100 VC_Strng_Rt_Mns4 2000;
BA_ "GenSigSendType" SG_ 1100 VC_Strng_Rt_Mns4 5;
BA_ "GenSigSNA" SG_ 1100 VC_Strng_Rt_Mns3 "FFh";
BA_ "FlexKomIsMotorola" SG_ 1100 VC_Strng_Rt_Mns3 1;
BA_ "FlexKomComment" SG_ 1100 VC_Strng_Rt_Mns3 "Vehicle Configuration 6 Packet";
BA_ "FlexKomSigName" SG_ 1100 VC_Strng_Rt_Mns3 "VehCfg6_Pkt";
BA_ "FlexKomSigLaenge" SG_ 1100 VC_Strng_Rt_Mns3 64;
BA_ "FlexKomSigStartPos" SG_ 1100 VC_Strng_Rt_Mns3 7;
BA_ "FlexKomSID" SG_ 1100 VC_Strng_Rt_Mns3 1199;
BA_ "GenSigStartValue" SG_ 1100 VC_Strng_Rt_Mns3 255;
BA_ "FlexKomSigStartValue" SG_ 1100 VC_Strng_Rt_Mns3 "73FFFFFFFFFFFFFFh";
BA_ "GenSigCycleTime" SG_ 1100 VC_Strng_Rt_Mns3 2000;
BA_ "GenSigSendType" SG_ 1100 VC_Strng_Rt_Mns3 5;
BA_ "GenSigSNA" SG_ 1100 VC_Strng_Rt_Mns2 "FFh";
BA_ "FlexKomIsMotorola" SG_ 1100 VC_Strng_Rt_Mns2 1;
BA_ "FlexKomComment" SG_ 1100 VC_Strng_Rt_Mns2 "Vehicle Configuration 6 Packet";
BA_ "FlexKomSigName" SG_ 1100 VC_Strng_Rt_Mns2 "VehCfg6_Pkt";
BA_ "FlexKomSigLaenge" SG_ 1100 VC_Strng_Rt_Mns2 64;
BA_ "FlexKomSigStartPos" SG_ 1100 VC_Strng_Rt_Mns2 7;
BA_ "FlexKomSID" SG_ 1100 VC_Strng_Rt_Mns2 1199;
BA_ "GenSigStartValue" SG_ 1100 VC_Strng_Rt_Mns2 255;
BA_ "FlexKomSigStartValue" SG_ 1100 VC_Strng_Rt_Mns2 "73FFFFFFFFFFFFFFh";
BA_ "GenSigCycleTime" SG_ 1100 VC_Strng_Rt_Mns2 2000;
BA_ "GenSigSendType" SG_ 1100 VC_Strng_Rt_Mns2 5;
BA_ "GenSigSNA" SG_ 1100 VC_Strng_Rt_Mns1 "FFh";
BA_ "FlexKomIsMotorola" SG_ 1100 VC_Strng_Rt_Mns1 1;
BA_ "FlexKomComment" SG_ 1100 VC_Strng_Rt_Mns1 "Vehicle Configuration 6 Packet";
BA_ "FlexKomSigName" SG_ 1100 VC_Strng_Rt_Mns1 "VehCfg6_Pkt";
BA_ "FlexKomSigLaenge" SG_ 1100 VC_Strng_Rt_Mns1 64;
BA_ "FlexKomSigStartPos" SG_ 1100 VC_Strng_Rt_Mns1 7;
BA_ "FlexKomSID" SG_ 1100 VC_Strng_Rt_Mns1 1199;
BA_ "GenSigStartValue" SG_ 1100 VC_Strng_Rt_Mns1 255;
BA_ "FlexKomSigStartValue" SG_ 1100 VC_Strng_Rt_Mns1 "73FFFFFFFFFFFFFFh";
BA_ "GenSigCycleTime" SG_ 1100 VC_Strng_Rt_Mns1 2000;
BA_ "GenSigSendType" SG_ 1100 VC_Strng_Rt_Mns1 5;
BA_ "GenSigSNA" SG_ 1100 VC_BrkTyp "7h";
BA_ "FlexKomIsMotorola" SG_ 1100 VC_BrkTyp 1;
BA_ "FlexKomComment" SG_ 1100 VC_BrkTyp "Vehicle Configuration 6 Packet";
BA_ "FlexKomSigName" SG_ 1100 VC_BrkTyp "VehCfg6_Pkt";
BA_ "FlexKomSigLaenge" SG_ 1100 VC_BrkTyp 64;
BA_ "FlexKomSigStartPos" SG_ 1100 VC_BrkTyp 7;
BA_ "FlexKomSID" SG_ 1100 VC_BrkTyp 1199;
BA_ "GenSigStartValue" SG_ 1100 VC_BrkTyp 7;
BA_ "FlexKomSigStartValue" SG_ 1100 VC_BrkTyp "73FFFFFFFFFFFFFFh";
BA_ "GenSigCycleTime" SG_ 1100 VC_BrkTyp 2000;
BA_ "GenSigSendType" SG_ 1100 VC_BrkTyp 5;
BA_ "GenSigSNA" SG_ 1100 VC_AQS_Prsnt "0h";
BA_ "FlexKomIsMotorola" SG_ 1100 VC_AQS_Prsnt 1;
BA_ "FlexKomComment" SG_ 1100 VC_AQS_Prsnt "Vehicle Configuration 6 Packet";
BA_ "FlexKomSigName" SG_ 1100 VC_AQS_Prsnt "VehCfg6_Pkt";
BA_ "FlexKomSigLaenge" SG_ 1100 VC_AQS_Prsnt 64;
BA_ "FlexKomSigStartPos" SG_ 1100 VC_AQS_Prsnt 7;
BA_ "FlexKomSID" SG_ 1100 VC_AQS_Prsnt 1199;
BA_ "FlexKomSigStartValue" SG_ 1100 VC_AQS_Prsnt "73FFFFFFFFFFFFFFh";
BA_ "GenSigCycleTime" SG_ 1100 VC_AQS_Prsnt 2000;
BA_ "GenSigSendType" SG_ 1100 VC_AQS_Prsnt 5;
BA_ "GenSigSNA" SG_ 1100 VC_AnlgDrSnsr "0h";
BA_ "FlexKomIsMotorola" SG_ 1100 VC_AnlgDrSnsr 1;
BA_ "FlexKomComment" SG_ 1100 VC_AnlgDrSnsr "Vehicle Configuration 6 Packet";
BA_ "FlexKomSigName" SG_ 1100 VC_AnlgDrSnsr "VehCfg6_Pkt";
BA_ "FlexKomSigLaenge" SG_ 1100 VC_AnlgDrSnsr 64;
BA_ "FlexKomSigStartPos" SG_ 1100 VC_AnlgDrSnsr 7;
BA_ "FlexKomSID" SG_ 1100 VC_AnlgDrSnsr 1199;
BA_ "FlexKomSigStartValue" SG_ 1100 VC_AnlgDrSnsr "73FFFFFFFFFFFFFFh";
BA_ "GenSigCycleTime" SG_ 1100 VC_AnlgDrSnsr 2000;
BA_ "GenSigSendType" SG_ 1100 VC_AnlgDrSnsr 5;
BA_ "GenMsgStartDelayTime" BO_ 1098 60;
BA_ "GenMsgStartValue" BO_ 1098 "C3FFFFFFFFFFFF00h";
BA_ "GenMsgNrOfRepetitions" BO_ 1098 2;
BA_ "GenMsgDelayTime" BO_ 1098 20;
BA_ "GenMsgCycleTime" BO_ 1098 2000;
BA_ "GenMsgSendType" BO_ 1098 5;
BA_ "GenSigSNA" SG_ 1098 VC_WTS_Prsnt "0h";
BA_ "FlexKomIsMotorola" SG_ 1098 VC_WTS_Prsnt 1;
BA_ "FlexKomComment" SG_ 1098 VC_WTS_Prsnt "Vehicle Configuration 5 Packet";
BA_ "FlexKomSigName" SG_ 1098 VC_WTS_Prsnt "VehCfg5_Pkt";
BA_ "FlexKomSigLaenge" SG_ 1098 VC_WTS_Prsnt 64;
BA_ "FlexKomSigStartPos" SG_ 1098 VC_WTS_Prsnt 7;
BA_ "FlexKomSID" SG_ 1098 VC_WTS_Prsnt 1198;
BA_ "FlexKomSigStartValue" SG_ 1098 VC_WTS_Prsnt "C3FFFFFFFFFFFF00h";
BA_ "GenSigCycleTime" SG_ 1098 VC_WTS_Prsnt 2000;
BA_ "GenSigSendType" SG_ 1098 VC_WTS_Prsnt 5;
BA_ "GenSigSNA" SG_ 1098 VC_VehCfg5_Stat "3h";
BA_ "FlexKomIsMotorola" SG_ 1098 VC_VehCfg5_Stat 1;
BA_ "FlexKomComment" SG_ 1098 VC_VehCfg5_Stat "Vehicle Configuration 5 Packet";
BA_ "FlexKomSigName" SG_ 1098 VC_VehCfg5_Stat "VehCfg5_Pkt";
BA_ "FlexKomSigLaenge" SG_ 1098 VC_VehCfg5_Stat 64;
BA_ "FlexKomSigStartPos" SG_ 1098 VC_VehCfg5_Stat 7;
BA_ "FlexKomSID" SG_ 1098 VC_VehCfg5_Stat 1198;
BA_ "GenSigTimeout_ORC" SG_ 1098 VC_VehCfg5_Stat 7000;
BA_ "GenSigTimeout_EPS" SG_ 1098 VC_VehCfg5_Stat 21000;
BA_ "GenSigTimeout_PTS" SG_ 1098 VC_VehCfg5_Stat 21000;
BA_ "GenSigTimeout_IC" SG_ 1098 VC_VehCfg5_Stat 21000;
BA_ "GenSigStartValue" SG_ 1098 VC_VehCfg5_Stat 3;
BA_ "FlexKomSigStartValue" SG_ 1098 VC_VehCfg5_Stat "C3FFFFFFFFFFFF00h";
BA_ "GenSigCycleTime" SG_ 1098 VC_VehCfg5_Stat 2000;
BA_ "GenSigSendType" SG_ 1098 VC_VehCfg5_Stat 5;
BA_ "GenSigSNA" SG_ 1098 VC_Strng_Rt_pls5 "FFh";
BA_ "FlexKomIsMotorola" SG_ 1098 VC_Strng_Rt_pls5 1;
BA_ "FlexKomComment" SG_ 1098 VC_Strng_Rt_pls5 "Vehicle Configuration 5 Packet";
BA_ "FlexKomSigName" SG_ 1098 VC_Strng_Rt_pls5 "VehCfg5_Pkt";
BA_ "FlexKomSigLaenge" SG_ 1098 VC_Strng_Rt_pls5 64;
BA_ "FlexKomSigStartPos" SG_ 1098 VC_Strng_Rt_pls5 7;
BA_ "FlexKomSID" SG_ 1098 VC_Strng_Rt_pls5 1198;
BA_ "GenSigStartValue" SG_ 1098 VC_Strng_Rt_pls5 255;
BA_ "FlexKomSigStartValue" SG_ 1098 VC_Strng_Rt_pls5 "C3FFFFFFFFFFFF00h";
BA_ "GenSigCycleTime" SG_ 1098 VC_Strng_Rt_pls5 2000;
BA_ "GenSigSendType" SG_ 1098 VC_Strng_Rt_pls5 5;
BA_ "GenSigSNA" SG_ 1098 VC_Strng_Rt_pls4 "FFh";
BA_ "FlexKomIsMotorola" SG_ 1098 VC_Strng_Rt_pls4 1;
BA_ "FlexKomComment" SG_ 1098 VC_Strng_Rt_pls4 "Vehicle Configuration 5 Packet";
BA_ "FlexKomSigName" SG_ 1098 VC_Strng_Rt_pls4 "VehCfg5_Pkt";
BA_ "FlexKomSigLaenge" SG_ 1098 VC_Strng_Rt_pls4 64;
BA_ "FlexKomSigStartPos" SG_ 1098 VC_Strng_Rt_pls4 7;
BA_ "FlexKomSID" SG_ 1098 VC_Strng_Rt_pls4 1198;
BA_ "GenSigStartValue" SG_ 1098 VC_Strng_Rt_pls4 255;
BA_ "FlexKomSigStartValue" SG_ 1098 VC_Strng_Rt_pls4 "C3FFFFFFFFFFFF00h";
BA_ "GenSigCycleTime" SG_ 1098 VC_Strng_Rt_pls4 2000;
BA_ "GenSigSendType" SG_ 1098 VC_Strng_Rt_pls4 5;
BA_ "GenSigSNA" SG_ 1098 VC_Strng_Rt_pls3 "FFh";
BA_ "FlexKomIsMotorola" SG_ 1098 VC_Strng_Rt_pls3 1;
BA_ "FlexKomComment" SG_ 1098 VC_Strng_Rt_pls3 "Vehicle Configuration 5 Packet";
BA_ "FlexKomSigName" SG_ 1098 VC_Strng_Rt_pls3 "VehCfg5_Pkt";
BA_ "FlexKomSigLaenge" SG_ 1098 VC_Strng_Rt_pls3 64;
BA_ "FlexKomSigStartPos" SG_ 1098 VC_Strng_Rt_pls3 7;
BA_ "FlexKomSID" SG_ 1098 VC_Strng_Rt_pls3 1198;
BA_ "GenSigStartValue" SG_ 1098 VC_Strng_Rt_pls3 255;
BA_ "FlexKomSigStartValue" SG_ 1098 VC_Strng_Rt_pls3 "C3FFFFFFFFFFFF00h";
BA_ "GenSigCycleTime" SG_ 1098 VC_Strng_Rt_pls3 2000;
BA_ "GenSigSendType" SG_ 1098 VC_Strng_Rt_pls3 5;
BA_ "GenSigSNA" SG_ 1098 VC_Strng_Rt_pls2 "FFh";
BA_ "FlexKomIsMotorola" SG_ 1098 VC_Strng_Rt_pls2 1;
BA_ "FlexKomComment" SG_ 1098 VC_Strng_Rt_pls2 "Vehicle Configuration 5 Packet";
BA_ "FlexKomSigName" SG_ 1098 VC_Strng_Rt_pls2 "VehCfg5_Pkt";
BA_ "FlexKomSigLaenge" SG_ 1098 VC_Strng_Rt_pls2 64;
BA_ "FlexKomSigStartPos" SG_ 1098 VC_Strng_Rt_pls2 7;
BA_ "FlexKomSID" SG_ 1098 VC_Strng_Rt_pls2 1198;
BA_ "GenSigStartValue" SG_ 1098 VC_Strng_Rt_pls2 255;
BA_ "FlexKomSigStartValue" SG_ 1098 VC_Strng_Rt_pls2 "C3FFFFFFFFFFFF00h";
BA_ "GenSigCycleTime" SG_ 1098 VC_Strng_Rt_pls2 2000;
BA_ "GenSigSendType" SG_ 1098 VC_Strng_Rt_pls2 5;
BA_ "GenSigSNA" SG_ 1098 VC_Strng_Rt_pls1 "FFh";
BA_ "FlexKomIsMotorola" SG_ 1098 VC_Strng_Rt_pls1 1;
BA_ "FlexKomComment" SG_ 1098 VC_Strng_Rt_pls1 "Vehicle Configuration 5 Packet";
BA_ "FlexKomSigName" SG_ 1098 VC_Strng_Rt_pls1 "VehCfg5_Pkt";
BA_ "FlexKomSigLaenge" SG_ 1098 VC_Strng_Rt_pls1 64;
BA_ "FlexKomSigStartPos" SG_ 1098 VC_Strng_Rt_pls1 7;
BA_ "FlexKomSID" SG_ 1098 VC_Strng_Rt_pls1 1198;
BA_ "GenSigStartValue" SG_ 1098 VC_Strng_Rt_pls1 255;
BA_ "FlexKomSigStartValue" SG_ 1098 VC_Strng_Rt_pls1 "C3FFFFFFFFFFFF00h";
BA_ "GenSigCycleTime" SG_ 1098 VC_Strng_Rt_pls1 2000;
BA_ "GenSigSendType" SG_ 1098 VC_Strng_Rt_pls1 5;
BA_ "GenSigSNA" SG_ 1098 VC_Strng_Rt_0 "FFh";
BA_ "FlexKomIsMotorola" SG_ 1098 VC_Strng_Rt_0 1;
BA_ "FlexKomComment" SG_ 1098 VC_Strng_Rt_0 "Vehicle Configuration 5 Packet";
BA_ "FlexKomSigName" SG_ 1098 VC_Strng_Rt_0 "VehCfg5_Pkt";
BA_ "FlexKomSigLaenge" SG_ 1098 VC_Strng_Rt_0 64;
BA_ "FlexKomSigStartPos" SG_ 1098 VC_Strng_Rt_0 7;
BA_ "FlexKomSID" SG_ 1098 VC_Strng_Rt_0 1198;
BA_ "GenSigStartValue" SG_ 1098 VC_Strng_Rt_0 255;
BA_ "FlexKomSigStartValue" SG_ 1098 VC_Strng_Rt_0 "C3FFFFFFFFFFFF00h";
BA_ "GenSigCycleTime" SG_ 1098 VC_Strng_Rt_0 2000;
BA_ "GenSigSendType" SG_ 1098 VC_Strng_Rt_0 5;
BA_ "GenSigSNA" SG_ 1098 VC_SpdLmt_PRSNT "0h";
BA_ "FlexKomIsMotorola" SG_ 1098 VC_SpdLmt_PRSNT 1;
BA_ "FlexKomComment" SG_ 1098 VC_SpdLmt_PRSNT "Vehicle Configuration 5 Packet";
BA_ "FlexKomSigName" SG_ 1098 VC_SpdLmt_PRSNT "VehCfg5_Pkt";
BA_ "FlexKomSigLaenge" SG_ 1098 VC_SpdLmt_PRSNT 64;
BA_ "FlexKomSigStartPos" SG_ 1098 VC_SpdLmt_PRSNT 7;
BA_ "FlexKomSID" SG_ 1098 VC_SpdLmt_PRSNT 1198;
BA_ "GenSigTimeout_ORC" SG_ 1098 VC_SpdLmt_PRSNT 7000;
BA_ "GenSigTimeout_IC" SG_ 1098 VC_SpdLmt_PRSNT 21000;
BA_ "FlexKomSigStartValue" SG_ 1098 VC_SpdLmt_PRSNT "C3FFFFFFFFFFFF00h";
BA_ "GenSigCycleTime" SG_ 1098 VC_SpdLmt_PRSNT 2000;
BA_ "GenSigSendType" SG_ 1098 VC_SpdLmt_PRSNT 5;
BA_ "GenSigSNA" SG_ 1098 VC_SBR_Prsnt "0h";
BA_ "FlexKomIsMotorola" SG_ 1098 VC_SBR_Prsnt 1;
BA_ "FlexKomComment" SG_ 1098 VC_SBR_Prsnt "Vehicle Configuration 5 Packet";
BA_ "FlexKomSigName" SG_ 1098 VC_SBR_Prsnt "VehCfg5_Pkt";
BA_ "FlexKomSigLaenge" SG_ 1098 VC_SBR_Prsnt 64;
BA_ "FlexKomSigStartPos" SG_ 1098 VC_SBR_Prsnt 7;
BA_ "FlexKomSID" SG_ 1098 VC_SBR_Prsnt 1198;
BA_ "GenSigTimeout_ORC" SG_ 1098 VC_SBR_Prsnt 7000;
BA_ "FlexKomSigStartValue" SG_ 1098 VC_SBR_Prsnt "C3FFFFFFFFFFFF00h";
BA_ "GenSigCycleTime" SG_ 1098 VC_SBR_Prsnt 2000;
BA_ "GenSigSendType" SG_ 1098 VC_SBR_Prsnt 5;
BA_ "GenSigSNA" SG_ 1098 VC_RR_DuallyPrsnt "0h";
BA_ "FlexKomIsMotorola" SG_ 1098 VC_RR_DuallyPrsnt 1;
BA_ "FlexKomComment" SG_ 1098 VC_RR_DuallyPrsnt "Vehicle Configuration 5 Packet";
BA_ "FlexKomSigName" SG_ 1098 VC_RR_DuallyPrsnt "VehCfg5_Pkt";
BA_ "FlexKomSigLaenge" SG_ 1098 VC_RR_DuallyPrsnt 64;
BA_ "FlexKomSigStartPos" SG_ 1098 VC_RR_DuallyPrsnt 7;
BA_ "FlexKomSID" SG_ 1098 VC_RR_DuallyPrsnt 1198;
BA_ "GenSigTimeout_IC" SG_ 1098 VC_RR_DuallyPrsnt 21000;
BA_ "FlexKomSigStartValue" SG_ 1098 VC_RR_DuallyPrsnt "C3FFFFFFFFFFFF00h";
BA_ "GenSigCycleTime" SG_ 1098 VC_RR_DuallyPrsnt 2000;
BA_ "GenSigSendType" SG_ 1098 VC_RR_DuallyPrsnt 5;
BA_ "GenSigSNA" SG_ 1098 VC_RearDoorLocks2DCM "0h";
BA_ "FlexKomIsMotorola" SG_ 1098 VC_RearDoorLocks2DCM 1;
BA_ "FlexKomComment" SG_ 1098 VC_RearDoorLocks2DCM "Vehicle Configuration 5 Packet";
BA_ "FlexKomSigName" SG_ 1098 VC_RearDoorLocks2DCM "VehCfg5_Pkt";
BA_ "FlexKomSigLaenge" SG_ 1098 VC_RearDoorLocks2DCM 64;
BA_ "FlexKomSigStartPos" SG_ 1098 VC_RearDoorLocks2DCM 7;
BA_ "FlexKomSID" SG_ 1098 VC_RearDoorLocks2DCM 1198;
BA_ "FlexKomSigStartValue" SG_ 1098 VC_RearDoorLocks2DCM "C3FFFFFFFFFFFF00h";
BA_ "GenSigCycleTime" SG_ 1098 VC_RearDoorLocks2DCM 2000;
BA_ "GenSigSendType" SG_ 1098 VC_RearDoorLocks2DCM 5;
BA_ "GenSigSNA" SG_ 1098 VC_PPPA_Prsnt "0h";
BA_ "FlexKomIsMotorola" SG_ 1098 VC_PPPA_Prsnt 1;
BA_ "FlexKomComment" SG_ 1098 VC_PPPA_Prsnt "Vehicle Configuration 5 Packet";
BA_ "FlexKomSigName" SG_ 1098 VC_PPPA_Prsnt "VehCfg5_Pkt";
BA_ "FlexKomSigLaenge" SG_ 1098 VC_PPPA_Prsnt 64;
BA_ "FlexKomSigStartPos" SG_ 1098 VC_PPPA_Prsnt 7;
BA_ "FlexKomSID" SG_ 1098 VC_PPPA_Prsnt 1198;
BA_ "GenSigTimeout_EPS" SG_ 1098 VC_PPPA_Prsnt 21000;
BA_ "GenSigTimeout_PTS" SG_ 1098 VC_PPPA_Prsnt 21000;
BA_ "GenSigTimeout_IC" SG_ 1098 VC_PPPA_Prsnt 21000;
BA_ "FlexKomSigStartValue" SG_ 1098 VC_PPPA_Prsnt "C3FFFFFFFFFFFF00h";
BA_ "GenSigCycleTime" SG_ 1098 VC_PPPA_Prsnt 2000;
BA_ "GenSigSendType" SG_ 1098 VC_PPPA_Prsnt 5;
BA_ "GenSigSNA" SG_ 1098 VC_ParkStopPrsnt "0h";
BA_ "FlexKomIsMotorola" SG_ 1098 VC_ParkStopPrsnt 1;
BA_ "FlexKomComment" SG_ 1098 VC_ParkStopPrsnt "Vehicle Configuration 5 Packet";
BA_ "FlexKomSigName" SG_ 1098 VC_ParkStopPrsnt "VehCfg5_Pkt";
BA_ "FlexKomSigLaenge" SG_ 1098 VC_ParkStopPrsnt 64;
BA_ "FlexKomSigStartPos" SG_ 1098 VC_ParkStopPrsnt 7;
BA_ "FlexKomSID" SG_ 1098 VC_ParkStopPrsnt 1198;
BA_ "GenSigTimeout_PTS" SG_ 1098 VC_ParkStopPrsnt 21000;
BA_ "FlexKomSigStartValue" SG_ 1098 VC_ParkStopPrsnt "C3FFFFFFFFFFFF00h";
BA_ "GenSigCycleTime" SG_ 1098 VC_ParkStopPrsnt 2000;
BA_ "GenSigSendType" SG_ 1098 VC_ParkStopPrsnt 5;
BA_ "GenSigSNA" SG_ 1098 VC_OffRoadPg "0h";
BA_ "FlexKomIsMotorola" SG_ 1098 VC_OffRoadPg 1;
BA_ "FlexKomComment" SG_ 1098 VC_OffRoadPg "Vehicle Configuration 5 Packet";
BA_ "FlexKomSigName" SG_ 1098 VC_OffRoadPg "VehCfg5_Pkt";
BA_ "FlexKomSigLaenge" SG_ 1098 VC_OffRoadPg 64;
BA_ "FlexKomSigStartPos" SG_ 1098 VC_OffRoadPg 7;
BA_ "FlexKomSID" SG_ 1098 VC_OffRoadPg 1198;
BA_ "GenSigTimeout_IC" SG_ 1098 VC_OffRoadPg 21000;
BA_ "FlexKomSigStartValue" SG_ 1098 VC_OffRoadPg "C3FFFFFFFFFFFF00h";
BA_ "GenSigCycleTime" SG_ 1098 VC_OffRoadPg 2000;
BA_ "GenSigSendType" SG_ 1098 VC_OffRoadPg 5;
BA_ "GenSigSNA" SG_ 1098 VC_NonReg_TPIS "0h";
BA_ "FlexKomIsMotorola" SG_ 1098 VC_NonReg_TPIS 1;
BA_ "FlexKomComment" SG_ 1098 VC_NonReg_TPIS "Vehicle Configuration 5 Packet";
BA_ "FlexKomSigName" SG_ 1098 VC_NonReg_TPIS "VehCfg5_Pkt";
BA_ "FlexKomSigLaenge" SG_ 1098 VC_NonReg_TPIS 64;
BA_ "FlexKomSigStartPos" SG_ 1098 VC_NonReg_TPIS 7;
BA_ "FlexKomSID" SG_ 1098 VC_NonReg_TPIS 1198;
BA_ "GenSigTimeout_IC" SG_ 1098 VC_NonReg_TPIS 21000;
BA_ "FlexKomSigStartValue" SG_ 1098 VC_NonReg_TPIS "C3FFFFFFFFFFFF00h";
BA_ "GenSigCycleTime" SG_ 1098 VC_NonReg_TPIS 2000;
BA_ "GenSigSendType" SG_ 1098 VC_NonReg_TPIS 5;
BA_ "GenSigSNA" SG_ 1098 VC_LUCI_PRSNT "0h";
BA_ "FlexKomIsMotorola" SG_ 1098 VC_LUCI_PRSNT 1;
BA_ "FlexKomComment" SG_ 1098 VC_LUCI_PRSNT "Vehicle Configuration 5 Packet";
BA_ "FlexKomSigName" SG_ 1098 VC_LUCI_PRSNT "VehCfg5_Pkt";
BA_ "FlexKomSigLaenge" SG_ 1098 VC_LUCI_PRSNT 64;
BA_ "FlexKomSigStartPos" SG_ 1098 VC_LUCI_PRSNT 7;
BA_ "FlexKomSID" SG_ 1098 VC_LUCI_PRSNT 1198;
BA_ "FlexKomSigStartValue" SG_ 1098 VC_LUCI_PRSNT "C3FFFFFFFFFFFF00h";
BA_ "GenSigCycleTime" SG_ 1098 VC_LUCI_PRSNT 2000;
BA_ "GenSigSendType" SG_ 1098 VC_LUCI_PRSNT 5;
BA_ "GenSigSNA" SG_ 1098 VC_ChildDisp_Prsnt "0h";
BA_ "FlexKomIsMotorola" SG_ 1098 VC_ChildDisp_Prsnt 1;
BA_ "FlexKomComment" SG_ 1098 VC_ChildDisp_Prsnt "Vehicle Configuration 5 Packet";
BA_ "FlexKomSigName" SG_ 1098 VC_ChildDisp_Prsnt "VehCfg5_Pkt";
BA_ "FlexKomSigLaenge" SG_ 1098 VC_ChildDisp_Prsnt 64;
BA_ "FlexKomSigStartPos" SG_ 1098 VC_ChildDisp_Prsnt 7;
BA_ "FlexKomSID" SG_ 1098 VC_ChildDisp_Prsnt 1198;
BA_ "GenSigTimeout_ORC" SG_ 1098 VC_ChildDisp_Prsnt 7000;
BA_ "FlexKomSigStartValue" SG_ 1098 VC_ChildDisp_Prsnt "C3FFFFFFFFFFFF00h";
BA_ "GenSigCycleTime" SG_ 1098 VC_ChildDisp_Prsnt 2000;
BA_ "GenSigSendType" SG_ 1098 VC_ChildDisp_Prsnt 5;
BA_ "GenSigSNA" SG_ 1098 VC_AmbTempLct "3h";
BA_ "FlexKomIsMotorola" SG_ 1098 VC_AmbTempLct 1;
BA_ "FlexKomComment" SG_ 1098 VC_AmbTempLct "Vehicle Configuration 5 Packet";
BA_ "FlexKomSigName" SG_ 1098 VC_AmbTempLct "VehCfg5_Pkt";
BA_ "FlexKomSigLaenge" SG_ 1098 VC_AmbTempLct 64;
BA_ "FlexKomSigStartPos" SG_ 1098 VC_AmbTempLct 7;
BA_ "FlexKomSID" SG_ 1098 VC_AmbTempLct 1198;
BA_ "GenSigStartValue" SG_ 1098 VC_AmbTempLct 3;
BA_ "FlexKomSigStartValue" SG_ 1098 VC_AmbTempLct "C3FFFFFFFFFFFF00h";
BA_ "GenSigCycleTime" SG_ 1098 VC_AmbTempLct 2000;
BA_ "GenSigSendType" SG_ 1098 VC_AmbTempLct 5;
BA_ "GenSigSNA" SG_ 1098 VC_AmbLtgPrsnt "0h";
BA_ "FlexKomIsMotorola" SG_ 1098 VC_AmbLtgPrsnt 1;
BA_ "FlexKomComment" SG_ 1098 VC_AmbLtgPrsnt "Vehicle Configuration 5 Packet";
BA_ "FlexKomSigName" SG_ 1098 VC_AmbLtgPrsnt "VehCfg5_Pkt";
BA_ "FlexKomSigLaenge" SG_ 1098 VC_AmbLtgPrsnt 64;
BA_ "FlexKomSigStartPos" SG_ 1098 VC_AmbLtgPrsnt 7;
BA_ "FlexKomSID" SG_ 1098 VC_AmbLtgPrsnt 1198;
BA_ "GenSigTimeout_IC" SG_ 1098 VC_AmbLtgPrsnt 21000;
BA_ "FlexKomSigStartValue" SG_ 1098 VC_AmbLtgPrsnt "C3FFFFFFFFFFFF00h";
BA_ "GenSigCycleTime" SG_ 1098 VC_AmbLtgPrsnt 2000;
BA_ "GenSigSendType" SG_ 1098 VC_AmbLtgPrsnt 5;
BA_ "GenMsgStartValue" BO_ 1059 "FFFFFFFF000000FFh";
BA_ "GenMsgNrOfRepetitions" BO_ 1059 2;
BA_ "GenMsgDelayTime" BO_ 1059 20;
BA_ "NWM-Botschaft" BO_ 1059 1;
BA_ "GenSigSNA" SG_ 1059 WakeupRsn_SCCM "FFh";
BA_ "FlexKomIsMotorola" SG_ 1059 WakeupRsn_SCCM 1;
BA_ "FlexKomComment" SG_ 1059 WakeupRsn_SCCM "Mode 2 of NM_Ud_Srv";
BA_ "FlexKomSigName" SG_ 1059 WakeupRsn_SCCM "Wakeup_SCCM_Pkt";
BA_ "FlexKomSigLaenge" SG_ 1059 WakeupRsn_SCCM 24;
BA_ "FlexKomSigStartPos" SG_ 1059 WakeupRsn_SCCM 39;
BA_ "FlexKomSID" SG_ 1059 WakeupRsn_SCCM 494;
BA_ "GenSigStartValue" SG_ 1059 WakeupRsn_SCCM 255;
BA_ "FlexKomSigStartValue" SG_ 1059 WakeupRsn_SCCM "FFFF00h";
BA_ "GenSigSNA" SG_ 1059 WakeupCnt_SCCM "FFh";
BA_ "FlexKomIsMotorola" SG_ 1059 WakeupCnt_SCCM 1;
BA_ "FlexKomComment" SG_ 1059 WakeupCnt_SCCM "Mode 2 of NM_Ud_Srv";
BA_ "FlexKomSigName" SG_ 1059 WakeupCnt_SCCM "Wakeup_SCCM_Pkt";
BA_ "FlexKomSigLaenge" SG_ 1059 WakeupCnt_SCCM 24;
BA_ "FlexKomSigStartPos" SG_ 1059 WakeupCnt_SCCM 39;
BA_ "FlexKomSID" SG_ 1059 WakeupCnt_SCCM 494;
BA_ "GenSigStartValue" SG_ 1059 WakeupCnt_SCCM 255;
BA_ "FlexKomSigStartValue" SG_ 1059 WakeupCnt_SCCM "FFFF00h";
BA_ "GenSigSNA" SG_ 1059 Nw_Id_SCCM "FFh";
BA_ "FlexKomIsMotorola" SG_ 1059 Nw_Id_SCCM 1;
BA_ "FlexKomComment" SG_ 1059 Nw_Id_SCCM "Network identification no.";
BA_ "FlexKomSigName" SG_ 1059 Nw_Id_SCCM "Nw_Id";
BA_ "FlexKomSigLaenge" SG_ 1059 Nw_Id_SCCM 8;
BA_ "FlexKomSigStartPos" SG_ 1059 Nw_Id_SCCM 63;
BA_ "FlexKomSID" SG_ 1059 Nw_Id_SCCM 535;
BA_ "GenSigStartValue" SG_ 1059 Nw_Id_SCCM 255;
BA_ "FlexKomSigStartValue" SG_ 1059 Nw_Id_SCCM "FFh";
BA_ "GenSigSNA" SG_ 1059 NM_Ud_Srv_SCCM "FFh";
BA_ "FlexKomIsMotorola" SG_ 1059 NM_Ud_Srv_SCCM 1;
BA_ "FlexKomComment" SG_ 1059 NM_Ud_Srv_SCCM "Network management state";
BA_ "FlexKomSigName" SG_ 1059 NM_Ud_Srv_SCCM "NM";
BA_ "FlexKomSigLaenge" SG_ 1059 NM_Ud_Srv_SCCM 32;
BA_ "FlexKomSigStartPos" SG_ 1059 NM_Ud_Srv_SCCM 7;
BA_ "FlexKomSID" SG_ 1059 NM_Ud_Srv_SCCM 472;
BA_ "GenSigStartValue" SG_ 1059 NM_Ud_Srv_SCCM 255;
BA_ "FlexKomSigStartValue" SG_ 1059 NM_Ud_Srv_SCCM "FFFFFFFFh";
BA_ "GenSigSNA" SG_ 1059 NM_Ud_Launch_SCCM "3Fh";
BA_ "FlexKomIsMotorola" SG_ 1059 NM_Ud_Launch_SCCM 1;
BA_ "FlexKomComment" SG_ 1059 NM_Ud_Launch_SCCM "Network management state";
BA_ "FlexKomSigName" SG_ 1059 NM_Ud_Launch_SCCM "NM";
BA_ "FlexKomSigLaenge" SG_ 1059 NM_Ud_Launch_SCCM 32;
BA_ "FlexKomSigStartPos" SG_ 1059 NM_Ud_Launch_SCCM 7;
BA_ "FlexKomSID" SG_ 1059 NM_Ud_Launch_SCCM 472;
BA_ "GenSigStartValue" SG_ 1059 NM_Ud_Launch_SCCM 63;
BA_ "FlexKomSigStartValue" SG_ 1059 NM_Ud_Launch_SCCM "FFFFFFFFh";
BA_ "GenSigSNA" SG_ 1059 NM_Successor_SCCM "FFh";
BA_ "FlexKomIsMotorola" SG_ 1059 NM_Successor_SCCM 1;
BA_ "FlexKomComment" SG_ 1059 NM_Successor_SCCM "Network management state";
BA_ "FlexKomSigName" SG_ 1059 NM_Successor_SCCM "NM";
BA_ "FlexKomSigLaenge" SG_ 1059 NM_Successor_SCCM 32;
BA_ "FlexKomSigStartPos" SG_ 1059 NM_Successor_SCCM 7;
BA_ "FlexKomSID" SG_ 1059 NM_Successor_SCCM 472;
BA_ "GenSigStartValue" SG_ 1059 NM_Successor_SCCM 255;
BA_ "FlexKomSigStartValue" SG_ 1059 NM_Successor_SCCM "FFFFFFFFh";
BA_ "GenSigSNA" SG_ 1059 NM_Sleep_Ind_SCCM "1h";
BA_ "FlexKomIsMotorola" SG_ 1059 NM_Sleep_Ind_SCCM 1;
BA_ "FlexKomComment" SG_ 1059 NM_Sleep_Ind_SCCM "Network management state";
BA_ "FlexKomSigName" SG_ 1059 NM_Sleep_Ind_SCCM "NM";
BA_ "FlexKomSigLaenge" SG_ 1059 NM_Sleep_Ind_SCCM 32;
BA_ "FlexKomSigStartPos" SG_ 1059 NM_Sleep_Ind_SCCM 7;
BA_ "FlexKomSID" SG_ 1059 NM_Sleep_Ind_SCCM 472;
BA_ "GenSigStartValue" SG_ 1059 NM_Sleep_Ind_SCCM 1;
BA_ "FlexKomSigStartValue" SG_ 1059 NM_Sleep_Ind_SCCM "FFFFFFFFh";
BA_ "GenSigSNA" SG_ 1059 NM_Sleep_Ack_SCCM "1h";
BA_ "FlexKomIsMotorola" SG_ 1059 NM_Sleep_Ack_SCCM 1;
BA_ "FlexKomComment" SG_ 1059 NM_Sleep_Ack_SCCM "Network management state";
BA_ "FlexKomSigName" SG_ 1059 NM_Sleep_Ack_SCCM "NM";
BA_ "FlexKomSigLaenge" SG_ 1059 NM_Sleep_Ack_SCCM 32;
BA_ "FlexKomSigStartPos" SG_ 1059 NM_Sleep_Ack_SCCM 7;
BA_ "FlexKomSID" SG_ 1059 NM_Sleep_Ack_SCCM 472;
BA_ "GenSigStartValue" SG_ 1059 NM_Sleep_Ack_SCCM 1;
BA_ "FlexKomSigStartValue" SG_ 1059 NM_Sleep_Ack_SCCM "FFFFFFFFh";
BA_ "GenSigSNA" SG_ 1059 NM_Mode_SCCM "FFh";
BA_ "FlexKomIsMotorola" SG_ 1059 NM_Mode_SCCM 1;
BA_ "FlexKomComment" SG_ 1059 NM_Mode_SCCM "Network management state";
BA_ "FlexKomSigName" SG_ 1059 NM_Mode_SCCM "NM";
BA_ "FlexKomSigLaenge" SG_ 1059 NM_Mode_SCCM 32;
BA_ "FlexKomSigStartPos" SG_ 1059 NM_Mode_SCCM 7;
BA_ "FlexKomSID" SG_ 1059 NM_Mode_SCCM 472;
BA_ "GenSigStartValue" SG_ 1059 NM_Mode_SCCM 255;
BA_ "FlexKomSigStartValue" SG_ 1059 NM_Mode_SCCM "FFFFFFFFh";
BA_ "GenSigSNA" SG_ 1059 Awake_tilt_tel_Psd_SCCM "0h";
BA_ "FlexKomIsMotorola" SG_ 1059 Awake_tilt_tel_Psd_SCCM 1;
BA_ "FlexKomComment" SG_ 1059 Awake_tilt_tel_Psd_SCCM "Mode 15 of NM_Ud_Srv";
BA_ "FlexKomSigName" SG_ 1059 Awake_tilt_tel_Psd_SCCM "Awake_SCCM_Pkt";
BA_ "FlexKomSigLaenge" SG_ 1059 Awake_tilt_tel_Psd_SCCM 24;
BA_ "FlexKomSigStartPos" SG_ 1059 Awake_tilt_tel_Psd_SCCM 39;
BA_ "FlexKomSID" SG_ 1059 Awake_tilt_tel_Psd_SCCM 524;
BA_ "FlexKomSigStartValue" SG_ 1059 Awake_tilt_tel_Psd_SCCM "000000h";
BA_ "GenSigSNA" SG_ 1059 Awake_StwSw_Actv_SCCM "0h";
BA_ "FlexKomIsMotorola" SG_ 1059 Awake_StwSw_Actv_SCCM 1;
BA_ "FlexKomComment" SG_ 1059 Awake_StwSw_Actv_SCCM "Mode 15 of NM_Ud_Srv";
BA_ "FlexKomSigName" SG_ 1059 Awake_StwSw_Actv_SCCM "Awake_SCCM_Pkt";
BA_ "FlexKomSigLaenge" SG_ 1059 Awake_StwSw_Actv_SCCM 24;
BA_ "FlexKomSigStartPos" SG_ 1059 Awake_StwSw_Actv_SCCM 39;
BA_ "FlexKomSID" SG_ 1059 Awake_StwSw_Actv_SCCM 524;
BA_ "FlexKomSigStartValue" SG_ 1059 Awake_StwSw_Actv_SCCM "000000h";
BA_ "GenSigSNA" SG_ 1059 Awake_NwSt_SCCM "0h";
BA_ "FlexKomIsMotorola" SG_ 1059 Awake_NwSt_SCCM 1;
BA_ "FlexKomComment" SG_ 1059 Awake_NwSt_SCCM "Mode 15 of NM_Ud_Srv";
BA_ "FlexKomSigName" SG_ 1059 Awake_NwSt_SCCM "Awake_SCCM_Pkt";
BA_ "FlexKomSigLaenge" SG_ 1059 Awake_NwSt_SCCM 24;
BA_ "FlexKomSigStartPos" SG_ 1059 Awake_NwSt_SCCM 39;
BA_ "FlexKomSID" SG_ 1059 Awake_NwSt_SCCM 524;
BA_ "FlexKomSigStartValue" SG_ 1059 Awake_NwSt_SCCM "000000h";
BA_ "GenSigSNA" SG_ 1059 Awake_Ignition_On_SCCM "0h";
BA_ "FlexKomIsMotorola" SG_ 1059 Awake_Ignition_On_SCCM 1;
BA_ "FlexKomComment" SG_ 1059 Awake_Ignition_On_SCCM "Mode 15 of NM_Ud_Srv";
BA_ "FlexKomSigName" SG_ 1059 Awake_Ignition_On_SCCM "Awake_SCCM_Pkt";
BA_ "FlexKomSigLaenge" SG_ 1059 Awake_Ignition_On_SCCM 24;
BA_ "FlexKomSigStartPos" SG_ 1059 Awake_Ignition_On_SCCM 39;
BA_ "FlexKomSID" SG_ 1059 Awake_Ignition_On_SCCM 524;
BA_ "FlexKomSigStartValue" SG_ 1059 Awake_Ignition_On_SCCM "000000h";
BA_ "GenSigSNA" SG_ 1059 Awake_HrnSwt_Actv_SCCM "0h";
BA_ "FlexKomIsMotorola" SG_ 1059 Awake_HrnSwt_Actv_SCCM 1;
BA_ "FlexKomComment" SG_ 1059 Awake_HrnSwt_Actv_SCCM "Mode 15 of NM_Ud_Srv";
BA_ "FlexKomSigName" SG_ 1059 Awake_HrnSwt_Actv_SCCM "Awake_SCCM_Pkt";
BA_ "FlexKomSigLaenge" SG_ 1059 Awake_HrnSwt_Actv_SCCM 24;
BA_ "FlexKomSigStartPos" SG_ 1059 Awake_HrnSwt_Actv_SCCM 39;
BA_ "FlexKomSID" SG_ 1059 Awake_HrnSwt_Actv_SCCM 524;
BA_ "FlexKomSigStartValue" SG_ 1059 Awake_HrnSwt_Actv_SCCM "000000h";
BA_ "GenSigSNA" SG_ 1059 Awake_FTP_Psd_SCCM "0h";
BA_ "FlexKomIsMotorola" SG_ 1059 Awake_FTP_Psd_SCCM 1;
BA_ "FlexKomComment" SG_ 1059 Awake_FTP_Psd_SCCM "Mode 15 of NM_Ud_Srv";
BA_ "FlexKomSigName" SG_ 1059 Awake_FTP_Psd_SCCM "Awake_SCCM_Pkt";
BA_ "FlexKomSigLaenge" SG_ 1059 Awake_FTP_Psd_SCCM 24;
BA_ "FlexKomSigStartPos" SG_ 1059 Awake_FTP_Psd_SCCM 39;
BA_ "FlexKomSID" SG_ 1059 Awake_FTP_Psd_SCCM 524;
BA_ "FlexKomSigStartValue" SG_ 1059 Awake_FTP_Psd_SCCM "000000h";
BA_ "GenSigSNA" SG_ 1059 Awake_EEPROM_SCCM "0h";
BA_ "FlexKomIsMotorola" SG_ 1059 Awake_EEPROM_SCCM 1;
BA_ "FlexKomComment" SG_ 1059 Awake_EEPROM_SCCM "Mode 15 of NM_Ud_Srv";
BA_ "FlexKomSigName" SG_ 1059 Awake_EEPROM_SCCM "Awake_SCCM_Pkt";
BA_ "FlexKomSigLaenge" SG_ 1059 Awake_EEPROM_SCCM 24;
BA_ "FlexKomSigStartPos" SG_ 1059 Awake_EEPROM_SCCM 39;
BA_ "FlexKomSID" SG_ 1059 Awake_EEPROM_SCCM 524;
BA_ "FlexKomSigStartValue" SG_ 1059 Awake_EEPROM_SCCM "000000h";
BA_ "GenSigSNA" SG_ 1059 Awake_Diag_Actv_SCCM "0h";
BA_ "FlexKomIsMotorola" SG_ 1059 Awake_Diag_Actv_SCCM 1;
BA_ "FlexKomComment" SG_ 1059 Awake_Diag_Actv_SCCM "Mode 15 of NM_Ud_Srv";
BA_ "FlexKomSigName" SG_ 1059 Awake_Diag_Actv_SCCM "Awake_SCCM_Pkt";
BA_ "FlexKomSigLaenge" SG_ 1059 Awake_Diag_Actv_SCCM 24;
BA_ "FlexKomSigStartPos" SG_ 1059 Awake_Diag_Actv_SCCM 39;
BA_ "FlexKomSID" SG_ 1059 Awake_Diag_Actv_SCCM 524;
BA_ "FlexKomSigStartValue" SG_ 1059 Awake_Diag_Actv_SCCM "000000h";
BA_ "GenMsgStartValue" BO_ 1050 "FFFFFFFF000000FFh";
BA_ "GenMsgNrOfRepetitions" BO_ 1050 2;
BA_ "GenMsgDelayTime" BO_ 1050 20;
BA_ "NWM-Botschaft" BO_ 1050 1;
BA_ "GenSigSNA" SG_ 1050 WakeupRsn_EPS "FFh";
BA_ "FlexKomIsMotorola" SG_ 1050 WakeupRsn_EPS 1;
BA_ "FlexKomComment" SG_ 1050 WakeupRsn_EPS "Mode 2 of NM_Ud_Srv";
BA_ "FlexKomSigName" SG_ 1050 WakeupRsn_EPS "Wakeup_EPS";
BA_ "FlexKomSigLaenge" SG_ 1050 WakeupRsn_EPS 24;
BA_ "FlexKomSigStartPos" SG_ 1050 WakeupRsn_EPS 39;
BA_ "FlexKomSID" SG_ 1050 WakeupRsn_EPS 1273;
BA_ "GenSigStartValue" SG_ 1050 WakeupRsn_EPS 255;
BA_ "FlexKomSigStartValue" SG_ 1050 WakeupRsn_EPS "FFFF00h";
BA_ "GenSigSNA" SG_ 1050 WakeupCnt_EPS "FFh";
BA_ "FlexKomIsMotorola" SG_ 1050 WakeupCnt_EPS 1;
BA_ "FlexKomComment" SG_ 1050 WakeupCnt_EPS "Mode 2 of NM_Ud_Srv";
BA_ "FlexKomSigName" SG_ 1050 WakeupCnt_EPS "Wakeup_EPS";
BA_ "FlexKomSigLaenge" SG_ 1050 WakeupCnt_EPS 24;
BA_ "FlexKomSigStartPos" SG_ 1050 WakeupCnt_EPS 39;
BA_ "FlexKomSID" SG_ 1050 WakeupCnt_EPS 1273;
BA_ "GenSigStartValue" SG_ 1050 WakeupCnt_EPS 255;
BA_ "FlexKomSigStartValue" SG_ 1050 WakeupCnt_EPS "FFFF00h";
BA_ "GenSigSNA" SG_ 1050 Nw_Id_EPS "FFh";
BA_ "FlexKomIsMotorola" SG_ 1050 Nw_Id_EPS 1;
BA_ "FlexKomComment" SG_ 1050 Nw_Id_EPS "Network identification no.";
BA_ "FlexKomSigName" SG_ 1050 Nw_Id_EPS "Nw_Id";
BA_ "FlexKomSigLaenge" SG_ 1050 Nw_Id_EPS 8;
BA_ "FlexKomSigStartPos" SG_ 1050 Nw_Id_EPS 63;
BA_ "FlexKomSID" SG_ 1050 Nw_Id_EPS 535;
BA_ "GenSigStartValue" SG_ 1050 Nw_Id_EPS 255;
BA_ "FlexKomSigStartValue" SG_ 1050 Nw_Id_EPS "FFh";
BA_ "GenSigSNA" SG_ 1050 NM_Ud_Srv_EPS "FFh";
BA_ "FlexKomIsMotorola" SG_ 1050 NM_Ud_Srv_EPS 1;
BA_ "FlexKomComment" SG_ 1050 NM_Ud_Srv_EPS "Network management state";
BA_ "FlexKomSigName" SG_ 1050 NM_Ud_Srv_EPS "NM";
BA_ "FlexKomSigLaenge" SG_ 1050 NM_Ud_Srv_EPS 32;
BA_ "FlexKomSigStartPos" SG_ 1050 NM_Ud_Srv_EPS 7;
BA_ "FlexKomSID" SG_ 1050 NM_Ud_Srv_EPS 472;
BA_ "GenSigStartValue" SG_ 1050 NM_Ud_Srv_EPS 255;
BA_ "FlexKomSigStartValue" SG_ 1050 NM_Ud_Srv_EPS "FFFFFFFFh";
BA_ "GenSigSNA" SG_ 1050 NM_Ud_Launch_EPS "3Fh";
BA_ "FlexKomIsMotorola" SG_ 1050 NM_Ud_Launch_EPS 1;
BA_ "FlexKomComment" SG_ 1050 NM_Ud_Launch_EPS "Network management state";
BA_ "FlexKomSigName" SG_ 1050 NM_Ud_Launch_EPS "NM";
BA_ "FlexKomSigLaenge" SG_ 1050 NM_Ud_Launch_EPS 32;
BA_ "FlexKomSigStartPos" SG_ 1050 NM_Ud_Launch_EPS 7;
BA_ "FlexKomSID" SG_ 1050 NM_Ud_Launch_EPS 472;
BA_ "GenSigStartValue" SG_ 1050 NM_Ud_Launch_EPS 63;
BA_ "FlexKomSigStartValue" SG_ 1050 NM_Ud_Launch_EPS "FFFFFFFFh";
BA_ "GenSigSNA" SG_ 1050 NM_Successor_EPS "FFh";
BA_ "FlexKomIsMotorola" SG_ 1050 NM_Successor_EPS 1;
BA_ "FlexKomComment" SG_ 1050 NM_Successor_EPS "Network management state";
BA_ "FlexKomSigName" SG_ 1050 NM_Successor_EPS "NM";
BA_ "FlexKomSigLaenge" SG_ 1050 NM_Successor_EPS 32;
BA_ "FlexKomSigStartPos" SG_ 1050 NM_Successor_EPS 7;
BA_ "FlexKomSID" SG_ 1050 NM_Successor_EPS 472;
BA_ "GenSigStartValue" SG_ 1050 NM_Successor_EPS 255;
BA_ "FlexKomSigStartValue" SG_ 1050 NM_Successor_EPS "FFFFFFFFh";
BA_ "GenSigSNA" SG_ 1050 NM_Sleep_Ind_EPS "1h";
BA_ "FlexKomIsMotorola" SG_ 1050 NM_Sleep_Ind_EPS 1;
BA_ "FlexKomComment" SG_ 1050 NM_Sleep_Ind_EPS "Network management state";
BA_ "FlexKomSigName" SG_ 1050 NM_Sleep_Ind_EPS "NM";
BA_ "FlexKomSigLaenge" SG_ 1050 NM_Sleep_Ind_EPS 32;
BA_ "FlexKomSigStartPos" SG_ 1050 NM_Sleep_Ind_EPS 7;
BA_ "FlexKomSID" SG_ 1050 NM_Sleep_Ind_EPS 472;
BA_ "GenSigStartValue" SG_ 1050 NM_Sleep_Ind_EPS 1;
BA_ "FlexKomSigStartValue" SG_ 1050 NM_Sleep_Ind_EPS "FFFFFFFFh";
BA_ "GenSigSNA" SG_ 1050 NM_Sleep_Ack_EPS "1h";
BA_ "FlexKomIsMotorola" SG_ 1050 NM_Sleep_Ack_EPS 1;
BA_ "FlexKomComment" SG_ 1050 NM_Sleep_Ack_EPS "Network management state";
BA_ "FlexKomSigName" SG_ 1050 NM_Sleep_Ack_EPS "NM";
BA_ "FlexKomSigLaenge" SG_ 1050 NM_Sleep_Ack_EPS 32;
BA_ "FlexKomSigStartPos" SG_ 1050 NM_Sleep_Ack_EPS 7;
BA_ "FlexKomSID" SG_ 1050 NM_Sleep_Ack_EPS 472;
BA_ "GenSigStartValue" SG_ 1050 NM_Sleep_Ack_EPS 1;
BA_ "FlexKomSigStartValue" SG_ 1050 NM_Sleep_Ack_EPS "FFFFFFFFh";
BA_ "GenSigSNA" SG_ 1050 NM_Mode_EPS "FFh";
BA_ "FlexKomIsMotorola" SG_ 1050 NM_Mode_EPS 1;
BA_ "FlexKomComment" SG_ 1050 NM_Mode_EPS "Network management state";
BA_ "FlexKomSigName" SG_ 1050 NM_Mode_EPS "NM";
BA_ "FlexKomSigLaenge" SG_ 1050 NM_Mode_EPS 32;
BA_ "FlexKomSigStartPos" SG_ 1050 NM_Mode_EPS 7;
BA_ "FlexKomSID" SG_ 1050 NM_Mode_EPS 472;
BA_ "GenSigStartValue" SG_ 1050 NM_Mode_EPS 255;
BA_ "FlexKomSigStartValue" SG_ 1050 NM_Mode_EPS "FFFFFFFFh";
BA_ "GenSigSNA" SG_ 1050 Awake_VSS_high_EPS "0h";
BA_ "FlexKomIsMotorola" SG_ 1050 Awake_VSS_high_EPS 1;
BA_ "FlexKomComment" SG_ 1050 Awake_VSS_high_EPS "Mode 15 of NM_Ud_Srv";
BA_ "FlexKomSigName" SG_ 1050 Awake_VSS_high_EPS "Awake_EPS";
BA_ "FlexKomSigLaenge" SG_ 1050 Awake_VSS_high_EPS 24;
BA_ "FlexKomSigStartPos" SG_ 1050 Awake_VSS_high_EPS 39;
BA_ "FlexKomSID" SG_ 1050 Awake_VSS_high_EPS 1274;
BA_ "FlexKomSigStartValue" SG_ 1050 Awake_VSS_high_EPS "000000h";
BA_ "GenSigSNA" SG_ 1050 Awake_Rampout_EPS "0h";
BA_ "FlexKomIsMotorola" SG_ 1050 Awake_Rampout_EPS 1;
BA_ "FlexKomComment" SG_ 1050 Awake_Rampout_EPS "Mode 15 of NM_Ud_Srv";
BA_ "FlexKomSigName" SG_ 1050 Awake_Rampout_EPS "Awake_EPS";
BA_ "FlexKomSigLaenge" SG_ 1050 Awake_Rampout_EPS 24;
BA_ "FlexKomSigStartPos" SG_ 1050 Awake_Rampout_EPS 39;
BA_ "FlexKomSID" SG_ 1050 Awake_Rampout_EPS 1274;
BA_ "FlexKomSigStartValue" SG_ 1050 Awake_Rampout_EPS "000000h";
BA_ "GenSigSNA" SG_ 1050 Awake_NwSt_EPS "0h";
BA_ "FlexKomIsMotorola" SG_ 1050 Awake_NwSt_EPS 1;
BA_ "FlexKomComment" SG_ 1050 Awake_NwSt_EPS "Mode 15 of NM_Ud_Srv";
BA_ "FlexKomSigName" SG_ 1050 Awake_NwSt_EPS "Awake_EPS";
BA_ "FlexKomSigLaenge" SG_ 1050 Awake_NwSt_EPS 24;
BA_ "FlexKomSigStartPos" SG_ 1050 Awake_NwSt_EPS 39;
BA_ "FlexKomSID" SG_ 1050 Awake_NwSt_EPS 1274;
BA_ "FlexKomSigStartValue" SG_ 1050 Awake_NwSt_EPS "000000h";
BA_ "GenSigSNA" SG_ 1050 Awake_IgnHigh_EPS "0h";
BA_ "FlexKomIsMotorola" SG_ 1050 Awake_IgnHigh_EPS 1;
BA_ "FlexKomComment" SG_ 1050 Awake_IgnHigh_EPS "Mode 15 of NM_Ud_Srv";
BA_ "FlexKomSigName" SG_ 1050 Awake_IgnHigh_EPS "Awake_EPS";
BA_ "FlexKomSigLaenge" SG_ 1050 Awake_IgnHigh_EPS 24;
BA_ "FlexKomSigStartPos" SG_ 1050 Awake_IgnHigh_EPS 39;
BA_ "FlexKomSID" SG_ 1050 Awake_IgnHigh_EPS 1274;
BA_ "FlexKomSigStartValue" SG_ 1050 Awake_IgnHigh_EPS "000000h";
BA_ "GenSigSNA" SG_ 1050 Awake_EngRPM_high_EPS "0h";
BA_ "FlexKomIsMotorola" SG_ 1050 Awake_EngRPM_high_EPS 1;
BA_ "FlexKomComment" SG_ 1050 Awake_EngRPM_high_EPS "Mode 15 of NM_Ud_Srv";
BA_ "FlexKomSigName" SG_ 1050 Awake_EngRPM_high_EPS "Awake_EPS";
BA_ "FlexKomSigLaenge" SG_ 1050 Awake_EngRPM_high_EPS 24;
BA_ "FlexKomSigStartPos" SG_ 1050 Awake_EngRPM_high_EPS 39;
BA_ "FlexKomSID" SG_ 1050 Awake_EngRPM_high_EPS 1274;
BA_ "FlexKomSigStartValue" SG_ 1050 Awake_EngRPM_high_EPS "000000h";
BA_ "GenSigSNA" SG_ 1050 Awake_Diag_Actv_EPS "0h";
BA_ "FlexKomIsMotorola" SG_ 1050 Awake_Diag_Actv_EPS 1;
BA_ "FlexKomComment" SG_ 1050 Awake_Diag_Actv_EPS "Mode 15 of NM_Ud_Srv";
BA_ "FlexKomSigName" SG_ 1050 Awake_Diag_Actv_EPS "Awake_EPS";
BA_ "FlexKomSigLaenge" SG_ 1050 Awake_Diag_Actv_EPS 24;
BA_ "FlexKomSigStartPos" SG_ 1050 Awake_Diag_Actv_EPS 39;
BA_ "FlexKomSID" SG_ 1050 Awake_Diag_Actv_EPS 1274;
BA_ "FlexKomSigStartValue" SG_ 1050 Awake_Diag_Actv_EPS "000000h";
BA_ "GenMsgStartValue" BO_ 1033 "FFFFFFFF000000FFh";
BA_ "GenMsgNrOfRepetitions" BO_ 1033 2;
BA_ "GenMsgDelayTime" BO_ 1033 20;
BA_ "NWM-Botschaft" BO_ 1033 1;
BA_ "GenSigSNA" SG_ 1033 WakeupRsn_SBWM "FFh";
BA_ "FlexKomIsMotorola" SG_ 1033 WakeupRsn_SBWM 1;
BA_ "FlexKomComment" SG_ 1033 WakeupRsn_SBWM "Mode 2 of NM_Ud_Srv";
BA_ "FlexKomSigName" SG_ 1033 WakeupRsn_SBWM "Wakeup_SBWM";
BA_ "FlexKomSigLaenge" SG_ 1033 WakeupRsn_SBWM 24;
BA_ "FlexKomSigStartPos" SG_ 1033 WakeupRsn_SBWM 39;
BA_ "FlexKomSID" SG_ 1033 WakeupRsn_SBWM 1371;
BA_ "GenSigStartValue" SG_ 1033 WakeupRsn_SBWM 255;
BA_ "FlexKomSigStartValue" SG_ 1033 WakeupRsn_SBWM "FFFF00h";
BA_ "GenSigSNA" SG_ 1033 WakeupCnt_SBWM "FFh";
BA_ "FlexKomIsMotorola" SG_ 1033 WakeupCnt_SBWM 1;
BA_ "FlexKomComment" SG_ 1033 WakeupCnt_SBWM "Mode 2 of NM_Ud_Srv";
BA_ "FlexKomSigName" SG_ 1033 WakeupCnt_SBWM "Wakeup_SBWM";
BA_ "FlexKomSigLaenge" SG_ 1033 WakeupCnt_SBWM 24;
BA_ "FlexKomSigStartPos" SG_ 1033 WakeupCnt_SBWM 39;
BA_ "FlexKomSID" SG_ 1033 WakeupCnt_SBWM 1371;
BA_ "GenSigStartValue" SG_ 1033 WakeupCnt_SBWM 255;
BA_ "FlexKomSigStartValue" SG_ 1033 WakeupCnt_SBWM "FFFF00h";
BA_ "GenSigSNA" SG_ 1033 Nw_Id_SBWM "FFh";
BA_ "FlexKomIsMotorola" SG_ 1033 Nw_Id_SBWM 1;
BA_ "FlexKomComment" SG_ 1033 Nw_Id_SBWM "Network identification no.";
BA_ "FlexKomSigName" SG_ 1033 Nw_Id_SBWM "Nw_Id";
BA_ "FlexKomSigLaenge" SG_ 1033 Nw_Id_SBWM 8;
BA_ "FlexKomSigStartPos" SG_ 1033 Nw_Id_SBWM 63;
BA_ "FlexKomSID" SG_ 1033 Nw_Id_SBWM 535;
BA_ "GenSigStartValue" SG_ 1033 Nw_Id_SBWM 255;
BA_ "FlexKomSigStartValue" SG_ 1033 Nw_Id_SBWM "FFh";
BA_ "GenSigSNA" SG_ 1033 NM_Ud_Srv_SBWM "FFh";
BA_ "FlexKomIsMotorola" SG_ 1033 NM_Ud_Srv_SBWM 1;
BA_ "FlexKomComment" SG_ 1033 NM_Ud_Srv_SBWM "Network management state";
BA_ "FlexKomSigName" SG_ 1033 NM_Ud_Srv_SBWM "NM";
BA_ "FlexKomSigLaenge" SG_ 1033 NM_Ud_Srv_SBWM 32;
BA_ "FlexKomSigStartPos" SG_ 1033 NM_Ud_Srv_SBWM 7;
BA_ "FlexKomSID" SG_ 1033 NM_Ud_Srv_SBWM 472;
BA_ "GenSigStartValue" SG_ 1033 NM_Ud_Srv_SBWM 255;
BA_ "FlexKomSigStartValue" SG_ 1033 NM_Ud_Srv_SBWM "FFFFFFFFh";
BA_ "GenSigSNA" SG_ 1033 NM_Ud_Launch_SBWM "3Fh";
BA_ "FlexKomIsMotorola" SG_ 1033 NM_Ud_Launch_SBWM 1;
BA_ "FlexKomComment" SG_ 1033 NM_Ud_Launch_SBWM "Network management state";
BA_ "FlexKomSigName" SG_ 1033 NM_Ud_Launch_SBWM "NM";
BA_ "FlexKomSigLaenge" SG_ 1033 NM_Ud_Launch_SBWM 32;
BA_ "FlexKomSigStartPos" SG_ 1033 NM_Ud_Launch_SBWM 7;
BA_ "FlexKomSID" SG_ 1033 NM_Ud_Launch_SBWM 472;
BA_ "GenSigStartValue" SG_ 1033 NM_Ud_Launch_SBWM 63;
BA_ "FlexKomSigStartValue" SG_ 1033 NM_Ud_Launch_SBWM "FFFFFFFFh";
BA_ "GenSigSNA" SG_ 1033 NM_Successor_SBWM "FFh";
BA_ "FlexKomIsMotorola" SG_ 1033 NM_Successor_SBWM 1;
BA_ "FlexKomComment" SG_ 1033 NM_Successor_SBWM "Network management state";
BA_ "FlexKomSigName" SG_ 1033 NM_Successor_SBWM "NM";
BA_ "FlexKomSigLaenge" SG_ 1033 NM_Successor_SBWM 32;
BA_ "FlexKomSigStartPos" SG_ 1033 NM_Successor_SBWM 7;
BA_ "FlexKomSID" SG_ 1033 NM_Successor_SBWM 472;
BA_ "GenSigStartValue" SG_ 1033 NM_Successor_SBWM 255;
BA_ "FlexKomSigStartValue" SG_ 1033 NM_Successor_SBWM "FFFFFFFFh";
BA_ "GenSigSNA" SG_ 1033 NM_Sleep_Ind_SBWM "1h";
BA_ "FlexKomIsMotorola" SG_ 1033 NM_Sleep_Ind_SBWM 1;
BA_ "FlexKomComment" SG_ 1033 NM_Sleep_Ind_SBWM "Network management state";
BA_ "FlexKomSigName" SG_ 1033 NM_Sleep_Ind_SBWM "NM";
BA_ "FlexKomSigLaenge" SG_ 1033 NM_Sleep_Ind_SBWM 32;
BA_ "FlexKomSigStartPos" SG_ 1033 NM_Sleep_Ind_SBWM 7;
BA_ "FlexKomSID" SG_ 1033 NM_Sleep_Ind_SBWM 472;
BA_ "GenSigStartValue" SG_ 1033 NM_Sleep_Ind_SBWM 1;
BA_ "FlexKomSigStartValue" SG_ 1033 NM_Sleep_Ind_SBWM "FFFFFFFFh";
BA_ "GenSigSNA" SG_ 1033 NM_Sleep_Ack_SBWM "1h";
BA_ "FlexKomIsMotorola" SG_ 1033 NM_Sleep_Ack_SBWM 1;
BA_ "FlexKomComment" SG_ 1033 NM_Sleep_Ack_SBWM "Network management state";
BA_ "FlexKomSigName" SG_ 1033 NM_Sleep_Ack_SBWM "NM";
BA_ "FlexKomSigLaenge" SG_ 1033 NM_Sleep_Ack_SBWM 32;
BA_ "FlexKomSigStartPos" SG_ 1033 NM_Sleep_Ack_SBWM 7;
BA_ "FlexKomSID" SG_ 1033 NM_Sleep_Ack_SBWM 472;
BA_ "GenSigStartValue" SG_ 1033 NM_Sleep_Ack_SBWM 1;
BA_ "FlexKomSigStartValue" SG_ 1033 NM_Sleep_Ack_SBWM "FFFFFFFFh";
BA_ "GenSigSNA" SG_ 1033 NM_Mode_SBWM "FFh";
BA_ "FlexKomIsMotorola" SG_ 1033 NM_Mode_SBWM 1;
BA_ "FlexKomComment" SG_ 1033 NM_Mode_SBWM "Network management state";
BA_ "FlexKomSigName" SG_ 1033 NM_Mode_SBWM "NM";
BA_ "FlexKomSigLaenge" SG_ 1033 NM_Mode_SBWM 32;
BA_ "FlexKomSigStartPos" SG_ 1033 NM_Mode_SBWM 7;
BA_ "FlexKomSID" SG_ 1033 NM_Mode_SBWM 472;
BA_ "GenSigStartValue" SG_ 1033 NM_Mode_SBWM 255;
BA_ "FlexKomSigStartValue" SG_ 1033 NM_Mode_SBWM "FFFFFFFFh";
BA_ "GenSigSNA" SG_ 1033 Awake_URS_SBWM "0h";
BA_ "FlexKomIsMotorola" SG_ 1033 Awake_URS_SBWM 1;
BA_ "FlexKomComment" SG_ 1033 Awake_URS_SBWM "Mode 15 of NM_Ud_Srv";
BA_ "FlexKomSigName" SG_ 1033 Awake_URS_SBWM "Awake_SBWM";
BA_ "FlexKomSigLaenge" SG_ 1033 Awake_URS_SBWM 24;
BA_ "FlexKomSigStartPos" SG_ 1033 Awake_URS_SBWM 39;
BA_ "FlexKomSID" SG_ 1033 Awake_URS_SBWM 1370;
BA_ "FlexKomSigStartValue" SG_ 1033 Awake_URS_SBWM "000000h";
BA_ "GenSigSNA" SG_ 1033 Awake_NwSt_SBWM "0h";
BA_ "FlexKomIsMotorola" SG_ 1033 Awake_NwSt_SBWM 1;
BA_ "FlexKomComment" SG_ 1033 Awake_NwSt_SBWM "Mode 15 of NM_Ud_Srv";
BA_ "FlexKomSigName" SG_ 1033 Awake_NwSt_SBWM "Awake_SBWM";
BA_ "FlexKomSigLaenge" SG_ 1033 Awake_NwSt_SBWM 24;
BA_ "FlexKomSigStartPos" SG_ 1033 Awake_NwSt_SBWM 39;
BA_ "FlexKomSID" SG_ 1033 Awake_NwSt_SBWM 1370;
BA_ "FlexKomSigStartValue" SG_ 1033 Awake_NwSt_SBWM "000000h";
BA_ "GenSigSNA" SG_ 1033 Awake_Ignition_On_SBWM "0h";
BA_ "FlexKomIsMotorola" SG_ 1033 Awake_Ignition_On_SBWM 1;
BA_ "FlexKomComment" SG_ 1033 Awake_Ignition_On_SBWM "Mode 15 of NM_Ud_Srv";
BA_ "FlexKomSigName" SG_ 1033 Awake_Ignition_On_SBWM "Awake_SBWM";
BA_ "FlexKomSigLaenge" SG_ 1033 Awake_Ignition_On_SBWM 24;
BA_ "FlexKomSigStartPos" SG_ 1033 Awake_Ignition_On_SBWM 39;
BA_ "FlexKomSID" SG_ 1033 Awake_Ignition_On_SBWM 1370;
BA_ "FlexKomSigStartValue" SG_ 1033 Awake_Ignition_On_SBWM "000000h";
BA_ "GenSigSNA" SG_ 1033 Awake_EEPROM_SBWM "0h";
BA_ "FlexKomIsMotorola" SG_ 1033 Awake_EEPROM_SBWM 1;
BA_ "FlexKomComment" SG_ 1033 Awake_EEPROM_SBWM "Mode 15 of NM_Ud_Srv";
BA_ "FlexKomSigName" SG_ 1033 Awake_EEPROM_SBWM "Awake_SBWM";
BA_ "FlexKomSigLaenge" SG_ 1033 Awake_EEPROM_SBWM 24;
BA_ "FlexKomSigStartPos" SG_ 1033 Awake_EEPROM_SBWM 39;
BA_ "FlexKomSID" SG_ 1033 Awake_EEPROM_SBWM 1370;
BA_ "FlexKomSigStartValue" SG_ 1033 Awake_EEPROM_SBWM "000000h";
BA_ "GenSigSNA" SG_ 1033 Awake_Diag_Actv_SBWM "0h";
BA_ "FlexKomIsMotorola" SG_ 1033 Awake_Diag_Actv_SBWM 1;
BA_ "FlexKomComment" SG_ 1033 Awake_Diag_Actv_SBWM "Mode 15 of NM_Ud_Srv";
BA_ "FlexKomSigName" SG_ 1033 Awake_Diag_Actv_SBWM "Awake_SBWM";
BA_ "FlexKomSigLaenge" SG_ 1033 Awake_Diag_Actv_SBWM 24;
BA_ "FlexKomSigStartPos" SG_ 1033 Awake_Diag_Actv_SBWM 39;
BA_ "FlexKomSID" SG_ 1033 Awake_Diag_Actv_SBWM 1370;
BA_ "FlexKomSigStartValue" SG_ 1033 Awake_Diag_Actv_SBWM "000000h";
BA_ "GenMsgStartValue" BO_ 1031 "FFFFFFFF000000FFh";
BA_ "GenMsgNrOfRepetitions" BO_ 1031 2;
BA_ "GenMsgDelayTime" BO_ 1031 20;
BA_ "NWM-Botschaft" BO_ 1031 1;
BA_ "GenSigSNA" SG_ 1031 WakeupRsn_ESC "FFh";
BA_ "FlexKomIsMotorola" SG_ 1031 WakeupRsn_ESC 1;
BA_ "FlexKomComment" SG_ 1031 WakeupRsn_ESC "Mode 2 of NM_Ud_Srv";
BA_ "FlexKomSigName" SG_ 1031 WakeupRsn_ESC "Wakeup_ESC";
BA_ "FlexKomSigLaenge" SG_ 1031 WakeupRsn_ESC 24;
BA_ "FlexKomSigStartPos" SG_ 1031 WakeupRsn_ESC 39;
BA_ "FlexKomSID" SG_ 1031 WakeupRsn_ESC 962;
BA_ "GenSigStartValue" SG_ 1031 WakeupRsn_ESC 255;
BA_ "FlexKomSigStartValue" SG_ 1031 WakeupRsn_ESC "FFFF00h";
BA_ "GenSigSNA" SG_ 1031 WakeupCnt_ESC "FFh";
BA_ "FlexKomIsMotorola" SG_ 1031 WakeupCnt_ESC 1;
BA_ "FlexKomComment" SG_ 1031 WakeupCnt_ESC "Mode 2 of NM_Ud_Srv";
BA_ "FlexKomSigName" SG_ 1031 WakeupCnt_ESC "Wakeup_ESC";
BA_ "FlexKomSigLaenge" SG_ 1031 WakeupCnt_ESC 24;
BA_ "FlexKomSigStartPos" SG_ 1031 WakeupCnt_ESC 39;
BA_ "FlexKomSID" SG_ 1031 WakeupCnt_ESC 962;
BA_ "GenSigStartValue" SG_ 1031 WakeupCnt_ESC 255;
BA_ "FlexKomSigStartValue" SG_ 1031 WakeupCnt_ESC "FFFF00h";
BA_ "GenSigSNA" SG_ 1031 Nw_Id_ESC "FFh";
BA_ "FlexKomIsMotorola" SG_ 1031 Nw_Id_ESC 1;
BA_ "FlexKomComment" SG_ 1031 Nw_Id_ESC "Network identification no.";
BA_ "FlexKomSigName" SG_ 1031 Nw_Id_ESC "Nw_Id";
BA_ "FlexKomSigLaenge" SG_ 1031 Nw_Id_ESC 8;
BA_ "FlexKomSigStartPos" SG_ 1031 Nw_Id_ESC 63;
BA_ "FlexKomSID" SG_ 1031 Nw_Id_ESC 535;
BA_ "GenSigStartValue" SG_ 1031 Nw_Id_ESC 255;
BA_ "FlexKomSigStartValue" SG_ 1031 Nw_Id_ESC "FFh";
BA_ "GenSigSNA" SG_ 1031 NM_Ud_Srv_ESC "FFh";
BA_ "FlexKomIsMotorola" SG_ 1031 NM_Ud_Srv_ESC 1;
BA_ "FlexKomComment" SG_ 1031 NM_Ud_Srv_ESC "Network management state";
BA_ "FlexKomSigName" SG_ 1031 NM_Ud_Srv_ESC "NM";
BA_ "FlexKomSigLaenge" SG_ 1031 NM_Ud_Srv_ESC 32;
BA_ "FlexKomSigStartPos" SG_ 1031 NM_Ud_Srv_ESC 7;
BA_ "FlexKomSID" SG_ 1031 NM_Ud_Srv_ESC 472;
BA_ "GenSigStartValue" SG_ 1031 NM_Ud_Srv_ESC 255;
BA_ "FlexKomSigStartValue" SG_ 1031 NM_Ud_Srv_ESC "FFFFFFFFh";
BA_ "GenSigSNA" SG_ 1031 NM_Ud_Launch_ESC "3Fh";
BA_ "FlexKomIsMotorola" SG_ 1031 NM_Ud_Launch_ESC 1;
BA_ "FlexKomComment" SG_ 1031 NM_Ud_Launch_ESC "Network management state";
BA_ "FlexKomSigName" SG_ 1031 NM_Ud_Launch_ESC "NM";
BA_ "FlexKomSigLaenge" SG_ 1031 NM_Ud_Launch_ESC 32;
BA_ "FlexKomSigStartPos" SG_ 1031 NM_Ud_Launch_ESC 7;
BA_ "FlexKomSID" SG_ 1031 NM_Ud_Launch_ESC 472;
BA_ "GenSigStartValue" SG_ 1031 NM_Ud_Launch_ESC 63;
BA_ "FlexKomSigStartValue" SG_ 1031 NM_Ud_Launch_ESC "FFFFFFFFh";
BA_ "GenSigSNA" SG_ 1031 NM_Successor_ESC "FFh";
BA_ "FlexKomIsMotorola" SG_ 1031 NM_Successor_ESC 1;
BA_ "FlexKomComment" SG_ 1031 NM_Successor_ESC "Network management state";
BA_ "FlexKomSigName" SG_ 1031 NM_Successor_ESC "NM";
BA_ "FlexKomSigLaenge" SG_ 1031 NM_Successor_ESC 32;
BA_ "FlexKomSigStartPos" SG_ 1031 NM_Successor_ESC 7;
BA_ "FlexKomSID" SG_ 1031 NM_Successor_ESC 472;
BA_ "GenSigStartValue" SG_ 1031 NM_Successor_ESC 255;
BA_ "FlexKomSigStartValue" SG_ 1031 NM_Successor_ESC "FFFFFFFFh";
BA_ "GenSigSNA" SG_ 1031 NM_Sleep_Ind_ESC "1h";
BA_ "FlexKomIsMotorola" SG_ 1031 NM_Sleep_Ind_ESC 1;
BA_ "FlexKomComment" SG_ 1031 NM_Sleep_Ind_ESC "Network management state";
BA_ "FlexKomSigName" SG_ 1031 NM_Sleep_Ind_ESC "NM";
BA_ "FlexKomSigLaenge" SG_ 1031 NM_Sleep_Ind_ESC 32;
BA_ "FlexKomSigStartPos" SG_ 1031 NM_Sleep_Ind_ESC 7;
BA_ "FlexKomSID" SG_ 1031 NM_Sleep_Ind_ESC 472;
BA_ "GenSigStartValue" SG_ 1031 NM_Sleep_Ind_ESC 1;
BA_ "FlexKomSigStartValue" SG_ 1031 NM_Sleep_Ind_ESC "FFFFFFFFh";
BA_ "GenSigSNA" SG_ 1031 NM_Sleep_Ack_ESC "1h";
BA_ "FlexKomIsMotorola" SG_ 1031 NM_Sleep_Ack_ESC 1;
BA_ "FlexKomComment" SG_ 1031 NM_Sleep_Ack_ESC "Network management state";
BA_ "FlexKomSigName" SG_ 1031 NM_Sleep_Ack_ESC "NM";
BA_ "FlexKomSigLaenge" SG_ 1031 NM_Sleep_Ack_ESC 32;
BA_ "FlexKomSigStartPos" SG_ 1031 NM_Sleep_Ack_ESC 7;
BA_ "FlexKomSID" SG_ 1031 NM_Sleep_Ack_ESC 472;
BA_ "GenSigStartValue" SG_ 1031 NM_Sleep_Ack_ESC 1;
BA_ "FlexKomSigStartValue" SG_ 1031 NM_Sleep_Ack_ESC "FFFFFFFFh";
BA_ "GenSigSNA" SG_ 1031 NM_Mode_ESC "FFh";
BA_ "FlexKomIsMotorola" SG_ 1031 NM_Mode_ESC 1;
BA_ "FlexKomComment" SG_ 1031 NM_Mode_ESC "Network management state";
BA_ "FlexKomSigName" SG_ 1031 NM_Mode_ESC "NM";
BA_ "FlexKomSigLaenge" SG_ 1031 NM_Mode_ESC 32;
BA_ "FlexKomSigStartPos" SG_ 1031 NM_Mode_ESC 7;
BA_ "FlexKomSID" SG_ 1031 NM_Mode_ESC 472;
BA_ "GenSigStartValue" SG_ 1031 NM_Mode_ESC 255;
BA_ "FlexKomSigStartValue" SG_ 1031 NM_Mode_ESC "FFFFFFFFh";
BA_ "GenSigSNA" SG_ 1031 Awake_Vehicle_Speed_ESC "0h";
BA_ "FlexKomIsMotorola" SG_ 1031 Awake_Vehicle_Speed_ESC 1;
BA_ "FlexKomComment" SG_ 1031 Awake_Vehicle_Speed_ESC "Mode 15 of NM_Ud_Srv";
BA_ "FlexKomSigName" SG_ 1031 Awake_Vehicle_Speed_ESC "Awake_ESC";
BA_ "FlexKomSigLaenge" SG_ 1031 Awake_Vehicle_Speed_ESC 24;
BA_ "FlexKomSigStartPos" SG_ 1031 Awake_Vehicle_Speed_ESC 39;
BA_ "FlexKomSID" SG_ 1031 Awake_Vehicle_Speed_ESC 961;
BA_ "FlexKomSigStartValue" SG_ 1031 Awake_Vehicle_Speed_ESC "000000h";
BA_ "GenSigSNA" SG_ 1031 Awake_NwSt_ESC "0h";
BA_ "FlexKomIsMotorola" SG_ 1031 Awake_NwSt_ESC 1;
BA_ "FlexKomComment" SG_ 1031 Awake_NwSt_ESC "Mode 15 of NM_Ud_Srv";
BA_ "FlexKomSigName" SG_ 1031 Awake_NwSt_ESC "Awake_ESC";
BA_ "FlexKomSigLaenge" SG_ 1031 Awake_NwSt_ESC 24;
BA_ "FlexKomSigStartPos" SG_ 1031 Awake_NwSt_ESC 39;
BA_ "FlexKomSID" SG_ 1031 Awake_NwSt_ESC 961;
BA_ "FlexKomSigStartValue" SG_ 1031 Awake_NwSt_ESC "000000h";
BA_ "GenSigSNA" SG_ 1031 Awake_Hardwire_Ignition_ESC "0h";
BA_ "FlexKomIsMotorola" SG_ 1031 Awake_Hardwire_Ignition_ESC 1;
BA_ "FlexKomComment" SG_ 1031 Awake_Hardwire_Ignition_ESC "Mode 15 of NM_Ud_Srv";
BA_ "FlexKomSigName" SG_ 1031 Awake_Hardwire_Ignition_ESC "Awake_ESC";
BA_ "FlexKomSigLaenge" SG_ 1031 Awake_Hardwire_Ignition_ESC 24;
BA_ "FlexKomSigStartPos" SG_ 1031 Awake_Hardwire_Ignition_ESC 39;
BA_ "FlexKomSID" SG_ 1031 Awake_Hardwire_Ignition_ESC 961;
BA_ "FlexKomSigStartValue" SG_ 1031 Awake_Hardwire_Ignition_ESC "000000h";
BA_ "GenSigSNA" SG_ 1031 Awake_EPB_Switch_Wakeup_ESC "0h";
BA_ "FlexKomIsMotorola" SG_ 1031 Awake_EPB_Switch_Wakeup_ESC 1;
BA_ "FlexKomComment" SG_ 1031 Awake_EPB_Switch_Wakeup_ESC "Mode 15 of NM_Ud_Srv";
BA_ "FlexKomSigName" SG_ 1031 Awake_EPB_Switch_Wakeup_ESC "Awake_ESC";
BA_ "FlexKomSigLaenge" SG_ 1031 Awake_EPB_Switch_Wakeup_ESC 24;
BA_ "FlexKomSigStartPos" SG_ 1031 Awake_EPB_Switch_Wakeup_ESC 39;
BA_ "FlexKomSID" SG_ 1031 Awake_EPB_Switch_Wakeup_ESC 961;
BA_ "FlexKomSigStartValue" SG_ 1031 Awake_EPB_Switch_Wakeup_ESC "000000h";
BA_ "GenSigSNA" SG_ 1031 Awake_Diag_Actv_ESC "0h";
BA_ "FlexKomIsMotorola" SG_ 1031 Awake_Diag_Actv_ESC 1;
BA_ "FlexKomComment" SG_ 1031 Awake_Diag_Actv_ESC "Mode 15 of NM_Ud_Srv";
BA_ "FlexKomSigName" SG_ 1031 Awake_Diag_Actv_ESC "Awake_ESC";
BA_ "FlexKomSigLaenge" SG_ 1031 Awake_Diag_Actv_ESC 24;
BA_ "FlexKomSigStartPos" SG_ 1031 Awake_Diag_Actv_ESC 39;
BA_ "FlexKomSID" SG_ 1031 Awake_Diag_Actv_ESC 961;
BA_ "FlexKomSigStartValue" SG_ 1031 Awake_Diag_Actv_ESC "000000h";
BA_ "GenSigSNA" SG_ 1031 Awake_Brake_Pedal_Pressed_ESC "0h";
BA_ "FlexKomIsMotorola" SG_ 1031 Awake_Brake_Pedal_Pressed_ESC 1;
BA_ "FlexKomComment" SG_ 1031 Awake_Brake_Pedal_Pressed_ESC "Mode 15 of NM_Ud_Srv";
BA_ "FlexKomSigName" SG_ 1031 Awake_Brake_Pedal_Pressed_ESC "Awake_ESC";
BA_ "FlexKomSigLaenge" SG_ 1031 Awake_Brake_Pedal_Pressed_ESC 24;
BA_ "FlexKomSigStartPos" SG_ 1031 Awake_Brake_Pedal_Pressed_ESC 39;
BA_ "FlexKomSID" SG_ 1031 Awake_Brake_Pedal_Pressed_ESC 961;
BA_ "FlexKomSigStartValue" SG_ 1031 Awake_Brake_Pedal_Pressed_ESC "000000h";
BA_ "NWM-Stationsadresse" BU_ SCCM 35;
BA_ "NWM-Knoten" BU_ SCCM 1;
BA_ "NWM-Knoten" BU_ RF_HUB 1;
BA_ "NWM-Stationsadresse" BU_ IC 2;
BA_ "NWM-Knoten" BU_ IC 1;
BA_ "NWM-Stationsadresse" BU_ HCP 58;
BA_ "NWM-Knoten" BU_ HCP 1;
BA_ "NWM-Stationsadresse" BU_ ESM 9;
BA_ "NWM-Knoten" BU_ ESM 1;
BA_ "NWM-Stationsadresse" BU_ ESC 7;
BA_ "NWM-Knoten" BU_ ESC 1;
BA_ "NWM-Stationsadresse" BU_ EPS 26;
BA_ "NWM-Knoten" BU_ EPS 1;
BA_ "NWM-Stationsadresse" BU_ EBCM 59;
BA_ "NWM-Knoten" BU_ EBCM 1;
BA_ "NWM-Stationsadresse" BU_ CBC 1;
BA_ "NWM-Knoten" BU_ CBC 1;
VAL_ 1100 VC_VehCfg6_Stat 3 "SNA" 2 "REQUEST_DATA" 1 "PROGAMMED" 0 "NA" ;
VAL_ 1100 VC_TireCircumfFT 65535 "SNA" ;
VAL_ 1100 VC_Strng_Rt_Mns5 255 "SNA" ;
VAL_ 1100 VC_Strng_Rt_Mns4 255 "SNA" ;
VAL_ 1100 VC_Strng_Rt_Mns3 255 "SNA" ;
VAL_ 1100 VC_Strng_Rt_Mns2 255 "SNA" ;
VAL_ 1100 VC_Strng_Rt_Mns1 255 "SNA" ;
VAL_ 1100 VC_BrkTyp 7 "SNA" 3 "MB" 2 "CB" 1 "PB" 0 "SMALL" ;
VAL_ 1100 VC_AnlgDrSnsr 3 "ALL" 2 "FT" 1 "DRV" 0 "NONE" ;
VAL_ 1098 VC_VehCfg5_Stat 3 "SNA" 2 "REQUEST_DATA" 1 "PROGAMMED" 0 "NA" ;
VAL_ 1098 VC_Strng_Rt_pls5 255 "SNA" ;
VAL_ 1098 VC_Strng_Rt_pls4 255 "SNA" ;
VAL_ 1098 VC_Strng_Rt_pls3 255 "SNA" ;
VAL_ 1098 VC_Strng_Rt_pls2 255 "SNA" ;
VAL_ 1098 VC_Strng_Rt_pls1 255 "SNA" ;
VAL_ 1098 VC_Strng_Rt_0 255 "SNA" ;
VAL_ 1098 VC_AmbTempLct 3 "SNA" 1 "DCM" 0 "CBC" ;
VAL_ 1059 WakeupRsn_SCCM 255 "SNA" 76 "STW_SW" 73 "HRN_SW" 72 "FP_LVR" 71 "TILT" 0 "NETWORK" ;
VAL_ 1059 WakeupCnt_SCCM 255 "SNA" ;
VAL_ 1059 Nw_Id_SCCM 255 "SNA" 2 "AUDIO_TELE" 1 "BODY" 0 "POWERTRAIN" ;
VAL_ 1059 NM_Ud_Srv_SCCM 255 "NO_USER_DATA" 15 "AWAKE_BC" 2 "WAKEUP_SA" ;
VAL_ 1059 NM_Ud_Launch_SCCM 63 "SNA" 4 "BROADCAST" ;
VAL_ 1059 NM_Successor_SCCM 255 "SNA" ;
VAL_ 1059 NM_Mode_SCCM 255 "SNA" 254 "ALIVE" 253 "RING" 252 "LHOM" ;
VAL_ 1050 WakeupRsn_EPS 255 "SNA" 1 "IGN" 0 "NETWORK" ;
VAL_ 1050 WakeupCnt_EPS 255 "SNA" ;
VAL_ 1050 Nw_Id_EPS 255 "SNA" 2 "AUDIO_TELE" 1 "BODY" 0 "POWERTRAIN" ;
VAL_ 1050 NM_Ud_Srv_EPS 255 "NO_USER_DATA" 15 "AWAKE_BC" 2 "WAKEUP_SA" ;
VAL_ 1050 NM_Ud_Launch_EPS 63 "SNA" 4 "BROADCAST" ;
VAL_ 1050 NM_Successor_EPS 255 "SNA" ;
VAL_ 1050 NM_Mode_EPS 255 "SNA" 254 "ALIVE" 253 "RING" 252 "LHOM" ;
VAL_ 1033 WakeupRsn_SBWM 255 "SNA" 1 "UNLK_R_S" 0 "NETWORK" ;
VAL_ 1033 WakeupCnt_SBWM 255 "SNA" ;
VAL_ 1033 Nw_Id_SBWM 255 "SNA" 2 "AUDIO_TELE" 1 "BODY" 0 "POWERTRAIN" ;
VAL_ 1033 NM_Ud_Srv_SBWM 255 "NO_USER_DATA" 15 "AWAKE_BC" 2 "WAKEUP_SA" ;
VAL_ 1033 NM_Ud_Launch_SBWM 63 "SNA" 4 "BROADCAST" ;
VAL_ 1033 NM_Successor_SBWM 255 "SNA" ;
VAL_ 1033 NM_Mode_SBWM 255 "SNA" 254 "ALIVE" 253 "RING" 252 "LHOM" ;
VAL_ 1031 WakeupRsn_ESC 255 "SNA" 7 "IGN" 6 "DIAG" 5 "SWU" 4 "T_RECLAMP" 3 "RA_RECLAMP" 2 "VEH_SPD" 1 "BP" 0 "NETWORK" ;
VAL_ 1031 WakeupCnt_ESC 255 "SNA" ;
VAL_ 1031 Nw_Id_ESC 255 "SNA" 2 "AUDIO_TELE" 1 "BODY" 0 "POWERTRAIN" ;
VAL_ 1031 NM_Ud_Srv_ESC 255 "NO_USER_DATA" 15 "AWAKE_BC" 2 "WAKEUP_SA" ;
VAL_ 1031 NM_Ud_Launch_ESC 63 "SNA" 4 "BROADCAST" ;
VAL_ 1031 NM_Successor_ESC 255 "SNA" ;
VAL_ 1031 NM_Mode_ESC 255 "SNA" 254 "ALIVE" 253 "RING" 252 "LHOM" ;
